VERSION ""

NS_ :

BS_:

BU_: TESTECU BIANSUXIANG SCR EBSECU DisPlay EngineECU

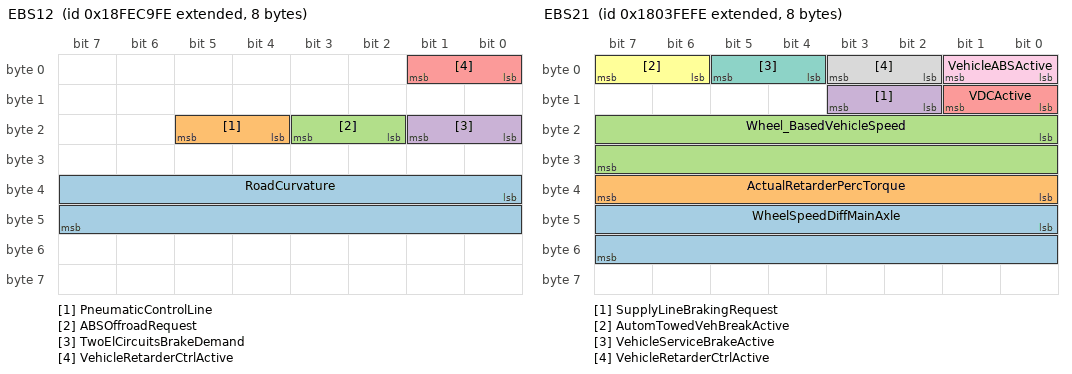
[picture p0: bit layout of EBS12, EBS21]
BO_ 2566834686 EBS12: 8 Vector__XXX
 SG_ RoadCurvature : 32|16@1+ (0.0078125,-250) [-250|251.992] "1/km" Vector__XXX
 SG_ PneumaticControlLine : 20|2@1+ (1,0) [0|1] "" Vector__XXX
 SG_ ABSOffroadRequest : 18|2@1+ (1,0) [0|1] "" Vector__XXX
 SG_ TwoElCircuitsBrakeDemand : 16|2@1+ (1,0) [0|1] "" Vector__XXX
 SG_ VehicleRetarderCtrlActive : 0|2@1+ (1,0) [0|3] "" Vector__XXX

BO_ 2550398718 EBS21: 8 Vector__XXX
 SG_ WheelSpeedDiffMainAxle : 40|16@1+ (0.00390625,-125) [-125|125] "km/hr" Vector__XXX
 SG_ ActualRetarderPercTorque : 32|8@1+ (1,-125) [-125|125] "%" Vector__XXX
 SG_ Wheel_BasedVehicleSpeed : 16|16@1+ (0.00390625,0) [0|251] "km/hr" Vector__XXX
 SG_ SupplyLineBrakingRequest : 10|2@1+ (1,0) [0|1] "" Vector__XXX
 SG_ VDCActive : 8|2@1+ (1,0) [0|1] "" Vector__XXX
 SG_ AutomTowedVehBreakActive : 6|2@1+ (1,0) [0|1] "" Vector__XXX
 SG_ VehicleServiceBrakeActive : 4|2@1+ (1,0) [0|1] "" Vector__XXX
 SG_ VehicleRetarderCtrlActive : 2|2@1+ (1,0) [0|3] "" Vector__XXX
 SG_ VehicleABSActive : 0|2@1+ (1,0) [0|1] "" Vector__XXX

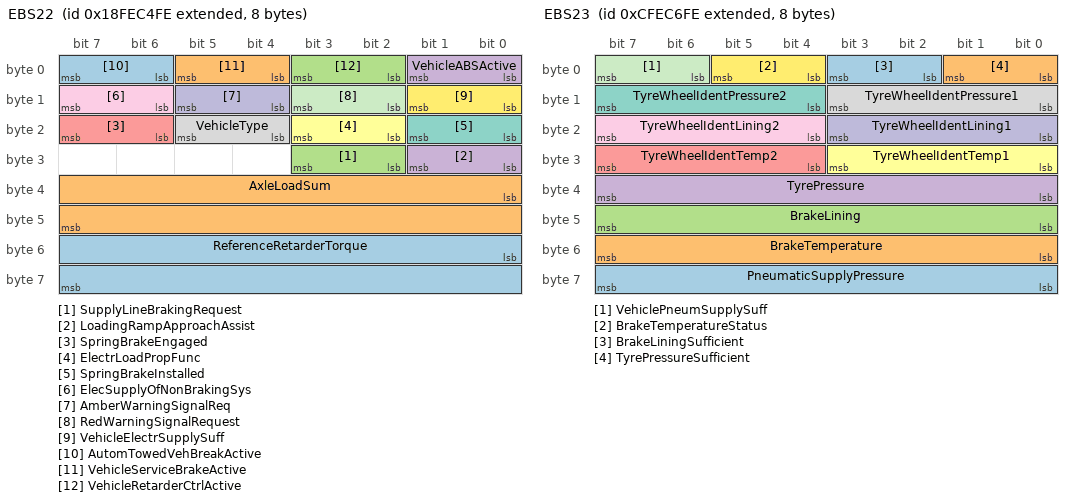
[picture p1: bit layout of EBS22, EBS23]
BO_ 2566833406 EBS22: 8 Vector__XXX
 SG_ ReferenceRetarderTorque : 48|16@1+ (1,0) [0|64255] "Nm" Vector__XXX
 SG_ AxleLoadSum : 32|16@1+ (2,0) [0|128510] "kg" Vector__XXX
 SG_ SupplyLineBrakingRequest : 26|2@1+ (1,0) [0|1] "" Vector__XXX
 SG_ LoadingRampApproachAssist : 24|2@1+ (1,0) [0|1] "" Vector__XXX
 SG_ SpringBrakeEngaged : 22|2@1+ (1,0) [0|1] "" Vector__XXX
 SG_ ElectrLoadPropFunc : 18|2@1+ (1,0) [0|1] "" Vector__XXX
 SG_ SpringBrakeInstalled : 16|2@1+ (1,0) [0|1] "" Vector__XXX
 SG_ VehicleType : 20|2@1+ (1,0) [0|3] "" Vector__XXX
 SG_ ElecSupplyOfNonBrakingSys : 14|2@1+ (1,0) [0|1] "" Vector__XXX
 SG_ AmberWarningSignalReq : 12|2@1+ (1,0) [0|1] "" Vector__XXX
 SG_ RedWarningSignalRequest : 10|2@1+ (1,0) [0|1] "" Vector__XXX
 SG_ VehicleElectrSupplySuff : 8|2@1+ (1,0) [0|1] "" Vector__XXX
 SG_ AutomTowedVehBreakActive : 6|2@1+ (1,0) [0|1] "" Vector__XXX
 SG_ VehicleServiceBrakeActive : 4|2@1+ (1,0) [0|1] "" Vector__XXX
 SG_ VehicleRetarderCtrlActive : 2|2@1+ (1,0) [0|3] "" Vector__XXX
 SG_ VehicleABSActive : 0|2@1+ (1,0) [0|1] "" Vector__XXX

BO_ 2365507326 EBS23: 8 Vector__XXX
 SG_ PneumaticSupplyPressure : 56|8@1+ (5,0) [0|1250] "kPa" Vector__XXX
 SG_ BrakeTemperature : 48|8@1+ (10,0) [0|2500] "°C" Vector__XXX
 SG_ BrakeLining : 40|8@1+ (0.4,0) [0|100] "%" Vector__XXX
 SG_ TyrePressure : 32|8@1+ (10,0) [0|2500] "kPa" Vector__XXX
 SG_ TyreWheelIdentTemp2 : 28|4@1+ (1,0) [0|15] "" Vector__XXX
 SG_ TyreWheelIdentTemp1 : 24|4@1+ (1,0) [0|15] "" Vector__XXX
 SG_ TyreWheelIdentPressure2 : 12|4@1+ (1,0) [0|15] "" Vector__XXX
 SG_ TyreWheelIdentPressure1 : 8|4@1+ (1,0) [0|15] "" Vector__XXX
 SG_ TyreWheelIdentLining2 : 20|4@1+ (1,0) [0|15] "" Vector__XXX
 SG_ TyreWheelIdentLining1 : 16|4@1+ (1,0) [0|15] "" Vector__XXX
 SG_ VehiclePneumSupplySuff : 6|2@1+ (1,0) [0|1] "" Vector__XXX
 SG_ BrakeTemperatureStatus : 4|2@1+ (1,0) [0|1] "" Vector__XXX
 SG_ BrakeLiningSufficient : 2|2@1+ (1,0) [0|1] "" Vector__XXX
 SG_ TyrePressureSufficient : 0|2@1+ (1,0) [0|1] "" Vector__XXX

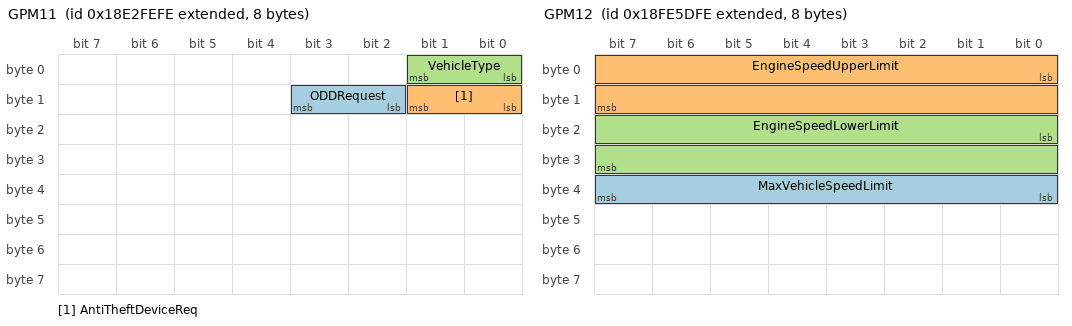
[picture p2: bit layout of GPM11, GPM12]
BO_ 2565013246 GPM11: 8 Vector__XXX
 SG_ ODDRequest : 10|2@1+ (1,0) [0|3] "" Vector__XXX
 SG_ AntiTheftDeviceReq : 8|2@1+ (1,0) [0|3] "" Vector__XXX
 SG_ VehicleType : 0|2@1+ (1,0) [0|3] "" Vector__XXX

BO_ 2566807038 GPM12: 8 Vector__XXX
 SG_ MaxVehicleSpeedLimit : 32|8@1+ (1,0) [0|250] "km/h" Vector__XXX
 SG_ EngineSpeedUpperLimit : 0|16@1+ (0.125,0) [0|8031.875] "rpm" Vector__XXX
 SG_ EngineSpeedLowerLimit : 16|16@1+ (0.125,0) [0|8191.875] "rpm" Vector__XXX

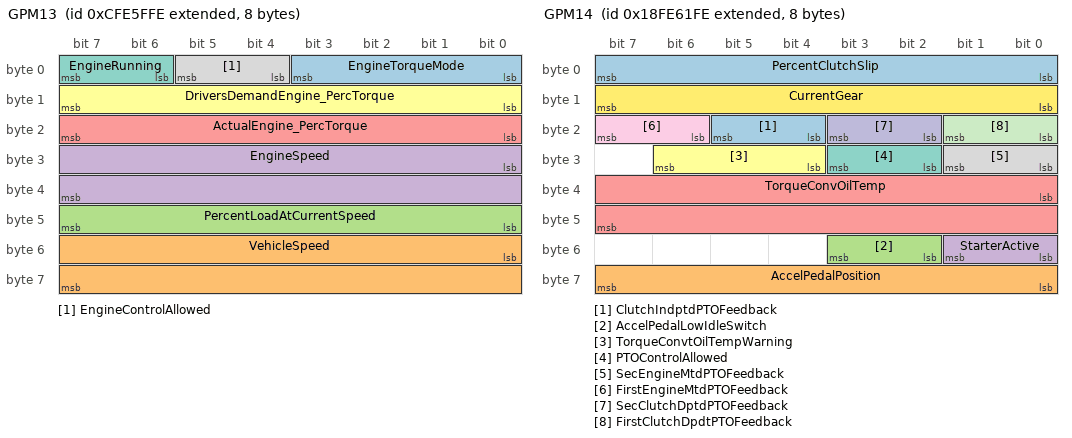
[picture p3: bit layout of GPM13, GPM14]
BO_ 2365480958 GPM13: 8 Vector__XXX
 SG_ EngineTorqueMode : 0|4@1+ (1,0) [0|15] "" Vector__XXX
 SG_ VehicleSpeed : 48|16@1+ (0.00390625,0) [0|250.996] "km/hr" Vector__XXX
 SG_ PercentLoadAtCurrentSpeed : 40|8@1+ (1,0) [0|125] "%" Vector__XXX
 SG_ EngineSpeed : 24|16@1+ (0.125,0) [0|8031.88] "rpm" Vector__XXX
 SG_ ActualEngine_PercTorque : 16|8@1+ (1,-125) [-125|125] "%" Vector__XXX
 SG_ DriversDemandEngine_PercTorque : 8|8@1+ (1,-125) [-125|125] "%" Vector__XXX
 SG_ EngineRunning : 6|2@1+ (1,0) [0|1] "" Vector__XXX
 SG_ EngineControlAllowed : 4|2@1+ (1,0) [0|1] "" Vector__XXX

BO_ 2566808062 GPM14: 8 Vector__XXX
 SG_ ClutchIndptdPTOFeedback : 20|2@1+ (1,0) [0|1] "" Vector__XXX
 SG_ AccelPedalPosition : 56|8@1+ (0.4,0) [0|100] "%" Vector__XXX
 SG_ AccelPedalLowIdleSwitch : 50|2@1+ (1,0) [0|1] "" Vector__XXX
 SG_ StarterActive : 48|2@1+ (1,0) [0|1] "" Vector__XXX
 SG_ TorqueConvOilTemp : 32|16@1+ (0.03125,-273) [-273|1735] "°C" Vector__XXX
 SG_ TorqueConvtOilTempWarning : 28|3@1+ (1,0) [0|2] "" Vector__XXX
 SG_ PTOControlAllowed : 26|2@1+ (1,0) [0|1] "" Vector__XXX
 SG_ SecEngineMtdPTOFeedback : 24|2@1+ (1,0) [0|1] "" Vector__XXX
 SG_ FirstEngineMtdPTOFeedback : 22|2@1+ (1,0) [0|1] "" Vector__XXX
 SG_ SecClutchDptdPTOFeedback : 18|2@1+ (1,0) [0|1] "" Vector__XXX
 SG_ FirstClutchDpdtPTOFeedback : 16|2@1+ (1,0) [0|1] "" Vector__XXX
 SG_ CurrentGear : 8|8@1+ (1,-125) [-125|125] "" Vector__XXX
 SG_ PercentClutchSlip : 0|8@1+ (0.4,0) [0|100] "%" Vector__XXX

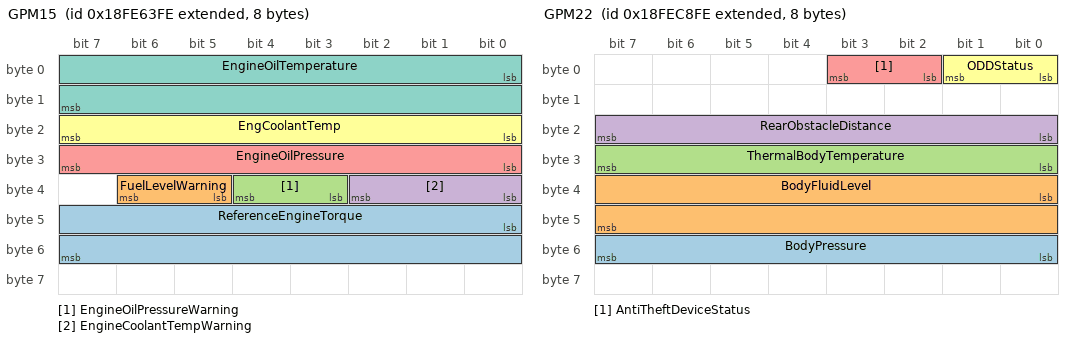
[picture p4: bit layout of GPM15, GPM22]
BO_ 2566808574 GPM15: 8 Vector__XXX
 SG_ ReferenceEngineTorque : 40|16@1+ (1,0) [0|64255] "Nm" Vector__XXX
 SG_ FuelLevelWarning : 37|2@1+ (1,0) [0|1] "" Vector__XXX
 SG_ EngineOilPressureWarning : 35|2@1+ (1,0) [0|1] "" Vector__XXX
 SG_ EngineCoolantTempWarning : 32|3@1+ (1,0) [0|2] "" Vector__XXX
 SG_ EngineOilPressure : 24|8@1+ (4,0) [0|1000] "kPa" Vector__XXX
 SG_ EngCoolantTemp : 16|8@1+ (1,-40) [-40|210] "deg C" Vector__XXX
 SG_ EngineOilTemperature : 0|16@1+ (0.03125,-273) [-273|1735] "°C" Vector__XXX

BO_ 2566809086 GPM16: 8 Vector__XXX
 SG_ AmbientAirTemperature : 0|16@1+ (0.03125,-273) [-273|1735] "°C" Vector__XXX

BO_ 2564947710 GPM21: 8 Vector__XXX
 SG_ VehicleType : 0|2@1+ (1,0) [0|3] "" Vector__XXX

BO_ 2566834430 GPM22: 8 Vector__XXX
 SG_ BodyPressure : 48|8@1+ (0.1,0) [0|25] "bar" Vector__XXX
 SG_ BodyFluidLevel : 32|16@1+ (2,0) [0|128510] "L" Vector__XXX
 SG_ ThermalBodyTemperature : 24|8@1+ (1,-125) [-125|125] "°C" Vector__XXX
 SG_ RearObstacleDistance : 16|8@1+ (2,0) [0|500] "cm" Vector__XXX
 SG_ AntiTheftDeviceStatus : 2|2@1+ (1,0) [0|1] "" Vector__XXX
 SG_ ODDStatus : 0|2@1+ (1,0) [0|1] "" Vector__XXX

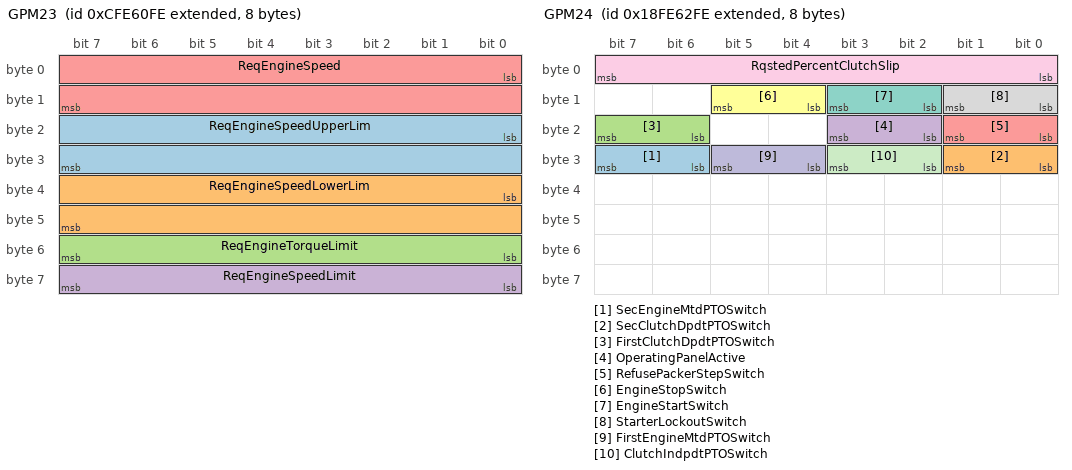
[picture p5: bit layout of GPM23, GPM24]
BO_ 2365481214 GPM23: 8 Vector__XXX
 SG_ ReqEngineSpeedUpperLim : 16|16@1+ (0.125,0) [0|8031.875] "rpm" Vector__XXX
 SG_ ReqEngineSpeedLowerLim : 32|16@1+ (0.125,0) [0|8031.875] "rpm" Vector__XXX
 SG_ ReqEngineTorqueLimit : 48|8@1+ (1,-125) [-125|125] "%" Vector__XXX
 SG_ ReqEngineSpeedLimit : 56|8@1+ (1,0) [0|250] "km/hr" Vector__XXX
 SG_ ReqEngineSpeed : 0|16@1+ (0.125,0) [0|8031.875] "rpm" Vector__XXX

BO_ 2566808318 GPM24: 8 Vector__XXX
 SG_ SecEngineMtdPTOSwitch : 30|2@1+ (1,0) [0|1] "" Vector__XXX
 SG_ SecClutchDpdtPTOSwitch : 24|2@1+ (1,0) [0|1] "" Vector__XXX
 SG_ FirstClutchDpdtPTOSwitch : 22|2@1+ (1,0) [0|1] "" Vector__XXX
 SG_ OperatingPanelActive : 18|2@1+ (1,0) [0|1] "" Vector__XXX
 SG_ RefusePackerStepSwitch : 16|2@1+ (1,0) [0|1] "" Vector__XXX
 SG_ EngineStopSwitch : 12|2@1+ (1,0) [0|1] "" Vector__XXX
 SG_ EngineStartSwitch : 10|2@1+ (1,0) [0|3] "" Vector__XXX
 SG_ StarterLockoutSwitch : 8|2@1+ (1,0) [0|1] "" Vector__XXX
 SG_ RqstedPercentClutchSlip : 0|8@1+ (0.4,0) [0|100] "%" Vector__XXX
 SG_ FirstEngineMtdPTOSwitch : 28|2@1+ (1,0) [0|1] "" Vector__XXX
 SG_ ClutchIndpdtPTOSwitch : 26|2@1+ (1,0) [0|1] "" Vector__XXX

BO_ 2566808830 GPM25: 8 Vector__XXX
 SG_ TrailerLeftSideMarkerLight : 20|2@1+ (1,0) [0|3] "" Vector__XXX
 SG_ TrailerLeftReversingLight : 16|2@1+ (1,0) [0|3] "" Vector__XXX
 SG_ TrailerLeftRearWidIndLight : 24|2@1+ (1,0) [0|3] "" Vector__XXX
 SG_ TrailerLeftRearRegPltLight : 32|2@1+ (1,0) [0|3] "" Vector__XXX
 SG_ TrailerLeftRearLight : 8|2@1+ (1,0) [0|3] "" Vector__XXX
 SG_ TrailerLeftRearFogLight : 12|2@1+ (1,0) [0|3] "" Vector__XXX
 SG_ TrailerLeftDirIndLight : 4|2@1+ (1,0) [0|3] "" Vector__XXX
 SG_ TrailerLeftCrnMarkerLight : 28|2@1+ (1,0) [0|3] "" Vector__XXX
 SG_ TrailerInteriorLight : 40|2@1+ (1,0) [0|3] "" Vector__XXX
 SG_ TrailerWorkLamp : 42|2@1+ (1,0) [0|3] "" Vector__XXX
 SG_ TrailerRotatingIdentLight : 38|2@1+ (1,0) [0|3] "" Vector__XXX
 SG_ TrailerRightStopLight : 2|2@1+ (1,0) [0|3] "" Vector__XXX
 SG_ TrailerRightSideMrkLight : 22|2@1+ (1,0) [0|3] "" Vector__XXX
 SG_ TrailerRightReversingLight : 18|2@1+ (1,0) [0|3] "" Vector__XXX
 SG_ TrailRightRearWidIndLight : 26|2@1+ (1,0) [0|3] "" Vector__XXX
 SG_ TrailerRightRearRegPltLight : 34|2@1+ (1,0) [0|3] "" Vector__XXX
 SG_ TrailerRightRearLight : 10|2@1+ (1,0) [0|3] "" Vector__XXX
 SG_ TrailerRightRearFogLight : 14|2@1+ (1,0) [0|3] "" Vector__XXX
 SG_ TrailerRightDirIndLight : 6|2@1+ (1,0) [0|3] "" Vector__XXX
 SG_ TrailerRightCrnMarkerLight : 30|2@1+ (1,0) [0|3] "" Vector__XXX
 SG_ TrailerRearWarningLight : 36|2@1+ (1,0) [0|3] "" Vector__XXX
 SG_ TrailerLeftStopLight : 0|2@1+ (1,0) [0|3] "" Vector__XXX

BO_ 2564554494 ISO15765_Funct: 8 Vector__XXX
 SG_ SN m2 : 0|4@1+ (1,0) [0|15] "" Vector__XXX
 SG_ SeparationTime m3 : 16|8@1+ (1,0) [0|255] "ms" Vector__XXX
 SG_ BlockSize m3 : 8|8@1+ (1,0) [0|255] "" Vector__XXX
 SG_ FlowStatus m3 : 0|4@1+ (1,0) [0|3] "" Vector__XXX
 SG_ FirstFrameDataLength m1 : 3|12@0+ (1,0) [0|4095] "Byte" Vector__XXX
 SG_ SingleFrameDataLength m0 : 0|4@1+ (1,0) [0|7] "Byte" Vector__XXX
 SG_ ProtocolCtrlInformation M : 4|4@1+ (1,0) [0|3] "" Vector__XXX

BO_ 2564488958 ISO15765_Phys: 8 Vector__XXX
 SG_ SN m2 : 0|4@1+ (1,0) [0|15] "" Vector__XXX
 SG_ SeparationTime m3 : 16|8@1+ (1,0) [0|255] "ms" Vector__XXX
 SG_ BlockSize m3 : 8|8@1+ (1,0) [0|255] "" Vector__XXX
 SG_ FlowStatus m3 : 0|4@1+ (1,0) [0|3] "" Vector__XXX
 SG_ FirstFrameDataLength m1 : 3|12@0+ (1,0) [0|4095] "Byte" Vector__XXX
 SG_ SingleFrameDataLength m0 : 0|4@1+ (1,0) [0|7] "Byte" Vector__XXX
 SG_ ProtocolCtrlInformation M : 4|4@1+ (1,0) [0|3] "" Vector__XXX

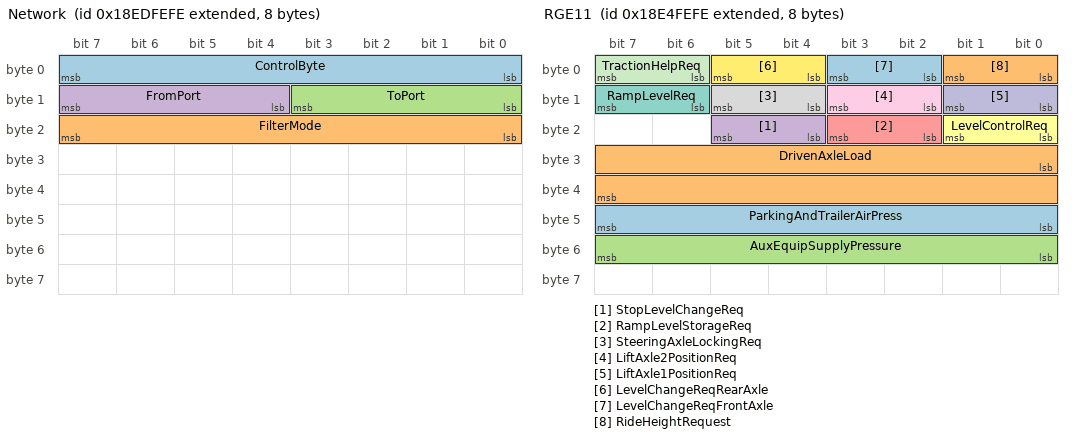
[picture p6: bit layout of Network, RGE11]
BO_ 2565734142 Network: 8 Vector__XXX
 SG_ ControlByte : 0|8@1+ (1,0) [0|255] "" Vector__XXX
 SG_ FilterMode : 16|8@1+ (1,0) [0|255] "" Vector__XXX
 SG_ ToPort : 8|4@1+ (1,0) [0|15] "" Vector__XXX
 SG_ FromPort : 12|4@1+ (1,0) [0|15] "" Vector__XXX

BO_ 2565144318 RGE11: 8 Vector__XXX
 SG_ ParkingAndTrailerAirPress : 40|8@1+ (8,0) [0|2000] "kPa" Vector__XXX
 SG_ DrivenAxleLoad : 24|16@1+ (2,0) [0|128510] "kg" Vector__XXX
 SG_ AuxEquipSupplyPressure : 48|8@1+ (8,0) [0|2000] "kPa" Vector__XXX
 SG_ StopLevelChangeReq : 20|2@1+ (1,0) [0|3] "" Vector__XXX
 SG_ RampLevelStorageReq : 18|2@1+ (1,0) [0|3] "" Vector__XXX
 SG_ LevelControlReq : 16|2@1+ (1,0) [0|3] "" Vector__XXX
 SG_ RampLevelReq : 14|2@1+ (1,0) [0|3] "" Vector__XXX
 SG_ SteeringAxleLockingReq : 12|2@1+ (1,0) [0|3] "" Vector__XXX
 SG_ LiftAxle2PositionReq : 10|2@1+ (1,0) [0|3] "" Vector__XXX
 SG_ LiftAxle1PositionReq : 8|2@1+ (1,0) [0|3] "" Vector__XXX
 SG_ TractionHelpReq : 6|2@1+ (1,0) [0|3] "" Vector__XXX
 SG_ LevelChangeReqRearAxle : 4|2@1+ (1,0) [0|3] "" Vector__XXX
 SG_ LevelChangeReqFrontAxle : 2|2@1+ (1,0) [0|3] "" Vector__XXX
 SG_ RideHeightRequest : 0|2@1+ (1,0) [0|3] "" Vector__XXX

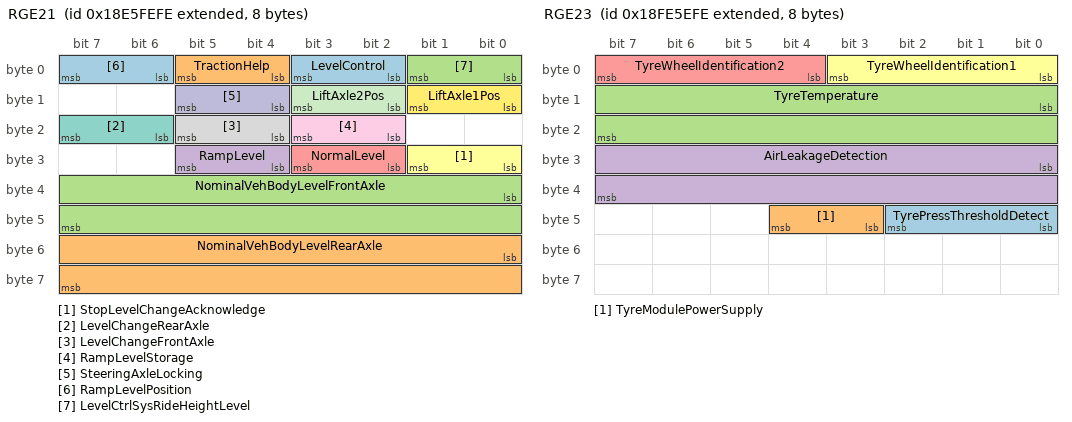
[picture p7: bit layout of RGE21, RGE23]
BO_ 2565209854 RGE21: 8 Vector__XXX
 SG_ LevelControl : 2|2@1+ (1,0) [0|1] "" Vector__XXX
 SG_ NominalVehBodyLevelRearAxle : 48|16@1+ (1,0) [0|64255] "mm" Vector__XXX
 SG_ NominalVehBodyLevelFrontAxle : 32|16@1+ (1,0) [0|64255] "mm" Vector__XXX
 SG_ RampLevel : 28|2@1+ (1,0) [0|1] "" Vector__XXX
 SG_ NormalLevel : 26|2@1+ (1,0) [0|3] "" Vector__XXX
 SG_ StopLevelChangeAcknowledge : 24|2@1+ (1,0) [0|1] "" Vector__XXX
 SG_ LevelChangeRearAxle : 22|2@1+ (1,0) [0|1] "" Vector__XXX
 SG_ LevelChangeFrontAxle : 20|2@1+ (1,0) [0|1] "" Vector__XXX
 SG_ RampLevelStorage : 18|2@1+ (1,0) [0|1] "" Vector__XXX
 SG_ SteeringAxleLocking : 12|2@1+ (1,0) [0|3] "" Vector__XXX
 SG_ LiftAxle2Pos : 10|2@1+ (1,0) [0|3] "" Vector__XXX
 SG_ LiftAxle1Pos : 8|2@1+ (1,0) [0|3] "" Vector__XXX
 SG_ RampLevelPosition : 6|2@1+ (1,0) [0|3] "" Vector__XXX
 SG_ TractionHelp : 4|2@1+ (1,0) [0|1] "" Vector__XXX
 SG_ LevelCtrlSysRideHeightLevel : 0|2@1+ (1,0) [0|1] "" Vector__XXX

BO_ 2566806782 RGE22: 8 Vector__XXX
 SG_ RelVehBodyLevelRearAxle : 16|16@1+ (1,0) [0|64255] "mm" Vector__XXX
 SG_ RelVehBodyLevelFrontAxle : 0|16@1+ (1,-32000) [-32000|32255] "mm" Vector__XXX

BO_ 2566807294 RGE23: 8 Vector__XXX
 SG_ TyrePressThresholdDetect : 40|3@1+ (1,0) [0|7] "" Vector__XXX
 SG_ TyreModulePowerSupply : 43|2@1+ (1,0) [0|1] "" Vector__XXX
 SG_ TyreTemperature : 8|16@1+ (0.03125,-273) [-273|1735] "°C" Vector__XXX
 SG_ AirLeakageDetection : 24|16@1+ (0.1,0) [0|6425.5] "Pa/s" Vector__XXX
 SG_ TyreWheelIdentification2 : 4|4@1+ (1,0) [0|15] "" Vector__XXX
 SG_ TyreWheelIdentification1 : 0|4@1+ (1,0) [0|15] "" Vector__XXX

BO_ 2566764798 DM26: 8 Vector__XXX
 SG_ NMHCConvertingCatalystCompleted : 60|1@1+ (1,0) [0|1] "" Vector__XXX
 SG_ NMHCConvertingCatalystEnabled : 44|1@1+ (1,0) [0|1] "" Vector__XXX
 SG_ NOxConvertingCatalystAdsorberCom : 59|1@1+ (1,0) [0|1] "" Vector__XXX
 SG_ NOxConvertingCatalystAdsorberEna : 43|1@1+ (1,0) [0|1] "" Vector__XXX
 SG_ DieselParticulateFilterCompleted : 58|1@1+ (1,0) [0|1] "" Vector__XXX
 SG_ DieselParticulateFilterEnabled : 42|1@1+ (1,0) [0|1] "" Vector__XXX
 SG_ BoostPressureControlSystemComple : 57|1@1+ (1,0) [0|1] "" Vector__XXX
 SG_ BoostPressureControlSystemEnable : 41|1@1- (1,0) [0|0] "" Vector__XXX
 SG_ MisfireMonitoringComplete : 28|1@1+ (1,0) [0|1] "" Vector__XXX
 SG_ MisfireMonitoringEnabled : 24|1@1+ (1,0) [0|0] "" Vector__XXX
 SG_ FuelSystemMonitoringEnabled : 25|1@1+ (1,0) [0|1] "" Vector__XXX
 SG_ ComprehensiveComptMonComplete : 30|1@1+ (1,0) [0|1] "" Vector__XXX
 SG_ ComprehensiveCompMonEnabled : 26|1@1+ (1,0) [0|1] "" Vector__XXX
 SG_ SecondAirSystemMonComplete : 51|1@1+ (1,0) [0|1] "" Vector__XXX
 SG_ SecondAirSystemMonEnabled : 35|1@1+ (1,0) [0|1] "" Vector__XXX
 SG_ OxygenSensorMonComplete : 53|1@1+ (1,0) [0|1] "" Vector__XXX
 SG_ OxygenSensorMonEnabled : 37|1@1+ (1,0) [0|1] "" Vector__XXX
 SG_ OxygenSensorHeaterMonComplete : 54|1@1+ (1,0) [0|1] "" Vector__XXX
 SG_ OxygenSensorHeaterMonEnabled : 38|1@1+ (1,0) [0|1] "" Vector__XXX
 SG_ HeatedCatalystMonComplete : 49|1@1+ (1,0) [0|1] "" Vector__XXX
 SG_ HeatedCatalystMonEnabled : 33|1@1+ (1,0) [0|1] "" Vector__XXX
 SG_ EvaporativeSystemMonComplete : 50|1@1+ (1,0) [0|1] "" Vector__XXX
 SG_ EvaporativeSystemMonEnabled : 34|1@1+ (1,0) [0|1] "" Vector__XXX
 SG_ EGRSystemMonitoringComplete : 55|1@1+ (1,0) [0|1] "" Vector__XXX
 SG_ EGRSystemMonitoringEnabled : 39|1@1+ (1,0) [0|1] "" Vector__XXX
 SG_ ColdStartAidSystemMonComplete : 56|1@1+ (1,0) [0|1] "" Vector__XXX
 SG_ ColdStartAidSystemMonEnabled : 40|1@1+ (1,0) [0|1] "" Vector__XXX
 SG_ CatalystMonComplete : 48|1@1+ (1,0) [0|1] "" Vector__XXX
 SG_ CatalystMonEnabled : 32|1@1+ (1,0) [0|1] "" Vector__XXX
 SG_ ACSystemRefrigerantMonComplete : 52|1@1+ (1,0) [0|1] "" Vector__XXX
 SG_ ACSystemRefrigerantMonEnabled : 36|1@1+ (1,0) [0|1] "" Vector__XXX
 SG_ FuelSystemMonitoringComplete : 29|1@1+ (1,0) [0|1] "" Vector__XXX
 SG_ NumOfWarmUpsSinceDTCsCleared : 16|8@1+ (1,0) [0|250] "" Vector__XXX
 SG_ TimeSinceEngineStart : 0|16@1+ (1,0) [0|64255] "sec" Vector__XXX

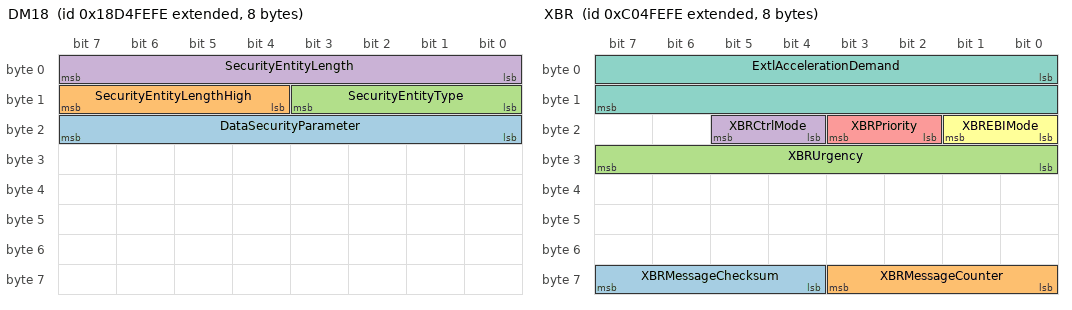
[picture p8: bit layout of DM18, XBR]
BO_ 2564095742 DM18: 8 Vector__XXX
 SG_ DataSecurityParameter : 16|8@1- (1,0) [0|1785] "" Vector__XXX
 SG_ SecurityEntityLengthHigh : 12|4@1+ (1,0) [0|255] "Byte" Vector__XXX
 SG_ SecurityEntityType : 8|4@1+ (1,0) [0|15] "" Vector__XXX
 SG_ SecurityEntityLength : 0|8@1+ (1,0) [0|1785] "Byte" Vector__XXX

BO_ 2349137662 XBR: 8 Vector__XXX
 SG_ XBRMessageChecksum : 60|4@1+ (1,0) [0|15] "" Vector__XXX
 SG_ XBRMessageCounter : 56|4@1+ (1,0) [0|15] "" Vector__XXX
 SG_ XBRUrgency : 24|8@1+ (0.4,0) [0|100] "%" Vector__XXX
 SG_ XBRCtrlMode : 20|2@1+ (1,0) [0|3] "" Vector__XXX
 SG_ XBRPriority : 18|2@1+ (1,0) [0|3] "" Vector__XXX
 SG_ XBREBIMode : 16|2@1+ (1,0) [0|3] "" Vector__XXX
 SG_ ExtlAccelerationDemand : 0|16@1+ (0.00048828125,-15.687) [-15.687|15.687] "m/s²" Vector__XXX

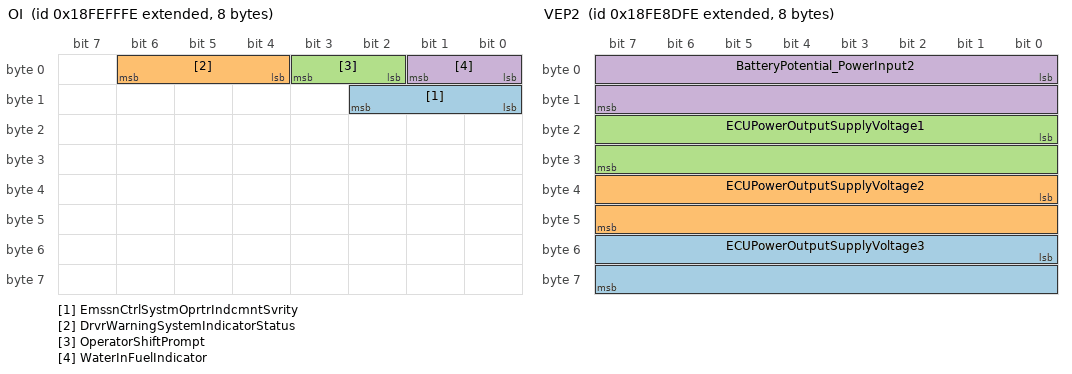
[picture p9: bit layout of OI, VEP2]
BO_ 2566848510 OI: 8 Vector__XXX
 SG_ EmssnCtrlSystmOprtrIndcmntSvrity : 8|3@1+ (1,0) [0|7] "" Vector__XXX
 SG_ DrvrWarningSystemIndicatorStatus : 4|3@1+ (1,0) [0|7] "" Vector__XXX
 SG_ OperatorShiftPrompt : 2|2@1+ (1,0) [0|3] "" Vector__XXX
 SG_ WaterInFuelIndicator : 0|2@1+ (1,0) [0|3] "" Vector__XXX

BO_ 2566843134 VW: 8 Vector__XXX
 SG_ AxleLocation M : 0|8@1+ (1,0) [0|255] "" Vector__XXX
 SG_ CargoWeight_30 m48 : 40|16@1+ (2,0) [0|128510] "kg" Vector__XXX
 SG_ CargoWeight_20 m32 : 40|16@1+ (2,0) [0|128510] "kg" Vector__XXX
 SG_ CargoWeight_10 m16 : 40|16@1+ (2,0) [0|128510] "kg" Vector__XXX
 SG_ CargoWeight_00 m0 : 40|16@1+ (2,0) [0|128510] "kg" Vector__XXX
 SG_ TrailerWeight_30 m48 : 24|16@1+ (2,0) [0|128510] "kg" Vector__XXX
 SG_ TrailerWeight_20 m32 : 24|16@1+ (2,0) [0|128510] "kg" Vector__XXX
 SG_ TrailerWeight_10 m16 : 24|16@1+ (2,0) [0|128510] "kg" Vector__XXX
 SG_ TrailerWeight_00 m0 : 24|16@1+ (2,0) [0|128510] "kg" Vector__XXX
 SG_ AxleWeight_30 m48 : 8|16@1+ (0.5,0) [0|32127.5] "kg" Vector__XXX
 SG_ AxleWeight_20 m32 : 8|16@1+ (0.5,0) [0|32127.5] "kg" Vector__XXX
 SG_ AxleWeight_10 m16 : 8|16@1+ (0.5,0) [0|32127.5] "kg" Vector__XXX
 SG_ AxleWeight_00 m0 : 8|16@1+ (0.5,0) [0|32127.5] "kg" Vector__XXX

BO_ 2566804222 VEP3: 8 Vector__XXX
 SG_ NetBatteryCurrent : 16|16@1+ (0.05,-1600) [-1600|1612.75] "A" Vector__XXX
 SG_ AltCurrent : 0|16@1+ (0.05,-1600) [-1600|1612.75] "A" Vector__XXX

BO_ 2566819326 VEP2: 8 Vector__XXX
 SG_ ECUPowerOutputSupplyVoltage3 : 48|16@1+ (0.05,0) [0|3212.75] "V" Vector__XXX
 SG_ ECUPowerOutputSupplyVoltage2 : 32|16@1+ (0.05,0) [0|3212.75] "V" Vector__XXX
 SG_ ECUPowerOutputSupplyVoltage1 : 16|16@1+ (0.05,0) [0|3212.75] "V" Vector__XXX
 SG_ BatteryPotential_PowerInput2 : 0|16@1+ (0.05,0) [0|3212.75] "V" Vector__XXX

BO_ 2566845438 VP: 8 Vector__XXX
 SG_ Longitude : 32|32@1+ (1E-007,-210) [-210|211.1008122] "deg" Vector__XXX
 SG_ Latitude : 0|32@1+ (1E-007,-210) [-210|211.1008122] "deg" Vector__XXX

BO_ 2566843646 VI: 8 Vector__XXX
 SG_ VehicleIdentificationNumber : 0|8@1+ (1,0) [0|255] "per byte" Vector__XXX

BO_ 2566842366 VH: 8 Vector__XXX
 SG_ TotalPowerTakeoffHours : 32|32@1+ (0.05,0) [0|210554060.75] "hr" Vector__XXX
 SG_ TotalVehicleHours : 0|32@1+ (0.05,0) [0|210554060.75] "hr" Vector__XXX

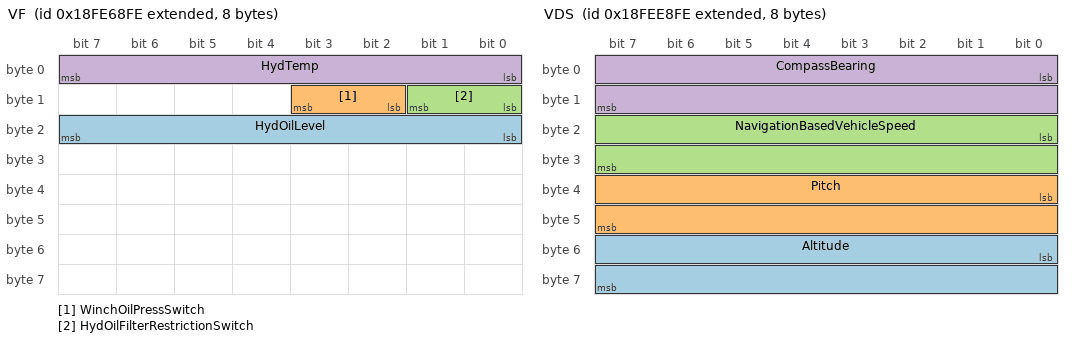
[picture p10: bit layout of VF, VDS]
BO_ 2566809854 VF: 8 Vector__XXX
 SG_ HydOilLevel : 16|8@1+ (0.4,0) [0|100] "%" Vector__XXX
 SG_ WinchOilPressSwitch : 10|2@1+ (1,0) [0|3] "" Vector__XXX
 SG_ HydOilFilterRestrictionSwitch : 8|2@1+ (1,0) [0|3] "" Vector__XXX
 SG_ HydTemp : 0|8@1+ (1,-40) [-40|210] "deg C" Vector__XXX

BO_ 2566842622 VDS: 8 Vector__XXX
 SG_ Altitude : 48|16@1+ (0.125,-2500) [-2500|5531.875] "m" Vector__XXX
 SG_ Pitch : 32|16@1+ (0.0078125,-200) [-200|301.99] "deg" Vector__XXX
 SG_ NavigationBasedVehicleSpeed : 16|16@1+ (0.00390625,0) [0|250.996] "km/h" Vector__XXX
 SG_ CompassBearing : 0|16@1+ (0.0078125,0) [0|501.99] "deg" Vector__XXX

BO_ 2566832638 VDHR: 8 Vector__XXX
 SG_ HighResolutionTripDistance : 32|32@1+ (5,0) [0|21055406] "km" Vector__XXX
 SG_ HghRsolutionTotalVehicleDistance : 0|32@1+ (5,0) [0|21055406] "km" Vector__XXX

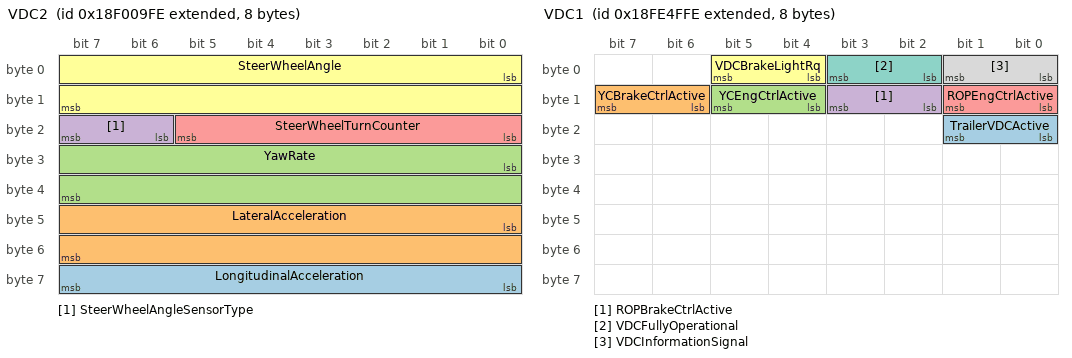
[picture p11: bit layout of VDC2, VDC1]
BO_ 2565868030 VDC2: 8 Vector__XXX
 SG_ LongitudinalAcceleration : 56|8@1+ (0.1,-12.5) [-12.5|12.5] "m/s²" Vector__XXX
 SG_ LateralAcceleration : 40|16@1+ (0.00048828125,-15.687) [-15.687|15.687] "m/s²" Vector__XXX
 SG_ YawRate : 24|16@1+ (0.0001220703125,-3.92) [-3.92|3.92] "rad/s" Vector__XXX
 SG_ SteerWheelAngleSensorType : 22|2@1+ (1,0) [0|3] "" Vector__XXX
 SG_ SteerWheelTurnCounter : 16|6@1+ (1,-32) [-32|29] "turns" Vector__XXX
 SG_ SteerWheelAngle : 0|16@1+ (0.0009765625,-31.374) [-31.374|31.374] "rad" Vector__XXX

BO_ 2566803454 VDC1: 8 Vector__XXX
 SG_ TrailerVDCActive : 16|2@1+ (1,0) [0|3] "" Vector__XXX
 SG_ YCBrakeCtrlActive : 14|2@1+ (1,0) [0|3] "" Vector__XXX
 SG_ YCEngCtrlActive : 12|2@1+ (1,0) [0|3] "" Vector__XXX
 SG_ ROPBrakeCtrlActive : 10|2@1+ (1,0) [0|3] "" Vector__XXX
 SG_ ROPEngCtrlActive : 8|2@1+ (1,0) [0|3] "" Vector__XXX
 SG_ VDCBrakeLightRq : 4|2@1+ (1,0) [0|3] "" Vector__XXX
 SG_ VDCFullyOperational : 2|2@1+ (1,0) [0|3] "" Vector__XXX
 SG_ VDCInformationSignal : 0|2@1+ (1,0) [0|3] "" Vector__XXX

BO_ 2566840574 VD: 8 Vector__XXX
 SG_ TotalVehicleDistance : 32|32@1+ (0.125,0) [0|526385151.9] "km" Vector__XXX
 SG_ TripDistance : 0|32@1+ (0.125,0) [0|526385151.9] "km" Vector__XXX

BO_ 2633938686 TVI: 8 Vector__XXX
 SG_ TripCruiseDistance : 16|32@1+ (0.125,0) [0|526385151.9] "km" Vector__XXX
 SG_ TripMaxVehicleSpeed : 0|16@1+ (0.00390625,0) [0|250.996] "km/h" Vector__XXX

BO_ 2633937150 TTI2: 20 Vector__XXX
 SG_ TripAirCompressorOnTime : 128|32@1+ (0.05,0) [0|210554060.75] "hr" Vector__XXX
 SG_ TripIdleTime : 96|32@1+ (0.05,0) [0|210554060.75] "hr" Vector__XXX
 SG_ TripEngRunningTime : 64|32@1+ (0.05,0) [0|210554060.75] "hr" Vector__XXX
 SG_ TripCruiseTime : 0|32@1+ (0.05,0) [0|210554060.75] "hr" Vector__XXX
 SG_ TripPTOGovernorTime : 32|32@1+ (0.05,0) [0|210554060.75] "hr" Vector__XXX

BO_ 2633938174 TTI1: 16 Vector__XXX
 SG_ TripTimeInDerateByEng : 96|32@1+ (0.05,0) [0|210554060.75] "hr" Vector__XXX
 SG_ TripTimeInGearDown : 64|32@1+ (0.05,0) [0|210554060.75] "hr" Vector__XXX
 SG_ TripTimeInTopGear : 32|32@1+ (0.05,0) [0|210554060.75] "hr" Vector__XXX
 SG_ TripTimeInVSL : 0|32@1+ (0.05,0) [0|210554060.75] "hr" Vector__XXX

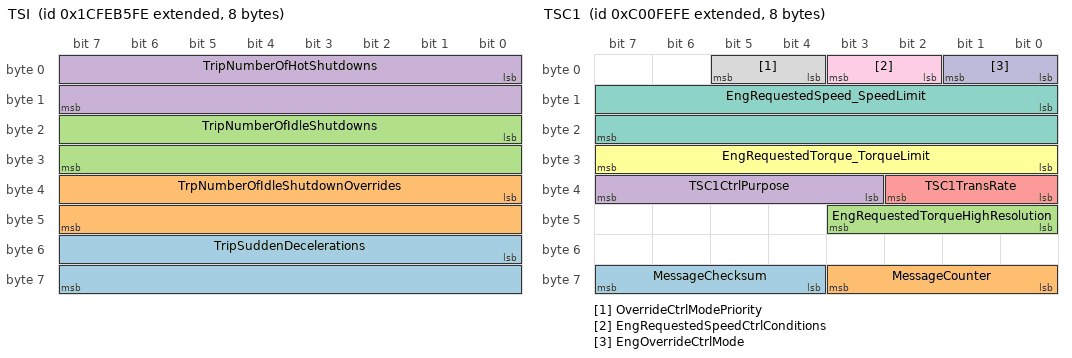
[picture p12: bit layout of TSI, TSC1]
BO_ 2633938430 TSI: 8 Vector__XXX
 SG_ TripSuddenDecelerations : 48|16@1+ (1,0) [0|64255] "" Vector__XXX
 SG_ TrpNumberOfIdleShutdownOverrides : 32|16@1+ (1,0) [0|64255] "" Vector__XXX
 SG_ TripNumberOfIdleShutdowns : 16|16@1+ (1,0) [0|64255] "" Vector__XXX
 SG_ TripNumberOfHotShutdowns : 0|16@1+ (1,0) [0|64255] "" Vector__XXX

BO_ 2348875518 TSC1: 8 Vector__XXX
 SG_ MessageChecksum : 60|4@1+ (1,0) [0|15] "" Vector__XXX
 SG_ MessageCounter : 56|4@1+ (1,0) [0|15] "" Vector__XXX
 SG_ EngRequestedTorqueHighResolution : 40|4@1+ (0.125,0) [0|0.875] "%" Vector__XXX
 SG_ TSC1CtrlPurpose : 35|5@1+ (1,0) [0|31] "" Vector__XXX
 SG_ TSC1TransRate : 32|3@1+ (1,0) [0|7] "" Vector__XXX
 SG_ EngRequestedTorque_TorqueLimit : 24|8@1+ (1,-125) [-125|125] "%" Vector__XXX
 SG_ EngRequestedSpeed_SpeedLimit : 8|16@1+ (0.125,0) [0|8031.875] "rpm" Vector__XXX
 SG_ OverrideCtrlModePriority : 4|2@1+ (1,0) [0|3] "" Vector__XXX
 SG_ EngRequestedSpeedCtrlConditions : 2|2@1+ (1,0) [0|3] "" Vector__XXX
 SG_ EngOverrideCtrlMode : 0|2@1+ (1,0) [0|3] "" Vector__XXX

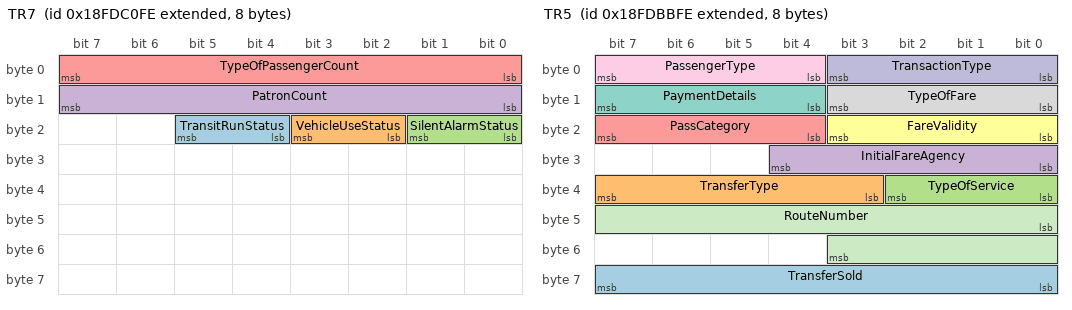
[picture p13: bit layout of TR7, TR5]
BO_ 2566766846 TR7: 8 Vector__XXX
 SG_ TransitRunStatus : 20|2@1+ (1,0) [0|3] "" Vector__XXX
 SG_ VehicleUseStatus : 18|2@1+ (1,0) [0|3] "" Vector__XXX
 SG_ SilentAlarmStatus : 16|2@1+ (1,0) [0|3] "" Vector__XXX
 SG_ PatronCount : 8|8@1+ (1,0) [0|250] "" Vector__XXX
 SG_ TypeOfPassengerCount : 0|8@1+ (1,0) [0|255] "" Vector__XXX

BO_ 2566765310 TR6: 8 Vector__XXX
 SG_ FareboxAlarmIdentifier : 8|7@1+ (1,0) [0|127] "" Vector__XXX
 SG_ FareboxEmergencyStatus : 0|2@1+ (1,0) [0|3] "" Vector__XXX

BO_ 2566765566 TR5: 8 Vector__XXX
 SG_ TransferSold : 56|8@1+ (1,0) [0|255] "" Vector__XXX
 SG_ TransferType : 35|5@1+ (1,0) [0|31] "" Vector__XXX
 SG_ TypeOfService : 32|3@1+ (1,0) [0|7] "" Vector__XXX
 SG_ InitialFareAgency : 24|5@1+ (1,0) [0|31] "" Vector__XXX
 SG_ PassCategory : 20|4@1+ (1,0) [0|15] "" Vector__XXX
 SG_ FareValidity : 16|4@1+ (1,0) [0|15] "" Vector__XXX
 SG_ PaymentDetails : 12|4@1+ (1,0) [0|15] "" Vector__XXX
 SG_ TypeOfFare : 8|4@1+ (1,0) [0|15] "" Vector__XXX
 SG_ PassengerType : 4|4@1+ (1,0) [0|15] "" Vector__XXX
 SG_ TransactionType : 0|4@1+ (1,0) [0|15] "" Vector__XXX
 SG_ RouteNumber : 40|12@1+ (1,0) [0|4095] "" Vector__XXX

BO_ 2566765822 TR4: 15 Vector__XXX
 SG_ DriversFareboxSecurityCode : 104|16@1+ (1,0) [0|65535] "" Vector__XXX
 SG_ AssignedBlock : 88|16@1+ (1,0) [0|65535] "" Vector__XXX
 SG_ AssignedRun : 72|16@1+ (1,0) [0|65535] "" Vector__XXX
 SG_ AssignedRoute : 56|16@1+ (1,0) [0|65535] "" Vector__XXX
 SG_ PatternNumber : 40|16@1+ (1,0) [0|65535] "" Vector__XXX
 SG_ TripNumber : 24|16@1+ (1,0) [0|65535] "" Vector__XXX
 SG_ FarePresets : 16|8@1+ (1,0) [0|255] "" Vector__XXX
 SG_ TripDirection : 8|4@1+ (1,0) [0|15] "" Vector__XXX
 SG_ TripStatus : 2|3@1+ (1,0) [0|7] "" Vector__XXX
 SG_ FareboxServiceStatus : 0|2@1+ (1,0) [0|3] "" Vector__XXX

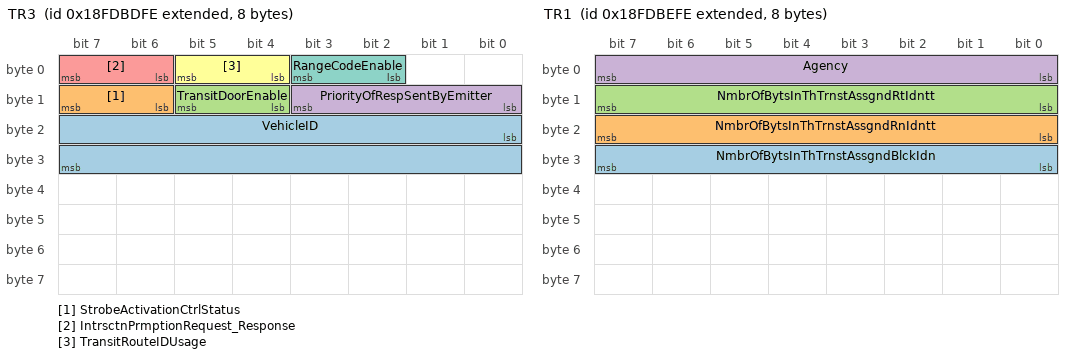
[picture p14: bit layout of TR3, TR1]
BO_ 2566766078 TR3: 8 Vector__XXX
 SG_ VehicleID : 16|16@1+ (1,0) [0|65535] "" Vector__XXX
 SG_ StrobeActivationCtrlStatus : 14|2@1+ (1,0) [0|3] "" Vector__XXX
 SG_ TransitDoorEnable : 12|2@1+ (1,0) [0|3] "" Vector__XXX
 SG_ PriorityOfRespSentByEmitter : 8|4@1+ (1,0) [0|15] "" Vector__XXX
 SG_ IntrsctnPrmptionRequest_Response : 6|2@1+ (1,0) [0|3] "" Vector__XXX
 SG_ TransitRouteIDUsage : 4|2@1+ (1,0) [0|3] "" Vector__XXX
 SG_ RangeCodeEnable : 2|2@1+ (1,0) [0|3] "" Vector__XXX

BO_ 2566766590 TR2: 8 Vector__XXX
 SG_ NmbrOfBytsInThMlpstIdntification : 0|8@1+ (1,0) [0|250] "bytes" Vector__XXX

BO_ 2566766334 TR1: 8 Vector__XXX
 SG_ NmbrOfBytsInThTrnstAssgndBlckIdn : 24|8@1+ (1,0) [0|250] "bytes" Vector__XXX
 SG_ NmbrOfBytsInThTrnstAssgndRnIdntt : 16|8@1+ (1,0) [0|250] "bytes" Vector__XXX
 SG_ NmbrOfBytsInThTrnstAssgndRtIdntt : 8|8@1+ (1,0) [0|250] "bytes" Vector__XXX
 SG_ Agency : 0|8@1+ (1,0) [0|255] "" Vector__XXX

BO_ 2561605374 TPRS: 8 Vector__XXX
 SG_ ReferenceTirePressSetting_33 m51 : 8|8@1+ (8,0) [0|2000] "kPa" Vector__XXX
 SG_ ReferenceTirePressSetting_32 m50 : 8|8@1+ (8,0) [0|2000] "kPa" Vector__XXX
 SG_ ReferenceTirePressSetting_31 m49 : 8|8@1+ (8,0) [0|2000] "kPa" Vector__XXX
 SG_ ReferenceTirePressSetting_30 m48 : 8|8@1+ (8,0) [0|2000] "kPa" Vector__XXX
 SG_ ReferenceTirePressSetting_23 m35 : 8|8@1+ (8,0) [0|2000] "kPa" Vector__XXX
 SG_ ReferenceTirePressSetting_22 m34 : 8|8@1+ (8,0) [0|2000] "kPa" Vector__XXX
 SG_ ReferenceTirePressSetting_21 m33 : 8|8@1+ (8,0) [0|2000] "kPa" Vector__XXX
 SG_ ReferenceTirePressSetting_20 m32 : 8|8@1+ (8,0) [0|2000] "kPa" Vector__XXX
 SG_ ReferenceTirePressSetting_13 m19 : 8|8@1+ (8,0) [0|2000] "kPa" Vector__XXX
 SG_ ReferenceTirePressSetting_12 m18 : 8|8@1+ (8,0) [0|2000] "kPa" Vector__XXX
 SG_ ReferenceTirePressSetting_11 m17 : 8|8@1+ (8,0) [0|2000] "kPa" Vector__XXX
 SG_ ReferenceTirePressSetting_10 m16 : 8|8@1+ (8,0) [0|2000] "kPa" Vector__XXX
 SG_ ReferenceTirePressSetting_01 m1 : 8|8@1+ (8,0) [0|2000] "kPa" Vector__XXX
 SG_ ReferenceTirePressSetting_00 m0 : 8|8@1+ (8,0) [0|2000] "kPa" Vector__XXX
 SG_ TireLocation M : 0|8@1+ (1,0) [0|255] "" Vector__XXX

BO_ 2566765054 TPRI: 8 Vector__XXX
 SG_ ReferenceTirePress_33 m51 : 8|8@1+ (8,0) [0|2000] "kPa" Vector__XXX
 SG_ ReferenceTirePress_32 m50 : 8|8@1+ (8,0) [0|2000] "kPa" Vector__XXX
 SG_ ReferenceTirePress_31 m49 : 8|8@1+ (8,0) [0|2000] "kPa" Vector__XXX
 SG_ ReferenceTirePress_30 m48 : 8|8@1+ (8,0) [0|2000] "kPa" Vector__XXX
 SG_ ReferenceTirePress_23 m35 : 8|8@1+ (8,0) [0|2000] "kPa" Vector__XXX
 SG_ ReferenceTirePress_22 m34 : 8|8@1+ (8,0) [0|2000] "kPa" Vector__XXX
 SG_ ReferenceTirePress_21 m33 : 8|8@1+ (8,0) [0|2000] "kPa" Vector__XXX
 SG_ ReferenceTirePress_20 m32 : 8|8@1+ (8,0) [0|2000] "kPa" Vector__XXX
 SG_ ReferenceTirePress_13 m19 : 8|8@1+ (8,0) [0|2000] "kPa" Vector__XXX
 SG_ ReferenceTirePress_12 m18 : 8|8@1+ (8,0) [0|2000] "kPa" Vector__XXX
 SG_ ReferenceTirePress_11 m17 : 8|8@1+ (8,0) [0|2000] "kPa" Vector__XXX
 SG_ ReferenceTirePress_10 m16 : 8|8@1+ (8,0) [0|2000] "kPa" Vector__XXX
 SG_ ReferenceTirePress_01 m1 : 8|8@1+ (8,0) [0|2000] "kPa" Vector__XXX
 SG_ ReferenceTirePress_00 m0 : 8|8@1+ (8,0) [0|2000] "kPa" Vector__XXX
 SG_ TireLocation M : 0|8@1+ (1,0) [0|255] "" Vector__XXX

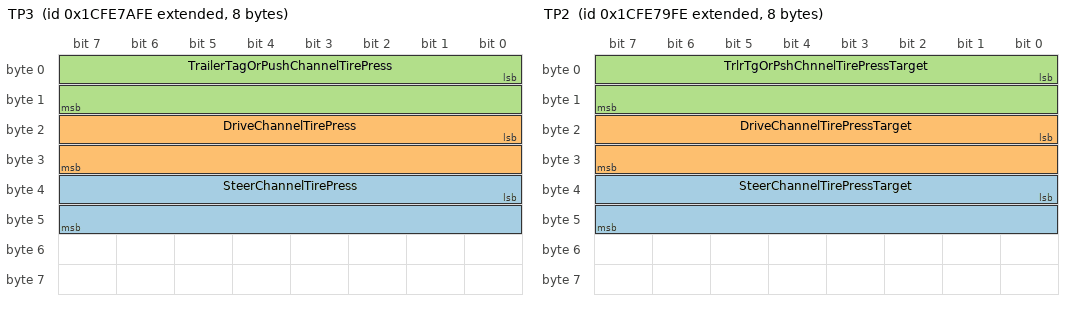
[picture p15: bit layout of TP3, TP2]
BO_ 2633923326 TP3: 8 Vector__XXX
 SG_ SteerChannelTirePress : 32|16@1+ (0.5,0) [0|32127.5] "kPa" Vector__XXX
 SG_ DriveChannelTirePress : 16|16@1+ (0.5,0) [0|32127.5] "kPa" Vector__XXX
 SG_ TrailerTagOrPushChannelTirePress : 0|16@1+ (0.5,0) [0|32127.5] "kPa" Vector__XXX

BO_ 2633923070 TP2: 8 Vector__XXX
 SG_ SteerChannelTirePressTarget : 32|16@1+ (0.5,0) [0|32127.5] "kPa" Vector__XXX
 SG_ DriveChannelTirePressTarget : 16|16@1+ (0.5,0) [0|32127.5] "kPa" Vector__XXX
 SG_ TrlrTgOrPshChnnelTirePressTarget : 0|16@1+ (0.5,0) [0|32127.5] "kPa" Vector__XXX

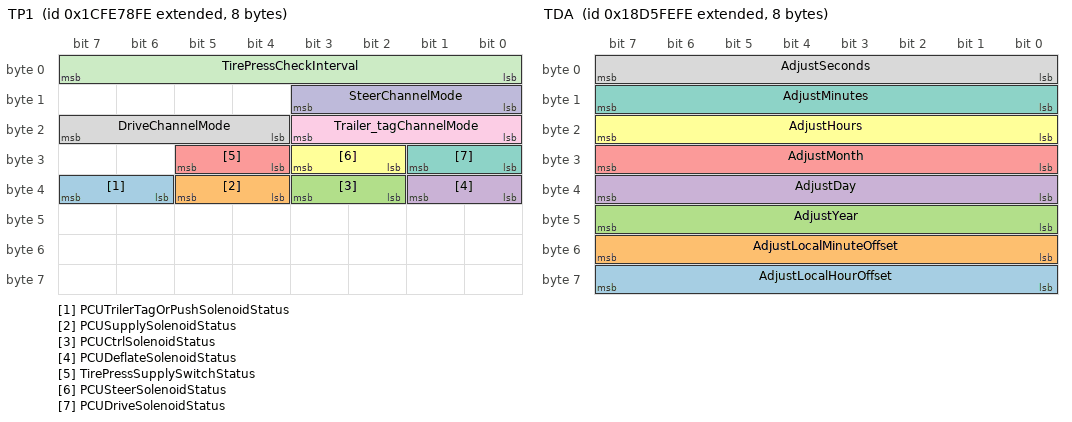
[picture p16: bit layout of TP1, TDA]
BO_ 2633922814 TP1: 8 Vector__XXX
 SG_ PCUTrilerTagOrPushSolenoidStatus : 38|2@1+ (1,0) [0|3] "" Vector__XXX
 SG_ PCUSupplySolenoidStatus : 36|2@1+ (1,0) [0|3] "" Vector__XXX
 SG_ PCUCtrlSolenoidStatus : 34|2@1+ (1,0) [0|3] "" Vector__XXX
 SG_ PCUDeflateSolenoidStatus : 32|2@1+ (1,0) [0|3] "" Vector__XXX
 SG_ TirePressSupplySwitchStatus : 28|2@1+ (1,0) [0|3] "" Vector__XXX
 SG_ PCUSteerSolenoidStatus : 26|2@1+ (1,0) [0|3] "" Vector__XXX
 SG_ PCUDriveSolenoidStatus : 24|2@1+ (1,0) [0|3] "" Vector__XXX
 SG_ DriveChannelMode : 20|4@1+ (1,0) [0|15] "" Vector__XXX
 SG_ Trailer_tagChannelMode : 16|4@1+ (1,0) [0|15] "" Vector__XXX
 SG_ SteerChannelMode : 8|4@1+ (1,0) [0|15] "" Vector__XXX
 SG_ TirePressCheckInterval : 0|8@1+ (1,0) [0|250] "mins" Vector__XXX

BO_ 2566845694 TIRE: 8 Vector__XXX
 SG_ TirePressThresholdDetection_13 m19 : 61|3@1+ (1,0) [0|7] "" Vector__XXX
 SG_ TirePressThresholdDetection_12 m18 : 61|3@1+ (1,0) [0|7] "" Vector__XXX
 SG_ TirePressThresholdDetection_11 m17 : 61|3@1+ (1,0) [0|7] "" Vector__XXX
 SG_ TirePressThresholdDetection_10 m16 : 61|3@1+ (1,0) [0|7] "" Vector__XXX
 SG_ TirePressThresholdDetection_01 m1 : 61|3@1+ (1,0) [0|7] "" Vector__XXX
 SG_ TirePress_33 m51 : 8|8@1+ (4,0) [0|1000] "kPa" Vector__XXX
 SG_ TirePress_32 m50 : 8|8@1+ (4,0) [0|1000] "kPa" Vector__XXX
 SG_ TirePress_31 m49 : 8|8@1+ (4,0) [0|1000] "kPa" Vector__XXX
 SG_ TirePress_30 m48 : 8|8@1+ (4,0) [0|1000] "kPa" Vector__XXX
 SG_ TirePress_23 m35 : 8|8@1+ (4,0) [0|1000] "kPa" Vector__XXX
 SG_ TirePress_22 m34 : 8|8@1+ (4,0) [0|1000] "kPa" Vector__XXX
 SG_ TirePress_21 m33 : 8|8@1+ (4,0) [0|1000] "kPa" Vector__XXX
 SG_ TirePress_20 m32 : 8|8@1+ (4,0) [0|1000] "kPa" Vector__XXX
 SG_ TirePress_13 m19 : 8|8@1+ (4,0) [0|1000] "kPa" Vector__XXX
 SG_ TirePress_12 m18 : 8|8@1+ (4,0) [0|1000] "kPa" Vector__XXX
 SG_ TirePress_11 m17 : 8|8@1+ (4,0) [0|1000] "kPa" Vector__XXX
 SG_ TirePress_10 m16 : 8|8@1+ (4,0) [0|1000] "kPa" Vector__XXX
 SG_ TireAirLeakageRate_33 m51 : 40|16@1+ (0.1,0) [0|6425.5] "Pa/s" Vector__XXX
 SG_ TireAirLeakageRate_32 m50 : 40|16@1+ (0.1,0) [0|6425.5] "Pa/s" Vector__XXX
 SG_ TireAirLeakageRate_31 m49 : 40|16@1+ (0.1,0) [0|6425.5] "Pa/s" Vector__XXX
 SG_ TireAirLeakageRate_30 m48 : 40|16@1+ (0.1,0) [0|6425.5] "Pa/s" Vector__XXX
 SG_ TireAirLeakageRate_23 m35 : 40|16@1+ (0.1,0) [0|6425.5] "Pa/s" Vector__XXX
 SG_ TireAirLeakageRate_22 m34 : 40|16@1+ (0.1,0) [0|6425.5] "Pa/s" Vector__XXX
 SG_ TireAirLeakageRate_21 m33 : 40|16@1+ (0.1,0) [0|6425.5] "Pa/s" Vector__XXX
 SG_ TireAirLeakageRate_20 m32 : 40|16@1+ (0.1,0) [0|6425.5] "Pa/s" Vector__XXX
 SG_ TireAirLeakageRate_13 m19 : 40|16@1+ (0.1,0) [0|6425.5] "Pa/s" Vector__XXX
 SG_ TireAirLeakageRate_12 m18 : 40|16@1+ (0.1,0) [0|6425.5] "Pa/s" Vector__XXX
 SG_ TireAirLeakageRate_11 m17 : 40|16@1+ (0.1,0) [0|6425.5] "Pa/s" Vector__XXX
 SG_ TireAirLeakageRate_10 m16 : 40|16@1+ (0.1,0) [0|6425.5] "Pa/s" Vector__XXX
 SG_ TireAirLeakageRate_01 m1 : 40|16@1+ (0.1,0) [0|6425.5] "Pa/s" Vector__XXX
 SG_ TireAirLeakageRate_00 m0 : 40|16@1+ (0.1,0) [0|6425.5] "Pa/s" Vector__XXX
 SG_ CTIWheelSensorStatus_33 m51 : 32|2@1+ (1,0) [0|3] "" Vector__XXX
 SG_ CTIWheelSensorStatus_32 m50 : 32|2@1+ (1,0) [0|3] "" Vector__XXX
 SG_ CTIWheelSensorStatus_31 m49 : 32|2@1+ (1,0) [0|3] "" Vector__XXX
 SG_ CTIWheelSensorStatus_30 m48 : 32|2@1+ (1,0) [0|3] "" Vector__XXX
 SG_ CTIWheelSensorStatus_23 m35 : 32|2@1+ (1,0) [0|3] "" Vector__XXX
 SG_ CTIWheelSensorStatus_22 m34 : 32|2@1+ (1,0) [0|3] "" Vector__XXX
 SG_ CTIWheelSensorStatus_21 m33 : 32|2@1+ (1,0) [0|3] "" Vector__XXX
 SG_ CTIWheelSensorStatus_20 m32 : 32|2@1+ (1,0) [0|3] "" Vector__XXX
 SG_ CTIWheelSensorStatus_13 m19 : 32|2@1+ (1,0) [0|3] "" Vector__XXX
 SG_ CTIWheelSensorStatus_12 m18 : 32|2@1+ (1,0) [0|3] "" Vector__XXX
 SG_ CTIWheelSensorStatus_11 m17 : 32|2@1+ (1,0) [0|3] "" Vector__XXX
 SG_ CTIWheelSensorStatus_10 m16 : 32|2@1+ (1,0) [0|3] "" Vector__XXX
 SG_ CTIWheelSensorStatus_01 m1 : 32|2@1+ (1,0) [0|3] "" Vector__XXX
 SG_ CTIWheelEndElectricalFault_33 m51 : 36|2@1+ (1,0) [0|3] "" Vector__XXX
 SG_ CTIWheelEndElectricalFault_32 m50 : 36|2@1+ (1,0) [0|3] "" Vector__XXX
 SG_ CTIWheelEndElectricalFault_31 m49 : 36|2@1+ (1,0) [0|3] "" Vector__XXX
 SG_ CTIWheelEndElectricalFault_30 m48 : 36|2@1+ (1,0) [0|3] "" Vector__XXX
 SG_ CTIWheelEndElectricalFault_23 m35 : 36|2@1+ (1,0) [0|3] "" Vector__XXX
 SG_ CTIWheelEndElectricalFault_22 m34 : 36|2@1+ (1,0) [0|3] "" Vector__XXX
 SG_ CTIWheelEndElectricalFault_21 m33 : 36|2@1+ (1,0) [0|3] "" Vector__XXX
 SG_ CTIWheelEndElectricalFault_20 m32 : 36|2@1+ (1,0) [0|3] "" Vector__XXX
 SG_ CTIWheelEndElectricalFault_13 m19 : 36|2@1+ (1,0) [0|3] "" Vector__XXX
 SG_ CTIWheelEndElectricalFault_12 m18 : 36|2@1+ (1,0) [0|3] "" Vector__XXX
 SG_ CTIWheelEndElectricalFault_11 m17 : 36|2@1+ (1,0) [0|3] "" Vector__XXX
 SG_ CTIWheelEndElectricalFault_10 m16 : 36|2@1+ (1,0) [0|3] "" Vector__XXX
 SG_ CTIWheelEndElectricalFault_01 m1 : 36|2@1+ (1,0) [0|3] "" Vector__XXX
 SG_ CTITireStatus_33 m51 : 34|2@1+ (1,0) [0|3] "" Vector__XXX
 SG_ CTITireStatus_32 m50 : 34|2@1+ (1,0) [0|3] "" Vector__XXX
 SG_ CTITireStatus_31 m49 : 34|2@1+ (1,0) [0|3] "" Vector__XXX
 SG_ CTITireStatus_30 m48 : 34|2@1+ (1,0) [0|3] "" Vector__XXX
 SG_ CTITireStatus_23 m35 : 34|2@1+ (1,0) [0|3] "" Vector__XXX
 SG_ CTITireStatus_22 m34 : 34|2@1+ (1,0) [0|3] "" Vector__XXX
 SG_ CTITireStatus_21 m33 : 34|2@1+ (1,0) [0|3] "" Vector__XXX
 SG_ CTITireStatus_20 m32 : 34|2@1+ (1,0) [0|3] "" Vector__XXX
 SG_ CTITireStatus_13 m19 : 34|2@1+ (1,0) [0|3] "" Vector__XXX
 SG_ CTITireStatus_12 m18 : 34|2@1+ (1,0) [0|3] "" Vector__XXX
 SG_ CTITireStatus_11 m17 : 34|2@1+ (1,0) [0|3] "" Vector__XXX
 SG_ CTITireStatus_10 m16 : 34|2@1+ (1,0) [0|3] "" Vector__XXX
 SG_ CTITireStatus_01 m1 : 34|2@1+ (1,0) [0|3] "" Vector__XXX
 SG_ TireTemp_11 m17 : 16|16@1+ (0.03125,-273) [-273|1735] "°C" Vector__XXX
 SG_ TireTemp_33 m51 : 16|16@1+ (0.03125,-273) [-273|1735] "°C" Vector__XXX
 SG_ TireTemp_32 m50 : 16|16@1+ (0.03125,-273) [-273|1735] "°C" Vector__XXX
 SG_ TireTemp_31 m49 : 16|16@1+ (0.03125,-273) [-273|1735] "°C" Vector__XXX
 SG_ TireTemp_30 m48 : 16|16@1+ (0.03125,-273) [-273|1735] "°C" Vector__XXX
 SG_ TireTemp_23 m35 : 16|16@1+ (0.03125,-273) [-273|1735] "°C" Vector__XXX
 SG_ TireTemp_22 m34 : 16|16@1+ (0.03125,-273) [-273|1735] "°C" Vector__XXX
 SG_ TireTemp_21 m33 : 16|16@1+ (0.03125,-273) [-273|1735] "°C" Vector__XXX
 SG_ TireTemp_20 m32 : 16|16@1+ (0.03125,-273) [-273|1735] "°C" Vector__XXX
 SG_ TireTemp_13 m19 : 16|16@1+ (0.03125,-273) [-273|1735] "°C" Vector__XXX
 SG_ TireTemp_12 m18 : 16|16@1+ (0.03125,-273) [-273|1735] "°C" Vector__XXX
 SG_ TireTemp_10 m16 : 16|16@1+ (0.03125,-273) [-273|1735] "°C" Vector__XXX
 SG_ TireTemp_01 m1 : 16|16@1+ (0.03125,-273) [-273|1735] "°C" Vector__XXX
 SG_ TireTemp_00 m0 : 16|16@1+ (0.03125,-273) [-273|1735] "°C" Vector__XXX
 SG_ TirePressThresholdDetection_33 m51 : 61|3@1+ (1,0) [0|7] "" Vector__XXX
 SG_ TirePressThresholdDetection_32 m50 : 61|3@1+ (1,0) [0|7] "" Vector__XXX
 SG_ TirePressThresholdDetection_31 m49 : 61|3@1+ (1,0) [0|7] "" Vector__XXX
 SG_ TirePressThresholdDetection_30 m48 : 61|3@1+ (1,0) [0|7] "" Vector__XXX
 SG_ TirePressThresholdDetection_23 m35 : 61|3@1+ (1,0) [0|7] "" Vector__XXX
 SG_ TirePressThresholdDetection_22 m34 : 61|3@1+ (1,0) [0|7] "" Vector__XXX
 SG_ TirePressThresholdDetection_21 m33 : 61|3@1+ (1,0) [0|7] "" Vector__XXX
 SG_ TirePressThresholdDetection_20 m32 : 61|3@1+ (1,0) [0|7] "" Vector__XXX
 SG_ TirePressThresholdDetection_00 m0 : 61|3@1+ (1,0) [0|7] "" Vector__XXX
 SG_ TirePress_01 m1 : 8|8@1+ (4,0) [0|1000] "kPa" Vector__XXX
 SG_ TirePress_00 m0 : 8|8@1+ (4,0) [0|1000] "kPa" Vector__XXX
 SG_ CTIWheelSensorStatus_00 m0 : 32|2@1+ (1,0) [0|3] "" Vector__XXX
 SG_ CTIWheelEndElectricalFault_00 m0 : 36|2@1+ (1,0) [0|3] "" Vector__XXX
 SG_ CTITireStatus_00 m0 : 34|2@1+ (1,0) [0|3] "" Vector__XXX
 SG_ TireLocation M : 0|8@1+ (1,0) [0|255] "" Vector__XXX

BO_ 2633939966 TFI: 16 Vector__XXX
 SG_ TripFanOnTimeDueToTheA_CSystem : 96|32@1+ (0.05,0) [0|210554060.75] "hr" Vector__XXX
 SG_ TripFanOnTimeDueToAManualSwitch : 64|32@1+ (0.05,0) [0|210554060.75] "hr" Vector__XXX
 SG_ TripFanOnTimeDueToTheEngSystem : 32|32@1+ (0.05,0) [0|210554060.75] "hr" Vector__XXX
 SG_ TripFanOnTime : 0|32@1+ (0.05,0) [0|210554060.75] "hr" Vector__XXX

BO_ 2633939710 TDI: 12 Vector__XXX
 SG_ TripDistanceInTopGear : 64|32@1+ (0.125,0) [0|526385151.9] "km" Vector__XXX
 SG_ TripGearDownDistance : 32|32@1+ (0.125,0) [0|526385151.9] "km" Vector__XXX
 SG_ TripDistanceOnVSL : 0|32@1+ (0.125,0) [0|526385151.9] "km" Vector__XXX

BO_ 2564161278 TDA: 8 Vector__XXX
 SG_ AdjustLocalHourOffset : 56|8@1+ (1,-125) [-125|125] "hr" Vector__XXX
 SG_ AdjustLocalMinuteOffset : 48|8@1+ (1,-125) [-125|125] "mins" Vector__XXX
 SG_ AdjustYear : 40|8@1+ (1,1985) [1985|2235] "years" Vector__XXX
 SG_ AdjustDay : 32|8@1+ (0.25,0) [0|62.5] "days" Vector__XXX
 SG_ AdjustMonth : 24|8@1+ (1,0) [0|250] "months" Vector__XXX
 SG_ AdjustHours : 16|8@1+ (1,0) [0|250] "hr" Vector__XXX
 SG_ AdjustMinutes : 8|8@1+ (1,0) [0|250] "mins" Vector__XXX
 SG_ AdjustSeconds : 0|8@1+ (0.25,0) [0|62.5] "s" Vector__XXX

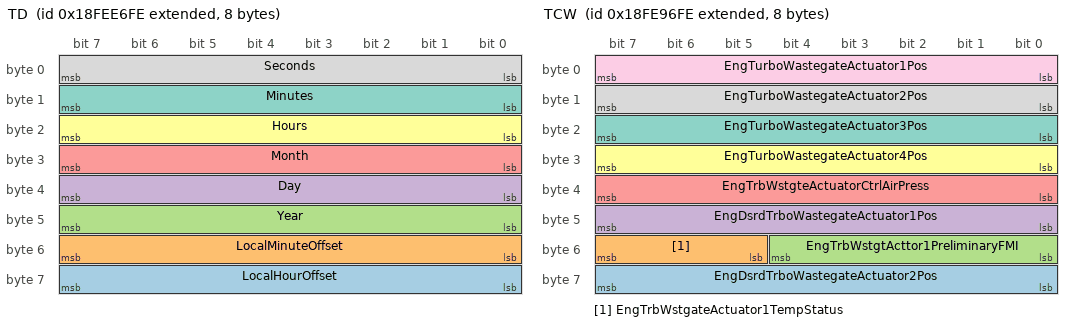
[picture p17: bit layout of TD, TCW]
BO_ 2566842110 TD: 8 Vector__XXX
 SG_ LocalHourOffset : 56|8@1+ (1,-125) [-125|125] "hr" Vector__XXX
 SG_ LocalMinuteOffset : 48|8@1+ (1,-125) [-125|125] "mins" Vector__XXX
 SG_ Year : 40|8@1+ (1,1985) [1985|2235] "years" Vector__XXX
 SG_ Day : 32|8@1+ (0.25,0) [0|62.5] "days" Vector__XXX
 SG_ Month : 24|8@1+ (1,0) [0|250] "months" Vector__XXX
 SG_ Hours : 16|8@1+ (1,0) [0|250] "hr" Vector__XXX
 SG_ Minutes : 8|8@1+ (1,0) [0|250] "mins" Vector__XXX
 SG_ Seconds : 0|8@1+ (0.25,0) [0|62.5] "s" Vector__XXX

BO_ 2566821630 TCW: 8 Vector__XXX
 SG_ EngDsrdTrboWastegateActuator2Pos : 56|8@1+ (0.4,0) [0|100] "%" Vector__XXX
 SG_ EngTrbWstgateActuator1TempStatus : 53|3@1+ (1,0) [0|7] "" Vector__XXX
 SG_ EngTrbWstgtActtor1PreliminaryFMI : 48|5@1+ (1,0) [0|31] "" Vector__XXX
 SG_ EngDsrdTrboWastegateActuator1Pos : 40|8@1+ (0.4,0) [0|100] "%" Vector__XXX
 SG_ EngTrbWstgteActuatorCtrlAirPress : 32|8@1+ (4,0) [0|1000] "kPa" Vector__XXX
 SG_ EngTurboWastegateActuator4Pos : 24|8@1+ (0.4,0) [0|100] "%" Vector__XXX
 SG_ EngTurboWastegateActuator3Pos : 16|8@1+ (0.4,0) [0|100] "%" Vector__XXX
 SG_ EngTurboWastegateActuator2Pos : 8|8@1+ (0.4,0) [0|100] "%" Vector__XXX
 SG_ EngTurboWastegateActuator1Pos : 0|8@1+ (0.4,0) [0|100] "%" Vector__XXX

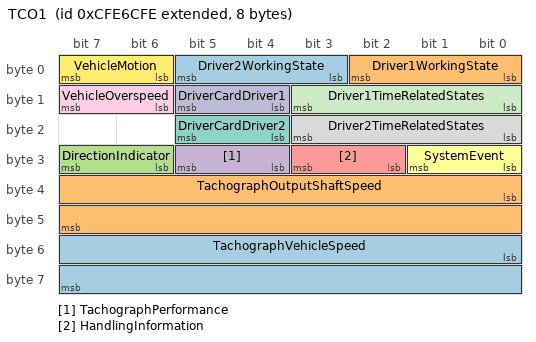
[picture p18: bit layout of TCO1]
BO_ 2365484286 TCO1: 8 Vector__XXX
 SG_ TachographVehicleSpeed : 48|16@1+ (0.00390625,0) [0|250.996] "km/h" Vector__XXX
 SG_ TachographOutputShaftSpeed : 32|16@1+ (0.125,0) [0|8031.875] "rpm" Vector__XXX
 SG_ DirectionIndicator : 30|2@1+ (1,0) [0|3] "" Vector__XXX
 SG_ TachographPerformance : 28|2@1+ (1,0) [0|3] "" Vector__XXX
 SG_ HandlingInformation : 26|2@1+ (1,0) [0|3] "" Vector__XXX
 SG_ SystemEvent : 24|2@1+ (1,0) [0|3] "" Vector__XXX
 SG_ DriverCardDriver2 : 20|2@1+ (1,0) [0|3] "" Vector__XXX
 SG_ Driver2TimeRelatedStates : 16|4@1+ (1,0) [0|15] "" Vector__XXX
 SG_ VehicleOverspeed : 14|2@1+ (1,0) [0|3] "" Vector__XXX
 SG_ DriverCardDriver1 : 12|2@1+ (1,0) [0|3] "" Vector__XXX
 SG_ Driver1TimeRelatedStates : 8|4@1+ (1,0) [0|15] "" Vector__XXX
 SG_ VehicleMotion : 6|2@1+ (1,0) [0|3] "" Vector__XXX
 SG_ Driver2WorkingState : 3|3@1+ (1,0) [0|7] "" Vector__XXX
 SG_ Driver1WorkingState : 0|3@1+ (1,0) [0|7] "" Vector__XXX

CM_ BO_ 2566834686 "ISO 11992: Towing vehicle message, electronic brake system #1/2";
CM_ SG_ 2566834686 RoadCurvature "Estimated value of the current road curvature for use by the adaptive cruise control system.  Positive values are used for ...";
CM_ SG_ 2566834686 PneumaticControlLine "Signal which indicates that the towing vehicle has a pneumatic control line for the towed vehicle service braking system";
CM_ SG_ 2566834686 ABSOffroadRequest "Request to activate the ABS off-road function. The switch signal is independent of an actual ABS control situation.";
CM_ SG_ 2566834686 TwoElCircuitsBrakeDemand "Signal which indicates that the service brake demand value sent by the towing vehicle can be generated by one or two independent electrical braking circuit(s).";
CM_ SG_ 2566834686 VehicleRetarderCtrlActive "This signal indicates the active/passive state in all cases when the installed retarder is applied by the driver’s demand or by other systems (brakes).";
CM_ BO_ 2550398718 "ISO 11992: Towed vehicle message, electronic brake system #2/1";
CM_ SG_ 2550398718 WheelSpeedDiffMainAxle "Difference between the wheel speed at the right side and and the left side of the main axle.";
CM_ SG_ 2550398718 ActualRetarderPercTorque "Actual torque of the retarder as negative percentage of maximum.";
CM_ SG_ 2550398718 Wheel_BasedVehicleSpeed "Actual speed of the vehicle (positive value for forward and backward speed) calculated as the average of the wheel speeds of one axle influenced by slip and filtered by a frequency range of 5 Hz to 20 Hz.";
CM_ SG_ 2550398718 SupplyLineBrakingRequest "Signal indicating the trailer is requesting to be braked by the commercial vehicle by means of bleeding the pneumatic supply line.";
CM_ SG_ 2550398718 VDCActive "Signal which indicates that Vehicle Dynamic Control (VDC) is active/passive.";
CM_ SG_ 2550398718 AutomTowedVehBreakActive "Signal indicating the automatic towed vehicle braking is active/passive.";
CM_ SG_ 2550398718 VehicleServiceBrakeActive "Signal indicating the service brake of the towed vehicle is active/passive, by observing the brake pressure.";
CM_ SG_ 2550398718 VehicleRetarderCtrlActive "This signal indicates the active/passive state in all cases when the installed retarder is applied by the driver’s demand or by other systems (brakes).";
CM_ SG_ 2550398718 VehicleABSActive "Signal indicating the ABS is active/passive.";
CM_ BO_ 2566833406 "ISO 11992: Towed vehicle message, electronic brake system #2/2";
CM_ SG_ 2566833406 ReferenceRetarderTorque "This parameter is the 100% reference value for all defined indicated retarder torque parameters.  It is only defined once ...";
CM_ SG_ 2566833406 AxleLoadSum "Sum of the static vertical loads of the vehicle axles.";
CM_ SG_ 2566833406 SupplyLineBrakingRequest "Signal indicating the trailer is requesting to be braked by the commercial vehicle by means of bleeding the pneumatic supply line.";
CM_ SG_ 2566833406 LoadingRampApproachAssist "The parameter indicates whether the loading ramp approach assistance is activated.";
CM_ SG_ 2566833406 SpringBrakeEngaged "Signal indicating the vehicle spring brake is engaged.";
CM_ SG_ 2566833406 ElectrLoadPropFunc "Signal indicating the vehicle is equipped with an electrical load proportional function.";
CM_ SG_ 2566833406 SpringBrakeInstalled "Signal indicating the vehicle has one or more axle(s) fitted with spring brakes.";
CM_ SG_ 2566833406 VehicleType "Information to identify a dolly axle within the road train.";
CM_ SG_ 2566833406 ElecSupplyOfNonBrakingSys "Signal which indicates the status of the supply of non-braking systems.";
CM_ SG_ 2566833406 AmberWarningSignalReq "Request from the towed vehicle to the commercial vehicle to activate the amber warning signal on the commercial vehicle.";
CM_ SG_ 2566833406 RedWarningSignalRequest "Request from the towed vehicle to the commercial vehicle to activate the red warning signal on the commercial vehicle, which indicates certain specified failures within the braking equipment of the towed vehicles.";
CM_ SG_ 2566833406 VehicleElectrSupplySuff "Signal indicating the actual supply voltage is sufficient/insufficient for proper brake function (including over voltage).";
CM_ SG_ 2566833406 AutomTowedVehBreakActive "Signal indicating the automatic towed vehicle braking is active/passive.";
CM_ SG_ 2566833406 VehicleServiceBrakeActive "Signal indicating the service brake of the towed vehicle is active/passive, by observing the brake pressure.";
CM_ SG_ 2566833406 VehicleRetarderCtrlActive "This signal indicates the active/passive state in all cases when the installed retarder is applied by the driver’s demand or by other systems (brakes).";
CM_ SG_ 2566833406 VehicleABSActive "Signal indicating the ABS is active/passive.";
CM_ BO_ 2365507326 "ISO 11992: Towed vehicle message, electronic brake system #2/3";
CM_ SG_ 2365507326 PneumaticSupplyPressure "Actual supply pressure of the reservoir of the braking system.";
CM_ SG_ 2365507326 BrakeTemperature "Actual brake temperature.";
CM_ SG_ 2365507326 BrakeLining "Actual relative value of brake lining of a specific brake.";
CM_ SG_ 2365507326 TyrePressure "Actual tyre pressure without corrections.";
CM_ SG_ 2365507326 TyreWheelIdentTemp2 "Second part of identification number of the tyre or wheel (the number of axles).";
CM_ SG_ 2365507326 TyreWheelIdentTemp1 "First part of identification number of the tyre or wheel (position on each axle).";
CM_ SG_ 2365507326 TyreWheelIdentPressure2 "Second part of identification number of the tyre or wheel (the number of axles).";
CM_ SG_ 2365507326 TyreWheelIdentPressure1 "First part of identification number of the tyre or wheel (position on each axle).";
CM_ SG_ 2365507326 TyreWheelIdentLining2 "Second part of identification number of the tyre or wheel (the number of axles).";
CM_ SG_ 2365507326 TyreWheelIdentLining1 "First part of identification number of the tyre or wheel (position on each axle).";
CM_ SG_ 2365507326 VehiclePneumSupplySuff "Signal indicating the actual supply pressure of the reservoir of the braking system is insufficient or sufficient.";
CM_ SG_ 2365507326 BrakeTemperatureStatus "Signal which indicates that the brake temperature is higher than a specific level.";
CM_ SG_ 2365507326 BrakeLiningSufficient "Signal which indicates that the brake lining is sufficient/insufficient.";
CM_ SG_ 2365507326 TyrePressureSufficient "Signal which indicates that the tyre pressure is insufficient";
CM_ BO_ 2565013246 "ISO 11992: Towing vehicle message, general purpose message #1/1

GPM 11 replaces GFM 11 in ISO 11992:1998 part 3";
CM_ SG_ 2565013246 ODDRequest "Command signal to switch on or off the obstacle detection device (ODD).";
CM_ SG_ 2565013246 AntiTheftDeviceReq "Command signal to activate the anti-theft device.";
CM_ SG_ 2565013246 VehicleType "Information to identify a dolly axle within the road train.";
CM_ BO_ 2566807038 "ISO 11992: Towing vehicle message, general purpose message #1/2";
CM_ SG_ 2566807038 MaxVehicleSpeedLimit "Maximum vehicle velocity allowed.";
CM_ SG_ 2566807038 EngineSpeedUpperLimit "The engine speed which cannot be exceeded.";
CM_ SG_ 2566807038 EngineSpeedLowerLimit "The minimum engine speed which the engine is allowed to reach.";
CM_ BO_ 2365480958 "ISO 11992: Towing vehicle message, general purpose message #1/3";
CM_ SG_ 2365480958 EngineTorqueMode "State signal which indicates which engine torque mode is currently generating, limiting, or controlling the torque";
CM_ SG_ 2365480958 PercentLoadAtCurrentSpeed "The ratio of actual engine percent torque to maximum indicated torque available at the current engine speed, clipped to zero torque during engine braking.";
CM_ SG_ 2365480958 EngineSpeed "Actual engine speed which is calculated over a minimum crankshaft angle of 720 degrees divided by
the number of cylinders.";
CM_ SG_ 2365480958 ActualEngine_PercTorque "The calculated output torque of the engine.";
CM_ SG_ 2365480958 DriversDemandEngine_PercTorque "The torque output of the engine requested by the driver.";
CM_ SG_ 2365480958 EngineRunning "Signal which indicates whether the engine is running.";
CM_ SG_ 2365480958 EngineControlAllowed "Switch signal which indicates that engine control is allowed.";
CM_ BO_ 2566808062 "ISO 11992: Towing vehicle message, general purpose message #1/4";
CM_ SG_ 2566808062 ClutchIndptdPTOFeedback "Signal which indicates the current state of the clutch independent power take off.";
CM_ SG_ 2566808062 AccelPedalPosition "The ratio of actual accelerator pedal position to maximum pedal position.";
CM_ SG_ 2566808062 AccelPedalLowIdleSwitch "Switch signal which indicates whether the accelerator pedal low idle switch is opened or closed.";
CM_ SG_ 2566808062 StarterActive "Signal which indicates whether the starter is in use.";
CM_ SG_ 2566808062 TorqueConvOilTemp "Temperature of the torque converter lubricant.";
CM_ SG_ 2566808062 TorqueConvtOilTempWarning "Signal which indicates that the torque converter oil temperature has reached its warning level.";
CM_ SG_ 2566808062 PTOControlAllowed "Switch signal which indicates that PTO control is allowed.";
CM_ SG_ 2566808062 SecEngineMtdPTOFeedback "Signal which indicates the current state of the second engine mounted power take off.";
CM_ SG_ 2566808062 FirstEngineMtdPTOFeedback "Signal which indicates the current state of the first engine mounted power take off.";
CM_ SG_ 2566808062 SecClutchDptdPTOFeedback "Signal which indicates the current state of the second clutch dependent power take off.";
CM_ SG_ 2566808062 FirstClutchDpdtPTOFeedback "Signal which indicates the current state of the first clutch dependent power take off.";
CM_ SG_ 2566808062 CurrentGear "The gear currently engaged in the transmission or the last gear engaged while the transmission is in process of shifting to the new or selected gear.";
CM_ SG_ 2566808062 PercentClutchSlip "Parameter which represents the ratio of input shaft speed to current engine speed (in percent).";
CM_ BO_ 2566808574 "ISO 11992: Towing vehicle message, general purpose message #1/5";
CM_ SG_ 2566808574 ReferenceEngineTorque "The 100 % reference value for all defined indicated engine torque parameters.";
CM_ SG_ 2566808574 FuelLevelWarning "This signal indicates the decrease of the fuel level to a certain minimum.";
CM_ SG_ 2566808574 EngineOilPressureWarning "Signal which indicates that the engine oil pressure has reached its warning level.";
CM_ SG_ 2566808574 EngineCoolantTempWarning "Signal which indicates that the engine coolant temperature has reached its warning level.";
CM_ SG_ 2566808574 EngineOilPressure "Gauge pressure of the oil in the engine lubrication system as provided by the oil pump.";
CM_ SG_ 2566808574 EngCoolantTemp "Temperature of liquid found in engine cooling system.";
CM_ SG_ 2566808574 EngineOilTemperature "Temperature of the engine lubricant.";
CM_ BO_ 2566809086 "ISO 11992: Towing vehicle message, general purpose message #1/6";
CM_ SG_ 2566809086 AmbientAirTemperature "Temperature of air surrounding vehicle.";
CM_ BO_ 2564947710 "ISO 11992: Towed vehicle message, general purpose message #2/1

GPM 21 replaces GFM 21 in ISO 11992:1998 part 3";
CM_ SG_ 2564947710 VehicleType "Information to identify a dolly axle within the road train.";
CM_ BO_ 2566834430 "ISO 11992: Towed vehicle message, general purpose message #2/2

GPM22 replaces GFM 24 in ISO 11992:1998 part 3";
CM_ SG_ 2566834430 BodyPressure "The actual pressure in a body on the towed vehicle.";
CM_ SG_ 2566834430 BodyFluidLevel "The actual fluid level in a body on the towed vehicle.";
CM_ SG_ 2566834430 ThermalBodyTemperature "The actual temperature in a thermal body on the towed vehicle.";
CM_ SG_ 2566834430 RearObstacleDistance "The actual distance between the back of the towed vehicle and any obstacle.";
CM_ SG_ 2566834430 AntiTheftDeviceStatus "Signal which indicates that the anti-theft device is switched on or off.";
CM_ SG_ 2566834430 ODDStatus "Signal which indicates that an obstacle detection device (ODD) is active/inactive.";
CM_ BO_ 2365481214 "ISO 11992: Towed vehicle message, general purpose message #2/3";
CM_ SG_ 2365481214 ReqEngineSpeedUpperLim "The requested engine speed which is not to be exceeded.";
CM_ SG_ 2365481214 ReqEngineSpeedLowerLim "The requested minimum engine speed which the engine is to allow.";
CM_ SG_ 2365481214 ReqEngineTorqueLimit "The requested engine torque that the engine is not allowed to exceed, indicated as a ratio of the reference engine torque.";
CM_ SG_ 2365481214 ReqEngineSpeedLimit "The requested vehicle speed which the vehicle is not allowed to exceed.";
CM_ SG_ 2365481214 ReqEngineSpeed "This is the engine speed which the engine is expected to operate at.";
CM_ BO_ 2566808318 "ISO 11992: Towed vehicle message, general purpose message #2/4";
CM_ SG_ 2566808318 SecEngineMtdPTOSwitch "Signal which indicates the state of the second engine mounted power take off switch.";
CM_ SG_ 2566808318 SecClutchDpdtPTOSwitch "Signal which indicates the state of the second clutch dependent power take off switch.";
CM_ SG_ 2566808318 FirstClutchDpdtPTOSwitch "Signal which indicates the state of the first clutch dependent power take off switch.";
CM_ SG_ 2566808318 OperatingPanelActive "Signal which indicates that the operating panel is active.";
CM_ SG_ 2566808318 RefusePackerStepSwitch "Signal which indicates the state of the refuse packer step switch.";
CM_ SG_ 2566808318 EngineStopSwitch "Signal which indicates the state of the engine stop switch.";
CM_ SG_ 2566808318 EngineStartSwitch "Signal which indicates the state of the engine start switch.";
CM_ SG_ 2566808318 StarterLockoutSwitch "Signal which indicates the state of the starter lockout switch.";
CM_ SG_ 2566808318 RqstedPercentClutchSlip "Command signal to influence the clutch.";
CM_ SG_ 2566808318 FirstEngineMtdPTOSwitch "Signal which indicates the state of the first engine mounted power take off switch.";
CM_ SG_ 2566808318 ClutchIndpdtPTOSwitch "Signal which indicates the state of the clutch independent power take off switch.";
CM_ BO_ 2566808830 "ISO 11992: Towed vehicle message, general purpose message #2/5";
CM_ SG_ 2566808830 TrailerLeftSideMarkerLight "This signal indicates the state of the trailer left-hand side marker light(s).";
CM_ SG_ 2566808830 TrailerLeftReversingLight "This signal indicates the state of the trailer left-hand reversing light(s).";
CM_ SG_ 2566808830 TrailerLeftRearWidIndLight "This signal indicates the state of the trailer left-hand rear width indicator light(s).";
CM_ SG_ 2566808830 TrailerLeftRearRegPltLight "This signal indicates the state of the trailer left-hand rear registration-plate light(s).";
CM_ SG_ 2566808830 TrailerLeftRearLight "This signal indicates the state of the trailer left-hand rear light(s).";
CM_ SG_ 2566808830 TrailerLeftRearFogLight "This signal indicates the state of the trailer left-hand rear fog light(s).";
CM_ SG_ 2566808830 TrailerLeftDirIndLight "This signal indicates the state of the trailer left-hand direction indicator light(s).";
CM_ SG_ 2566808830 TrailerLeftCrnMarkerLight "This signal indicates the state of the trailer left-hand corner marker light(s).";
CM_ SG_ 2566808830 TrailerInteriorLight "This signal indicates the state of the trailer interior light(s).";
CM_ SG_ 2566808830 TrailerWorkLamp "This signal indicates the state of the trailer work lamp(s).";
CM_ SG_ 2566808830 TrailerRotatingIdentLight "This signal indicates the state of the trailer rotating identification light(s).";
CM_ SG_ 2566808830 TrailerRightStopLight "This signal indicates the state of the trailer right-hand stop light(s).";
CM_ SG_ 2566808830 TrailerRightSideMrkLight "This signal indicates the state of the trailer right-hand side marker light(s).";
CM_ SG_ 2566808830 TrailerRightReversingLight "This signal indicates the state of the trailer right-hand reversing light(s).";
CM_ SG_ 2566808830 TrailRightRearWidIndLight "This signal indicates the state of the trailer right-hand rear width indicator light(s).";
CM_ SG_ 2566808830 TrailerRightRearRegPltLight "This signal indicates the state of the trailer right-hand rear registration-plate light(s).";
CM_ SG_ 2566808830 TrailerRightRearLight "This signal indicates the state of the trailer right-hand rear light(s).";
CM_ SG_ 2566808830 TrailerRightRearFogLight "This signal indicates the state of the trailer right-hand rear fog light(s).";
CM_ SG_ 2566808830 TrailerRightDirIndLight "This signal indicates the state of the trailer right-hand direction indicator light(s).";
CM_ SG_ 2566808830 TrailerRightCrnMarkerLight "This signal indicates the state of the trailer right-hand corner marker light(s).";
CM_ SG_ 2566808830 TrailerRearWarningLight "This signal indicates the state of the trailer rear warning light(s).";
CM_ SG_ 2566808830 TrailerLeftStopLight "This signal indicates the state of the trailer left-hand stop light(s).";
CM_ BO_ 2564554494 "Reserved for ISO 15765";
CM_ SG_ 2564554494 ProtocolCtrlInformation "Part of Network Protocol Control Information (N_PCI) of a ISO 15765 message.";
CM_ BO_ 2564488958 "Reserved for ISO 15765";
CM_ SG_ 2564488958 ProtocolCtrlInformation "Part of Network Protocol Control Information (N_PCI) of a ISO 15765 message.";
CM_ BO_ 2565734142 "Used to access network interconnection ECU parametrics and database";
CM_ SG_ 2565734142 FilterMode "Filter mode for Network PG";
CM_ SG_ 2565734142 ToPort "Destination port for network PG";
CM_ SG_ 2565734142 FromPort "Source port for Network PG";
CM_ BO_ 2565144318 "ISO 11992: Towing vehicle message, running gear equipment #1/1

RGE11 replaces GFM 12 in ISO 11992:1998 part 3";
CM_ SG_ 2565144318 ParkingAndTrailerAirPress "The pneumatic pressure in the circuit or reservoir for the parking brake and the trailer supply.";
CM_ SG_ 2565144318 DrivenAxleLoad "Actual static vertical load on driven axle of the commercial vehicle. In case of more than one driven axle the value of the axle with the highest vertical load is transmitted.";
CM_ SG_ 2565144318 AuxEquipSupplyPressure "The pneumatic pressure in the auxiliary circuit.";
CM_ SG_ 2565144318 StopLevelChangeReq "Command signal to stop immediately any change of the actual body height level.";
CM_ SG_ 2565144318 RampLevelStorageReq "Command signal to store the actual body height level as new programmed and memorised ramp levels 1 or 2 in the ECU";
CM_ SG_ 2565144318 LevelControlReq "Command signal to enable or disable the automatic level control.";
CM_ SG_ 2565144318 RampLevelReq "Command signal to control the body height to a level programmed and memorised in the ECU.";
CM_ SG_ 2565144318 SteeringAxleLockingReq "Command signal to lock the steering axle.";
CM_ SG_ 2565144318 LiftAxle2PositionReq "Command signal to control the lift axle position / tag axle load condition.";
CM_ SG_ 2565144318 LiftAxle1PositionReq "Command signal to control the lift axle position / tag axle load condition.";
CM_ SG_ 2565144318 TractionHelpReq "Command signal to control the lift axle position / tag axle load condition to transfer more load on the driven axle of the commercial vehicle.";
CM_ SG_ 2565144318 LevelChangeReqRearAxle "Command signal to control the body height [up (lifting)/down (lowering)] for the rear axle.";
CM_ SG_ 2565144318 LevelChangeReqFrontAxle "Command signal to control the body height [up (lifting)/down (lowering)] for the front axle.";
CM_ SG_ 2565144318 RideHeightRequest "Command signal to activate a normal ride body height. The normal levels 1 and 2 are trailer specific body heights.";
CM_ BO_ 2565209854 "ISO 11992: Towed vehicle message, running gear equipment #2/1

RGE21 replaces GFM 22 in ISO 11992:1998 part 3";
CM_ SG_ 2565209854 LevelControl "Signal which indicates that the automatic level control is enabled or disabled.";
CM_ SG_ 2565209854 NominalVehBodyLevelRearAxle "Actual nominal vehicle body height.";
CM_ SG_ 2565209854 NominalVehBodyLevelFrontAxle "Actual nominal vehicle body height.";
CM_ SG_ 2565209854 RampLevel "Signal which indicates the level of the body height as an anser to 'ramp level request'.";
CM_ SG_ 2565209854 NormalLevel "Signal which indicates the normal levels of the vehicle independently of a specific request.";
CM_ SG_ 2565209854 StopLevelChangeAcknowledge "Signal which indicates the stop of any level change due to a 'stop request'.";
CM_ SG_ 2565209854 LevelChangeRearAxle "Signal which indicates the level change of the body height at the rear axle due to any external requests.";
CM_ SG_ 2565209854 LevelChangeFrontAxle "Signal which indicates the level change of the body height at the front axle due to any external requests.";
CM_ SG_ 2565209854 RampLevelStorage "Signal which indicates the storage of a new ramp level in the ECU.";
CM_ SG_ 2565209854 SteeringAxleLocking "Signal which indicates the actual steering axle locking status.";
CM_ SG_ 2565209854 LiftAxle2Pos "Signal which indicates the position / load condition of lift axle / tag axle #2.   Numbering of lift/tag axles starts at front axle.";
CM_ SG_ 2565209854 LiftAxle1Pos "Signal which indicates the position / load condition of lift axle / tag axle #1.   Numbering of lift/tag axles starts at front axle.";
CM_ SG_ 2565209854 RampLevelPosition "Signal which indicates the ramp level positions of the vehicle independently of a specific request.";
CM_ SG_ 2565209854 TractionHelp "Signal which indicates that a load transfer is active.";
CM_ SG_ 2565209854 LevelCtrlSysRideHeightLevel "Signal which indicates the body height position of the vehicle as an answer to 'ride height request'.";
CM_ BO_ 2566806782 "ISO 11992: Towed vehicle message, running gear equipment #2/2";
CM_ SG_ 2566806782 RelVehBodyLevelRearAxle "Actual relative vehicle body height.";
CM_ SG_ 2566806782 RelVehBodyLevelFrontAxle "Actual relative vehicle body height.";
CM_ BO_ 2566807294 "ISO 11992: Towed vehicle message, running gear equipment #2/3";
CM_ SG_ 2566807294 TyrePressThresholdDetect "Signal indicating the pressure level of the tyre.";
CM_ SG_ 2566807294 TyreModulePowerSupply "Signal indicating the power supply of the tyre module is sufficient to achieve the specified performance of the module.";
CM_ SG_ 2566807294 TyreTemperature "The temperature measured by the tyre module.";
CM_ SG_ 2566807294 AirLeakageDetection "The pressure loss of a tyre.";
CM_ SG_ 2566807294 TyreWheelIdentification2 "First part of the identification number of the tyre or whee (number of axles).";
CM_ SG_ 2566807294 TyreWheelIdentification1 "First part of the identification number of the tyre or whee (position on each axle).";
CM_ BO_ 2566764798 "Diagnostic readiness 3";
CM_ BO_ 2564095742 "Data security";
CM_ BO_ 2349137662 "Used for brake control by an external device. The receiver is the brake system controlling the axle and/or wheel brakes.";
CM_ SG_ 2349137662 XBRMessageChecksum "The XBR message checksum is used to verify the signal path from the demanding device to the brake controller on ...";
CM_ SG_ 2349137662 XBRMessageCounter "The XBR message counter is to verify the signal path from the demanding device to the brake controller on electronic ...";
CM_ SG_ 2349137662 XBRUrgency "The idea of the urgency value is to adjust the endurance brake integration behavior in the EBS system according to the ...";
CM_ SG_ 2349137662 XBRCtrlMode "The XBR Control Mode is used as an input to the brake system and defines how the external acceleration demand has to ...";
CM_ SG_ 2349137662 XBRPriority "The XBR Priority is used as an input to the brake system to manage the priority of overlapping external and internal ...";
CM_ SG_ 2349137662 XBREBIMode "The XBR EBI (Endurance Brake Integration) Mode is used as an input for the brake system to prescribe the use of ...";
CM_ SG_ 2349137662 ExtlAccelerationDemand "Parameter provided to the brake system from external sources. This is the acceleration which the brake system is ...";
CM_ BO_ 2566848510 "Water in Fuel Indicator";
CM_ SG_ 2566848510 EmssnCtrlSystmOprtrIndcmntSvrity "Severity status of the operator inducement system for anomalies with the emission control system, such as tampering, ...";
CM_ SG_ 2566848510 DrvrWarningSystemIndicatorStatus "The desired illumination of the Euro VI defined driver warning system indicator for relevant malfunctions and diesel ...";
CM_ SG_ 2566848510 OperatorShiftPrompt "Command to activate an indicator that advises the operator to shift to a different gear.  Typically this would be used as ...";
CM_ SG_ 2566848510 WaterInFuelIndicator "Signal which indicates the presence of water in the fuel.";
CM_ BO_ 2566843134 "Vehicle Weight";
CM_ SG_ 2566843134 AxleLocation "To identify to which of several similar devices (such as tires or fuel tanks) the information applies.";
CM_ SG_ 2566843134 CargoWeight_30 "The mass of freight carried.";
CM_ SG_ 2566843134 CargoWeight_20 "The mass of freight carried.";
CM_ SG_ 2566843134 CargoWeight_10 "The mass of freight carried.";
CM_ SG_ 2566843134 CargoWeight_00 "The mass of freight carried.";
CM_ SG_ 2566843134 TrailerWeight_30 "Total mass of freight-carrying vehicle designed to be pulled by truck, including the weight of the contents.";
CM_ SG_ 2566843134 TrailerWeight_20 "Total mass of freight-carrying vehicle designed to be pulled by truck, including the weight of the contents.";
CM_ SG_ 2566843134 TrailerWeight_10 "Total mass of freight-carrying vehicle designed to be pulled by truck, including the weight of the contents.";
CM_ SG_ 2566843134 TrailerWeight_00 "Total mass of freight-carrying vehicle designed to be pulled by truck, including the weight of the contents.";
CM_ SG_ 2566843134 AxleWeight_30 "Total mass imposed by the tires on the road surface at the specified axle.";
CM_ SG_ 2566843134 AxleWeight_20 "Total mass imposed by the tires on the road surface at the specified axle.";
CM_ SG_ 2566843134 AxleWeight_10 "Total mass imposed by the tires on the road surface at the specified axle.";
CM_ SG_ 2566843134 AxleWeight_00 "Total mass imposed by the tires on the road surface at the specified axle.";
CM_ BO_ 2566804222 "This contains high resolution/range parameters reported from the alternator or power generation components.";
CM_ SG_ 2566804222 NetBatteryCurrent "Net flow of electrical current into/out-of the battery or batteries.  This parameter is the high range and resolution of SPN ...";
CM_ SG_ 2566804222 AltCurrent "This parameter indicates the amount of electrical current output from the alternator of the main vehicle.  Alternator Current ...";
CM_ BO_ 2566819326 "Voltage data for the main vehicle Power Distribution system.";
CM_ SG_ 2566819326 ECUPowerOutputSupplyVoltage3 "The third power output from an ECM.";
CM_ SG_ 2566819326 ECUPowerOutputSupplyVoltage2 "The second power output from an ECM.";
CM_ SG_ 2566819326 ECUPowerOutputSupplyVoltage1 "The first power output from an ECM ...";
CM_ SG_ 2566819326 BatteryPotential_PowerInput2 "This parameter measures the second source of battery potential as measured at the input of the ECM/actuator etc.";
CM_ SG_ 2566845438 Longitude "Longitude position of the vehicle.";
CM_ SG_ 2566845438 Latitude "Latitude position of the vehicle.";
CM_ BO_ 2566843646 "Byte: 1-n Vehicle Identification Number 
Delimiter (ASCII “*”)";
CM_ SG_ 2566843646 VehicleIdentificationNumber "Vehicle Identification Number (VIN) as assigned by the vehicle manufacturer.";
CM_ SG_ 2566842366 TotalPowerTakeoffHours "Accumulated time of operation of power takeoff device.";
CM_ SG_ 2566842366 TotalVehicleHours "Accumulated time of operation of vehicle.";
CM_ SG_ 2566809854 HydOilLevel "This parameter indicates the level of the hydraulic fluid in tank as a ratio of current volume to total tank volume.  This ...";
CM_ SG_ 2566809854 WinchOilPressSwitch "State of switch used to determine if Winch Oil Pressure is above desired minimum ...";
CM_ SG_ 2566809854 HydOilFilterRestrictionSwitch "This switch indicates whether hydraulic oil filter is clogged. This is not the transmission oil filter restriction switch, which is ...";
CM_ SG_ 2566809854 HydTemp "Temperature of hydraulic fluid.";
CM_ SG_ 2566842622 Altitude "Altitude of the vehicle referenced to sea level at standard atmospheric pressure and temperature.";
CM_ SG_ 2566842622 Pitch "Pitch (rotation about the y-axis) of the vehicle as calculated by the navigation device(s).  The pitch angle for an angle of ...";
CM_ SG_ 2566842622 NavigationBasedVehicleSpeed "Speed of the vehicle as calculated from a device such as a Global Positioning System (GPS).";
CM_ SG_ 2566842622 CompassBearing "Present compass bearing of vehicle.";
CM_ SG_ 2566832638 HighResolutionTripDistance "Distance traveled during all or part of a journey.";
CM_ SG_ 2566832638 HghRsolutionTotalVehicleDistance "Accumulated distance traveled by the vehicle during its operation.";
CM_ BO_ 2565868030 "Contains information which relates to the vehicle's movement.";
CM_ SG_ 2565868030 LongitudinalAcceleration "Indicates the longitudinal acceleration of the vehicle. A positive longitudinal acceleration signal results when the vehicle ...";
CM_ SG_ 2565868030 LateralAcceleration "Indicates a lateral acceleration of the vehicle (the component of vehicle acceleration vector along the Y-axis). A positive ...";
CM_ SG_ 2565868030 YawRate "Indicates the rate of rotation about the vertical axis (i.e. the z-axis).  A positive yaw rate signal results when the vehicle ...";
CM_ SG_ 2565868030 SteerWheelAngleSensorType "Indicates whether the steering wheel angle sensor is capable of absolute measuring of the number of steering wheel ...";
CM_ SG_ 2565868030 SteerWheelTurnCounter "Indicates number of steering wheel turns, absolute position or relative position at ignition on. Positive values indicate left ...";
CM_ SG_ 2565868030 SteerWheelAngle "The main operator`s steering wheel angle (on the steering column, not the actual wheel angle).  The vehicle being ...";
CM_ BO_ 2566803454 "Contains information which relates to the VDC system status.";
CM_ SG_ 2566803454 TrailerVDCActive "The trailer-VDC (Vehicle Dynamic Control) is an electronic vehicle stability function within the (semi) trailer braking ...";
CM_ SG_ 2566803454 YCBrakeCtrlActive "State signal which indicates that Yaw Control (YC) has activated brake control. Active means that YC actually controls ...";
CM_ SG_ 2566803454 YCEngCtrlActive "State Signal which indicates that the Yaw Control (YC) has commanded engine control to be active. Within the physical ...";
CM_ SG_ 2566803454 ROPBrakeCtrlActive "State signal which indicates that Roll over Prevention (ROP) has activated brake control. Active means that ROP actually ...";
CM_ SG_ 2566803454 ROPEngCtrlActive "State Signal which indicates that the Roll Over Prevention (ROP) has commanded engine control to be active. Within the ...";
CM_ SG_ 2566803454 VDCBrakeLightRq "Indicates whether VDC requests to turn the vehicle brake lights on ...";
CM_ SG_ 2566803454 VDCFullyOperational "Signal that indicates whether VDC is fully operational or whether its functionality is reduced by a permanent or temporary ...";
CM_ SG_ 2566803454 VDCInformationSignal "This parameter commands the VDC information signal, for example a dash lamp.";
CM_ SG_ 2566840574 TotalVehicleDistance "Accumulated distance traveled by vehicle during its operation.";
CM_ SG_ 2566840574 TripDistance "Distance traveled during all or part of a journey.";
CM_ SG_ 2633938686 TripCruiseDistance "Total distance that the engine has operated in the cruise hold state, excluding time in accelerator override, since the last ...";
CM_ SG_ 2633938686 TripMaxVehicleSpeed "Maximum vehicle speed achieved while the engine speed is greater than zero and the accelerator pedal position (APS) is ...";
CM_ SG_ 2633937150 TripAirCompressorOnTime "Total time that the air compressor is on and compressing air since the last trip reset.";
CM_ SG_ 2633937150 TripIdleTime "Total time accumulated while the engine speed is greater than zero, both the PTO and remote PTO governors are ...";
CM_ SG_ 2633937150 TripEngRunningTime "Total time accumulated while the engine speed is greater than zero since the last trip reset.  Note that time with the ...";
CM_ SG_ 2633937150 TripCruiseTime "Total time accumulated while the engine is in the cruise hold state, excluding time in accelerator override, since the last ...";
CM_ SG_ 2633937150 TripPTOGovernorTime "Total time accumulated while the engine is in the PTO or remote PTO governor hold state since the last trip reset.";
CM_ SG_ 2633938174 TripTimeInDerateByEng "Total time accumulated when the engine final fueling has been derated due to an engine protection algorithm, since the ...";
CM_ SG_ 2633938174 TripTimeInGearDown "Total time accumulated when the vehicle has operated in one gear down from the top gear for a calibrated minimum time, ...";
CM_ SG_ 2633938174 TripTimeInTopGear "Total time accumulated when the vehicle has operated in top gear for a calibrated minimum time, since the last trip reset.";
CM_ SG_ 2633938174 TripTimeInVSL "Total time accumulated when the engine has operated on the vehicle speed limiter (VSL) while not in the cruise hold ...";
CM_ SG_ 2633938430 TripSuddenDecelerations "Total number of decelerations whenever the vehicle deceleration is more than XYZ km/h/sec (where XYZ is a calibratible ...";
CM_ SG_ 2633938430 TrpNumberOfIdleShutdownOverrides "Total number of times an operator disables idle shutdown to prevent an engine shutdown, since the last trip reset.";
CM_ SG_ 2633938430 TripNumberOfIdleShutdowns "Total number of times the engine has been shutdown due to idling too long (at normal idle or fast idle) since the last trip ...";
CM_ SG_ 2633938430 TripNumberOfHotShutdowns "Total number of hot shutdowns since the last trip reset.  A hot shutdown is based on operation at high load or high engine ...";
CM_ BO_ 2348875518 "NOTE - Retarder may be disabled by commanding a torque limit of 0%.  Use of the limit mode allows the use of the ...";
CM_ SG_ 2348875518 MessageChecksum "The message checksum is used to verify the signal path from the transmitting device to the receiving device.";
CM_ SG_ 2348875518 MessageCounter "The message counter is used to detect situations where the transmitting ECU malfunction repeats the same frame all the ...";
CM_ SG_ 2348875518 EngRequestedTorqueHighResolution "This parameter displays an additional torque in percent of the reference engine torque.";
CM_ SG_ 2348875518 TSC1CtrlPurpose "State signal which indicates which control mode the sending device is using to generate the TSC1 command.  Note that ...";
CM_ SG_ 2348875518 TSC1TransRate "This parameter indicates the transmission rate at which the sending device will transmit the TSC1 message.  The engine ...";
CM_ SG_ 2348875518 EngRequestedTorque_TorqueLimit "Parameter provided to the engine or retarder in the torque/speed control message for controlling or limiting the output ...";
CM_ SG_ 2348875518 EngRequestedSpeed_SpeedLimit "Parameter provided to the engine from external sources in the torque/speed control message.  This is the engine speed ...";
CM_ SG_ 2348875518 OverrideCtrlModePriority "This field is used as an input to the engine or retarder to determine the priority of the Override Control Mode received in ...";
CM_ SG_ 2348875518 EngRequestedSpeedCtrlConditions "This mode tells the engine control system the governor characteristics that are desired during speed control.  The four ...";
CM_ SG_ 2348875518 EngOverrideCtrlMode "The override control mode defines which sort of command is used: 00 Override disabled - Disable any existing control commanded by the source of this command.";
CM_ BO_ 2566766846 "Used to notify the transit link devices of real-time boarding and exiting passengers or to indicate the total number of ...";
CM_ SG_ 2566766846 TransitRunStatus "Status of the run switch for the vehicle.";
CM_ SG_ 2566766846 VehicleUseStatus "Used to indicate the proper or unauthorized use of the vehicle. The administrative control device or any device issuing the ...";
CM_ SG_ 2566766846 SilentAlarmStatus "Used to report silent alarm push button status.";
CM_ SG_ 2566766846 PatronCount "Count of the number of passengers on a transit vehicle.  If the type of passenger count (SPN 3043) is 0, the patron count ...";
CM_ SG_ 2566766846 TypeOfPassengerCount "Used to notify transit link devices of the type of passenger counting system used in the vehicle.  Some passenger ...";
CM_ BO_ 2566765310 "Used to report alarms of the fare collection unit.";
CM_ SG_ 2566765310 FareboxAlarmIdentifier "Indicates the nature of the farebox alarm condition.";
CM_ SG_ 2566765310 FareboxEmergencyStatus "Indicates if a farebox emergency condition exists.";
CM_ BO_ 2566765566 "Used to report stop level point of sale detail.";
CM_ SG_ 2566765566 TransferSold "Indicates that a transfer was sold or issued on this transaction including its type and/or restrictions. The final definitions of ...";
CM_ SG_ 2566765566 TransferType "The kind of transfer used ...";
CM_ SG_ 2566765566 TypeOfService "The type of service provided ...";
CM_ SG_ 2566765566 InitialFareAgency "Identifies where the initial fare is paid ...";
CM_ SG_ 2566765566 PassCategory "Agency defined value indicating the category of the passenger associated with this fare ...";
CM_ SG_ 2566765566 FareValidity "Agency defined value indicating validity of this fare ...";
CM_ SG_ 2566765566 PaymentDetails "Payment details.";
CM_ SG_ 2566765566 TypeOfFare "Type of Fare ...";
CM_ SG_ 2566765566 PassengerType "Enumerated value representing the type/class of passenger, as defined by the agency.";
CM_ SG_ 2566765566 TransactionType "Enumerated value representing the type of transaction completed ...";
CM_ SG_ 2566765566 RouteNumber "The route number issuing the transfer.";
CM_ BO_ 2566765822 "Used to identify service, assignments, and fare preset detail of the fare collection unit.";
CM_ SG_ 2566765822 DriversFareboxSecurityCode "Security code for the farebox, numerical only.";
CM_ SG_ 2566765822 AssignedBlock "The agency defined block number for this trip ...";
CM_ SG_ 2566765822 AssignedRun "The agency defined run number for this trip ...";
CM_ SG_ 2566765822 AssignedRoute "The identity number assigned to this route.";
CM_ SG_ 2566765822 PatternNumber "The agency defined pattern number for this trip ...";
CM_ SG_ 2566765822 TripNumber "The identity number assigned to this trip.";
CM_ SG_ 2566765822 FarePresets "Fare Presets ...";
CM_ SG_ 2566765822 TripDirection "The general direction of travel for this trip.";
CM_ SG_ 2566765822 TripStatus "Trip Status ...";
CM_ SG_ 2566765822 FareboxServiceStatus "Indicates if the farebox is in or out of service.";
CM_ BO_ 2566766078 "Status and configuration of the device used for intersection preemption.";
CM_ SG_ 2566766078 VehicleID "Numerical designation of the vehicle.   65535 is used to represent the vehicle ID is not available.";
CM_ SG_ 2566766078 StrobeActivationCtrlStatus "Strobe activation control status ...";
CM_ SG_ 2566766078 TransitDoorEnable "Transit door enable ...";
CM_ SG_ 2566766078 PriorityOfRespSentByEmitter "Priority of response sent by emitter ...";
CM_ SG_ 2566766078 IntrsctnPrmptionRequest_Response "Status of the intersection signal preemption ...";
CM_ SG_ 2566766078 TransitRouteIDUsage "Transit route ID usage ...";
CM_ SG_ 2566766078 RangeCodeEnable "Range code enable ...";
CM_ BO_ 2566766590 "Identification of a transit route milepost ...";
CM_ SG_ 2566766590 NmbrOfBytsInThMlpstIdntification "Number of bytes in the Milepost Identification.  This parameter identifies the length, in bytes, of the data in SPN 590 ...";
CM_ BO_ 2566766334 "The current route assigned to this transit vehicle. The transit route information may be entered into different devices by ...";
CM_ SG_ 2566766334 NmbrOfBytsInThTrnstAssgndBlckIdn "Number of bytes in the Transit Assigned Block Identity.  This parameter identifies the length, in bytes, of the data in SPN ...";
CM_ SG_ 2566766334 NmbrOfBytsInThTrnstAssgndRnIdntt "Number of bytes in the Transit Assigned Run Identity.  This parameter identifies the length, in bytes, of the data in SPN ...";
CM_ SG_ 2566766334 NmbrOfBytsInThTrnstAssgndRtIdntt "Number of bytes in the Transit Assigned Route Identity.  This parameter identifies the length, in bytes, of the data in SPN ...";
CM_ SG_ 2566766334 Agency "The identity of the agency involved in this transaction ...";
CM_ BO_ 2561605374 "Tire Pressure Reference Setting";
CM_ SG_ 2561605374 TireLocation "Identifies which tire is associated with the parametric data in this PGN.";
CM_ BO_ 2566765054 "Tire Pressure Reference Information";
CM_ SG_ 2566765054 TireLocation "Identifies which tire is associated with the parametric data in this PGN.";
CM_ SG_ 2633923326 SteerChannelTirePress "The latest gage pressure reading of the steer group of tires, as opposed to the pressure in each tire.";
CM_ SG_ 2633923326 DriveChannelTirePress "The latest gage pressure reading of the drive group of tires, as opposed to the pressure in each tire.";
CM_ SG_ 2633923326 TrailerTagOrPushChannelTirePress "The latest gage pressure reading of the trailer, tag, or push group of tires, as opposed to the pressure in each tire.";
CM_ SG_ 2633923070 SteerChannelTirePressTarget "The tire pressure control system’s target gage pressure for the steer group of tires.";
CM_ SG_ 2633923070 DriveChannelTirePressTarget "The tire pressure control system’s target gage pressure for the drive group of tires.";
CM_ SG_ 2633923070 TrlrTgOrPshChnnelTirePressTarget "The tire pressure control system’s target gage pressure for the trailer, tag, or push group of tires.";
CM_ SG_ 2633922814 PCUTrilerTagOrPushSolenoidStatus "Current state of the trailer, tag, or push solenoid used to implement a tire pressure control system in its pneumatic control ...";
CM_ SG_ 2633922814 PCUSupplySolenoidStatus "Current state of the supply solenoid used to implement a tire pressure control system in its pneumatic control unit (PCU).";
CM_ SG_ 2633922814 PCUCtrlSolenoidStatus "Current state of the control solenoid used to implement a tire pressure control system in its pneumatic control unit (PCU).";
CM_ SG_ 2633922814 PCUDeflateSolenoidStatus "Current state of the deflate solenoid used to implement a tire pressure control system in its pneumatic control unit (PCU).";
CM_ SG_ 2633922814 TirePressSupplySwitchStatus "Current state of an open/closed type switch used to determine if adequate pressure exists for system implementation.";
CM_ SG_ 2633922814 PCUSteerSolenoidStatus "Current state of the steer solenoid used to implement a tire pressure control system in its pneumatic control unit (PCU).";
CM_ SG_ 2633922814 PCUDriveSolenoidStatus "Current state of the drive solenoid used to implement a tire pressure control system in its pneumatic control unit (PCU).";
CM_ SG_ 2633922814 DriveChannelMode "Indicates the functional mode of trailer/tag channel of the tire pressure control system.";
CM_ SG_ 2633922814 Trailer_tagChannelMode "Indicates the functional mode of trailer/tag channel of the tire pressure control system.";
CM_ SG_ 2633922814 SteerChannelMode "Indicates the functional mode of steer channel of the tire pressure control system.";
CM_ SG_ 2633922814 TirePressCheckInterval "The interval at which the system will check the tire pressures (e.g., 5, 10, 15 min.).";
CM_ BO_ 2566845694 "Tire Condition";
CM_ SG_ 2566845694 TirePressThresholdDetection_13 "Signal indicating the pressure level of the tire.";
CM_ SG_ 2566845694 TirePressThresholdDetection_12 "Signal indicating the pressure level of the tire.";
CM_ SG_ 2566845694 TirePressThresholdDetection_11 "Signal indicating the pressure level of the tire.";
CM_ SG_ 2566845694 TirePressThresholdDetection_10 "Signal indicating the pressure level of the tire.";
CM_ SG_ 2566845694 TirePressThresholdDetection_01 "Signal indicating the pressure level of the tire.";
CM_ SG_ 2566845694 TirePress_33 "Pressure at which air is contained in cavity formed by tire and rim.";
CM_ SG_ 2566845694 TirePress_32 "Pressure at which air is contained in cavity formed by tire and rim.";
CM_ SG_ 2566845694 TirePress_31 "Pressure at which air is contained in cavity formed by tire and rim.";
CM_ SG_ 2566845694 TirePress_30 "Pressure at which air is contained in cavity formed by tire and rim.";
CM_ SG_ 2566845694 TirePress_23 "Pressure at which air is contained in cavity formed by tire and rim.";
CM_ SG_ 2566845694 TirePress_22 "Pressure at which air is contained in cavity formed by tire and rim.";
CM_ SG_ 2566845694 TirePress_21 "Pressure at which air is contained in cavity formed by tire and rim.";
CM_ SG_ 2566845694 TirePress_20 "Pressure at which air is contained in cavity formed by tire and rim.";
CM_ SG_ 2566845694 TirePress_13 "Pressure at which air is contained in cavity formed by tire and rim.";
CM_ SG_ 2566845694 TirePress_12 "Pressure at which air is contained in cavity formed by tire and rim.";
CM_ SG_ 2566845694 TirePress_11 "Pressure at which air is contained in cavity formed by tire and rim.";
CM_ SG_ 2566845694 TirePress_10 "Pressure at which air is contained in cavity formed by tire and rim.";
CM_ SG_ 2566845694 TireAirLeakageRate_33 "The pressure loss rate of a tire.";
CM_ SG_ 2566845694 TireAirLeakageRate_32 "The pressure loss rate of a tire.";
CM_ SG_ 2566845694 TireAirLeakageRate_31 "The pressure loss rate of a tire.";
CM_ SG_ 2566845694 TireAirLeakageRate_30 "The pressure loss rate of a tire.";
CM_ SG_ 2566845694 TireAirLeakageRate_23 "The pressure loss rate of a tire.";
CM_ SG_ 2566845694 TireAirLeakageRate_22 "The pressure loss rate of a tire.";
CM_ SG_ 2566845694 TireAirLeakageRate_21 "The pressure loss rate of a tire.";
CM_ SG_ 2566845694 TireAirLeakageRate_20 "The pressure loss rate of a tire.";
CM_ SG_ 2566845694 TireAirLeakageRate_13 "The pressure loss rate of a tire.";
CM_ SG_ 2566845694 TireAirLeakageRate_12 "The pressure loss rate of a tire.";
CM_ SG_ 2566845694 TireAirLeakageRate_11 "The pressure loss rate of a tire.";
CM_ SG_ 2566845694 TireAirLeakageRate_10 "The pressure loss rate of a tire.";
CM_ SG_ 2566845694 TireAirLeakageRate_01 "The pressure loss rate of a tire.";
CM_ SG_ 2566845694 TireAirLeakageRate_00 "The pressure loss rate of a tire.";
CM_ SG_ 2566845694 CTIWheelSensorStatus_33 "Indicates whether the wheel is being monitored by the CTI controller.";
CM_ SG_ 2566845694 CTIWheelSensorStatus_32 "Indicates whether the wheel is being monitored by the CTI controller.";
CM_ SG_ 2566845694 CTIWheelSensorStatus_31 "Indicates whether the wheel is being monitored by the CTI controller.";
CM_ SG_ 2566845694 CTIWheelSensorStatus_30 "Indicates whether the wheel is being monitored by the CTI controller.";
CM_ SG_ 2566845694 CTIWheelSensorStatus_23 "Indicates whether the wheel is being monitored by the CTI controller.";
CM_ SG_ 2566845694 CTIWheelSensorStatus_22 "Indicates whether the wheel is being monitored by the CTI controller.";
CM_ SG_ 2566845694 CTIWheelSensorStatus_21 "Indicates whether the wheel is being monitored by the CTI controller.";
CM_ SG_ 2566845694 CTIWheelSensorStatus_20 "Indicates whether the wheel is being monitored by the CTI controller.";
CM_ SG_ 2566845694 CTIWheelSensorStatus_13 "Indicates whether the wheel is being monitored by the CTI controller.";
CM_ SG_ 2566845694 CTIWheelSensorStatus_12 "Indicates whether the wheel is being monitored by the CTI controller.";
CM_ SG_ 2566845694 CTIWheelSensorStatus_11 "Indicates whether the wheel is being monitored by the CTI controller.";
CM_ SG_ 2566845694 CTIWheelSensorStatus_10 "Indicates whether the wheel is being monitored by the CTI controller.";
CM_ SG_ 2566845694 CTIWheelSensorStatus_01 "Indicates whether the wheel is being monitored by the CTI controller.";
CM_ SG_ 2566845694 CTIWheelEndElectricalFault_33 "Indicates the status of electrical fault on CTI wheel interface.";
CM_ SG_ 2566845694 CTIWheelEndElectricalFault_32 "Indicates the status of electrical fault on CTI wheel interface.";
CM_ SG_ 2566845694 CTIWheelEndElectricalFault_31 "Indicates the status of electrical fault on CTI wheel interface.";
CM_ SG_ 2566845694 CTIWheelEndElectricalFault_30 "Indicates the status of electrical fault on CTI wheel interface.";
CM_ SG_ 2566845694 CTIWheelEndElectricalFault_23 "Indicates the status of electrical fault on CTI wheel interface.";
CM_ SG_ 2566845694 CTIWheelEndElectricalFault_22 "Indicates the status of electrical fault on CTI wheel interface.";
CM_ SG_ 2566845694 CTIWheelEndElectricalFault_21 "Indicates the status of electrical fault on CTI wheel interface.";
CM_ SG_ 2566845694 CTIWheelEndElectricalFault_20 "Indicates the status of electrical fault on CTI wheel interface.";
CM_ SG_ 2566845694 CTIWheelEndElectricalFault_13 "Indicates the status of electrical fault on CTI wheel interface.";
CM_ SG_ 2566845694 CTIWheelEndElectricalFault_12 "Indicates the status of electrical fault on CTI wheel interface.";
CM_ SG_ 2566845694 CTIWheelEndElectricalFault_11 "Indicates the status of electrical fault on CTI wheel interface.";
CM_ SG_ 2566845694 CTIWheelEndElectricalFault_10 "Indicates the status of electrical fault on CTI wheel interface.";
CM_ SG_ 2566845694 CTIWheelEndElectricalFault_01 "Indicates the status of electrical fault on CTI wheel interface.";
CM_ SG_ 2566845694 CTITireStatus_33 "Indicates the status of the tire.";
CM_ SG_ 2566845694 CTITireStatus_32 "Indicates the status of the tire.";
CM_ SG_ 2566845694 CTITireStatus_31 "Indicates the status of the tire.";
CM_ SG_ 2566845694 CTITireStatus_30 "Indicates the status of the tire.";
CM_ SG_ 2566845694 CTITireStatus_23 "Indicates the status of the tire.";
CM_ SG_ 2566845694 CTITireStatus_22 "Indicates the status of the tire.";
CM_ SG_ 2566845694 CTITireStatus_21 "Indicates the status of the tire.";
CM_ SG_ 2566845694 CTITireStatus_20 "Indicates the status of the tire.";
CM_ SG_ 2566845694 CTITireStatus_13 "Indicates the status of the tire.";
CM_ SG_ 2566845694 CTITireStatus_12 "Indicates the status of the tire.";
CM_ SG_ 2566845694 CTITireStatus_11 "Indicates the status of the tire.";
CM_ SG_ 2566845694 CTITireStatus_10 "Indicates the status of the tire.";
CM_ SG_ 2566845694 CTITireStatus_01 "Indicates the status of the tire.";
CM_ SG_ 2566845694 TireTemp_11 "Temperature at the surface of the tire sidewall.";
CM_ SG_ 2566845694 TireTemp_33 "Temperature at the surface of the tire sidewall.";
CM_ SG_ 2566845694 TireTemp_32 "Temperature at the surface of the tire sidewall.";
CM_ SG_ 2566845694 TireTemp_31 "Temperature at the surface of the tire sidewall.";
CM_ SG_ 2566845694 TireTemp_30 "Temperature at the surface of the tire sidewall.";
CM_ SG_ 2566845694 TireTemp_23 "Temperature at the surface of the tire sidewall.";
CM_ SG_ 2566845694 TireTemp_22 "Temperature at the surface of the tire sidewall.";
CM_ SG_ 2566845694 TireTemp_21 "Temperature at the surface of the tire sidewall.";
CM_ SG_ 2566845694 TireTemp_20 "Temperature at the surface of the tire sidewall.";
CM_ SG_ 2566845694 TireTemp_13 "Temperature at the surface of the tire sidewall.";
CM_ SG_ 2566845694 TireTemp_12 "Temperature at the surface of the tire sidewall.";
CM_ SG_ 2566845694 TireTemp_10 "Temperature at the surface of the tire sidewall.";
CM_ SG_ 2566845694 TireTemp_01 "Temperature at the surface of the tire sidewall.";
CM_ SG_ 2566845694 TireTemp_00 "Temperature at the surface of the tire sidewall.";
CM_ SG_ 2566845694 TirePressThresholdDetection_33 "Signal indicating the pressure level of the tire.";
CM_ SG_ 2566845694 TirePressThresholdDetection_32 "Signal indicating the pressure level of the tire.";
CM_ SG_ 2566845694 TirePressThresholdDetection_31 "Signal indicating the pressure level of the tire.";
CM_ SG_ 2566845694 TirePressThresholdDetection_30 "Signal indicating the pressure level of the tire.";
CM_ SG_ 2566845694 TirePressThresholdDetection_23 "Signal indicating the pressure level of the tire.";
CM_ SG_ 2566845694 TirePressThresholdDetection_22 "Signal indicating the pressure level of the tire.";
CM_ SG_ 2566845694 TirePressThresholdDetection_21 "Signal indicating the pressure level of the tire.";
CM_ SG_ 2566845694 TirePressThresholdDetection_20 "Signal indicating the pressure level of the tire.";
CM_ SG_ 2566845694 TirePressThresholdDetection_00 "Signal indicating the pressure level of the tire.";
CM_ SG_ 2566845694 TirePress_01 "Pressure at which air is contained in cavity formed by tire and rim.";
CM_ SG_ 2566845694 TirePress_00 "Pressure at which air is contained in cavity formed by tire and rim.";
CM_ SG_ 2566845694 CTIWheelSensorStatus_00 "Indicates whether the wheel is being monitored by the CTI controller.";
CM_ SG_ 2566845694 CTIWheelEndElectricalFault_00 "Indicates the status of electrical fault on CTI wheel interface.";
CM_ SG_ 2566845694 CTITireStatus_00 "Indicates the status of the tire.";
CM_ SG_ 2566845694 TireLocation "Identifies which tire is associated with the parametric data in this PGN.";
CM_ SG_ 2633939966 TripFanOnTimeDueToTheA_CSystem "Total time the fan has been on due to the A/C system since the last trip reset.  For the time to be accumulated against the ...";
CM_ SG_ 2633939966 TripFanOnTimeDueToAManualSwitch "Total time the fan has been on due to manual activation by the operator (i.e., excluding time on due to automatic triggers) ...";
CM_ SG_ 2633939966 TripFanOnTimeDueToTheEngSystem "Total time the fan has been on due to engine triggers (i.e., excluding time on due to an operator manual switch or A/C ...";
CM_ SG_ 2633939966 TripFanOnTime "Total time the fan has been on (due to an automatic trigger or manual trigger) since the last trip reset.  The fan could be ...";
CM_ SG_ 2633939710 TripDistanceInTopGear "Total distance accumulated while the vehicle has operated in top gear for a calibrated minimum time since the last trip ...";
CM_ SG_ 2633939710 TripGearDownDistance "Total distance accumulated while the vehicle has operated in the gear which is one gear down from top gear and exceeds ...";
CM_ SG_ 2633939710 TripDistanceOnVSL "Total distance accumulated while the engine torque mode is road speed governing since the last trip reset.";
CM_ SG_ 2564161278 AdjustLocalHourOffset "The hour component for setting the offset between the UTC (Universal Time Coordinate) time and date and a the local ...";
CM_ SG_ 2564161278 AdjustLocalMinuteOffset "The minute component for setting the offset between the UTC (Universal Time Coordinate) time and date and a the local ...";
CM_ SG_ 2564161278 AdjustYear "The year component for setting the current calendar date.  This should be reported as the year component of the current ...";
CM_ SG_ 2564161278 AdjustDay "The day component for setting the current calendar date.  This should be reported as the day component of the current ...";
CM_ SG_ 2564161278 AdjustMonth "The month component for setting the current calendar date.  This should be reported as the month component of the ...";
CM_ SG_ 2564161278 AdjustHours "The hours component for setting the current time of day.  This should be reported as the hours component of the current ...";
CM_ SG_ 2564161278 AdjustMinutes "The minutes component for setting the current time of day.  This should be reported as the minutes component of the ...";
CM_ SG_ 2564161278 AdjustSeconds "The seconds component for setting the current time of day.  This should be reported as the seconds component of the ...";
CM_ SG_ 2566842110 LocalHourOffset "The hour component of the offset between the UTC (Universal Time Coordinate) time and date and a local time zone time ...";
CM_ SG_ 2566842110 LocalMinuteOffset "The minute component of the offset between the UTC time and date and a local time zone time and date.  This is the ...";
CM_ SG_ 2566842110 Year "The year component of the current calendar date.  This should be reported as the year component of the current date at ...";
CM_ SG_ 2566842110 Day "The day component of the current calendar date.  This should be reported as the day component of the current date at ...";
CM_ SG_ 2566842110 Month "The month component of the current calendar date.  This should be reported as the month component of the current date ...";
CM_ SG_ 2566842110 Hours "The hour component of the current time of day.  This should be reported as the hour component of the current time at ...";
CM_ SG_ 2566842110 Minutes "The minutes component of the current time of day.  This should be reported as the minutes component of the current time ...";
CM_ SG_ 2566842110 Seconds "The seconds component of the current time of day.  This should be reported as the seconds component of the current ...";
CM_ SG_ 2566821630 EngDsrdTrboWastegateActuator2Pos "The Requested Valve position of the Turbocharger Wastegate Valve 2, commanded by the engine ECM. A value of 0% ...";
CM_ SG_ 2566821630 EngTrbWstgateActuator1TempStatus "Used to identify the status of the Engine Turbocharger Wastegate Actuator 1 drive circuitry temperature.  Temperature ...";
CM_ SG_ 2566821630 EngTrbWstgtActtor1PreliminaryFMI "Used to identify the applicable J1939-73 FMI detected in the Engine Turbocharger Wastegate Actuator 1 by the ...";
CM_ SG_ 2566821630 EngDsrdTrboWastegateActuator1Pos "The Requested Valve position of the Turbocharger Wastegate Valve 1, commanded by the engine ECM. A value of 0% ...";
CM_ SG_ 2566821630 EngTrbWstgteActuatorCtrlAirPress "Gage pressure of the air used to control the actuator which opens and closes the wastegate valve.";
CM_ SG_ 2566821630 EngTurboWastegateActuator4Pos "Position of the wastegate drive.  A value of 0% represents fully closed and a value of 100% represents fully open.";
CM_ SG_ 2566821630 EngTurboWastegateActuator3Pos "Position of the wastegate drive.  A value of 0% represents fully closed and a value of 100% represents fully open.";
CM_ SG_ 2566821630 EngTurboWastegateActuator2Pos "Position of the wastegate drive.  A value of 0% represents fully closed and a value of 100% represents fully open.";
CM_ SG_ 2566821630 EngTurboWastegateActuator1Pos "Position of the wastegate drive.  A value of 0% represents fully closed and a value of 100% represents fully open.";
CM_ SG_ 2365484286 TachographVehicleSpeed "Speed of the vehicle registered by the tachograph.";
CM_ SG_ 2365484286 TachographOutputShaftSpeed "Calculated speed of the transmission output shaft.";
CM_ SG_ 2365484286 DirectionIndicator "Indicates the direction of the vehicle.";
CM_ SG_ 2365484286 TachographPerformance "Indicates the tachograph performance; including electronic or mechanical analysis, instrument analysis, speed sensor ...";
CM_ SG_ 2365484286 HandlingInformation "Indicates that handling information is present.  Information could include “no printer paper”, “no driver card”, etc.";
CM_ SG_ 2365484286 SystemEvent "Indicates that a tachograph event has occurred.  This may include power supply interruption, interruption of the speed ...";
CM_ SG_ 2365484286 DriverCardDriver2 "Indicates the presence of a driver card ...";
CM_ SG_ 2365484286 Driver2TimeRelatedStates "Indicates if the driver approaches or exceeds working time limits (or other limits).";
CM_ SG_ 2365484286 VehicleOverspeed "Indicates whether the vehicle is exceeding the legal speed limit set in the tachograph.";
CM_ SG_ 2365484286 DriverCardDriver1 "Indicates the presence of a driver card ...";
CM_ SG_ 2365484286 Driver1TimeRelatedStates "Indicates if the driver approaches or exceeds working time limits (or other limits).";
CM_ SG_ 2365484286 VehicleMotion "Indicates whether motion of the vehicle is detected or not.";
CM_ SG_ 2365484286 Driver2WorkingState "State of work of the driver.";
CM_ SG_ 2365484286 Driver1WorkingState "State of work of the driver.";
BA_DEF_ SG_  "SigType" ENUM  "Default","Range","RangeSigned","ASCII","Discrete","Control","ReferencePGN","DTC","StringDelimiter","StringLength","StringLengthControl";
BA_DEF_ SG_  "GenSigStartValue" INT 0 10000;
BA_DEF_ SG_  "GenSigSendType" ENUM  "Cyclic","OnWrite","OnWriteWithRepetition","OnChange","OnChangeWithRepetition","IfActive","IfActiveWithRepetition","NoSigSendType";
BA_DEF_ SG_  "GenSigILSupport" ENUM  "No","Yes";
BA_DEF_ SG_  "GenSigEVName" STRING ;
BA_DEF_ SG_  "SPN" INT 0 524287;
BA_DEF_ BO_  "GenMsgStartDelayTime" INT 0 100000;
BA_DEF_ BO_  "GenMsgILSupport" ENUM  "No","Yes";
BA_DEF_ BO_  "GenMsgRequestable" INT 0 1;
BA_DEF_ BO_  "GenMsgSendType" ENUM  "cyclic","NotUsed","NotUsed","NotUsed","NotUsed","NotUsed","NotUsed","IfActive","noMsgSendType";
BA_DEF_ BO_  "VFrameFormat" ENUM  "StandardCAN","ExtendedCAN","reserved","J1939PG";
BA_DEF_ BO_  "GenMsgCycleTime" INT 0 3600000;
BA_DEF_ SG_  "SystemSignalLongSymbol" STRING ;
BA_DEF_DEF_  "SigType" "Default";
BA_DEF_DEF_  "GenSigStartValue" 0;
BA_DEF_DEF_  "GenSigSendType" "NoSigSendType";
BA_DEF_DEF_  "GenSigILSupport" "Yes";
BA_DEF_DEF_  "GenSigEVName" "Env@Nodename_@Signame";
BA_DEF_DEF_  "SPN" 0;
BA_DEF_DEF_  "GenMsgStartDelayTime" 0;
BA_DEF_DEF_  "GenMsgILSupport" "Yes";
BA_DEF_DEF_  "GenMsgRequestable" 1;
BA_DEF_DEF_  "GenMsgSendType" "noMsgSendType";
BA_DEF_DEF_  "VFrameFormat" "J1939PG";
BA_DEF_DEF_  "GenMsgCycleTime" 0;
BA_DEF_DEF_  "SystemSignalLongSymbol" "";
BA_ "GenMsgSendType" BO_ 2566834686 0;
BA_ "GenMsgCycleTime" BO_ 2566834686 100;
BA_ "GenMsgSendType" BO_ 2550398718 0;
BA_ "GenMsgCycleTime" BO_ 2550398718 10;
BA_ "GenMsgSendType" BO_ 2566833406 0;
BA_ "GenMsgCycleTime" BO_ 2566833406 100;
BA_ "GenMsgSendType" BO_ 2365507326 0;
BA_ "GenMsgCycleTime" BO_ 2365507326 100;
BA_ "GenMsgSendType" BO_ 2565013246 0;
BA_ "GenMsgCycleTime" BO_ 2565013246 100;
BA_ "GenMsgSendType" BO_ 2566807038 0;
BA_ "GenMsgCycleTime" BO_ 2566807038 500;
BA_ "GenMsgSendType" BO_ 2365480958 0;
BA_ "GenMsgCycleTime" BO_ 2365480958 50;
BA_ "GenMsgSendType" BO_ 2566808062 0;
BA_ "GenMsgCycleTime" BO_ 2566808062 100;
BA_ "GenMsgSendType" BO_ 2566808574 0;
BA_ "GenMsgCycleTime" BO_ 2566808574 1000;
BA_ "GenMsgSendType" BO_ 2566809086 0;
BA_ "GenMsgCycleTime" BO_ 2566809086 100;
BA_ "GenMsgSendType" BO_ 2564947710 0;
BA_ "GenMsgCycleTime" BO_ 2564947710 100;
BA_ "GenMsgSendType" BO_ 2566834430 0;
BA_ "GenMsgCycleTime" BO_ 2566834430 100;
BA_ "GenMsgSendType" BO_ 2365481214 0;
BA_ "GenMsgCycleTime" BO_ 2365481214 100;
BA_ "GenMsgSendType" BO_ 2566808318 0;
BA_ "GenMsgCycleTime" BO_ 2566808318 100;
BA_ "GenMsgSendType" BO_ 2566808830 0;
BA_ "GenMsgCycleTime" BO_ 2566808830 100;
BA_ "GenMsgSendType" BO_ 2565144318 0;
BA_ "GenMsgCycleTime" BO_ 2565144318 100;
BA_ "GenMsgSendType" BO_ 2565209854 0;
BA_ "GenMsgCycleTime" BO_ 2565209854 100;
BA_ "GenMsgSendType" BO_ 2566806782 0;
BA_ "GenMsgCycleTime" BO_ 2566806782 100;
BA_ "GenMsgSendType" BO_ 2566807294 0;
BA_ "GenMsgCycleTime" BO_ 2566807294 1000;
BA_ "GenMsgSendType" BO_ 2349137662 2;
BA_ "GenMsgCycleTime" BO_ 2349137662 20;
BA_ "GenMsgSendType" BO_ 2566848510 0;
BA_ "GenMsgCycleTime" BO_ 2566848510 10000;
BA_ "GenMsgSendType" BO_ 2566804222 0;
BA_ "GenMsgCycleTime" BO_ 2566804222 1000;
BA_ "GenMsgSendType" BO_ 2566845438 0;
BA_ "GenMsgCycleTime" BO_ 2566845438 5000;
BA_ "GenMsgSendType" BO_ 2566809854 0;
BA_ "GenMsgCycleTime" BO_ 2566809854 1000;
BA_ "GenMsgSendType" BO_ 2566832638 0;
BA_ "GenMsgCycleTime" BO_ 2566832638 1000;
BA_ "GenMsgSendType" BO_ 2565868030 0;
BA_ "GenMsgCycleTime" BO_ 2565868030 10;
BA_ "GenMsgSendType" BO_ 2566840574 0;
BA_ "GenMsgCycleTime" BO_ 2566840574 100;
BA_ "GenMsgSendType" BO_ 2348875518 0;
BA_ "GenMsgCycleTime" BO_ 2348875518 10;
BA_ "GenMsgSendType" BO_ 2566845694 0;
BA_ "GenMsgCycleTime" BO_ 2566845694 10000;
BA_ "GenMsgSendType" BO_ 2566821630 0;
BA_ "GenMsgCycleTime" BO_ 2566821630 100;
BA_ "GenMsgSendType" BO_ 2365484286 0;
BA_ "GenMsgCycleTime" BO_ 2365484286 50;
BA_ "SPN" SG_ 2566834686 RoadCurvature 1591;
BA_ "SigType" SG_ 2566834686 PneumaticControlLine 4;
BA_ "SigType" SG_ 2566834686 ABSOffroadRequest 4;
BA_ "SigType" SG_ 2566834686 TwoElCircuitsBrakeDemand 4;
BA_ "SigType" SG_ 2566834686 VehicleRetarderCtrlActive 4;
BA_ "SigType" SG_ 2550398718 ActualRetarderPercTorque 1;
BA_ "SigType" SG_ 2550398718 Wheel_BasedVehicleSpeed 1;
BA_ "SigType" SG_ 2550398718 SupplyLineBrakingRequest 4;
BA_ "SigType" SG_ 2550398718 VDCActive 4;
BA_ "SigType" SG_ 2550398718 AutomTowedVehBreakActive 4;
BA_ "SigType" SG_ 2550398718 VehicleServiceBrakeActive 4;
BA_ "SigType" SG_ 2550398718 VehicleRetarderCtrlActive 4;
BA_ "SigType" SG_ 2550398718 VehicleABSActive 4;
BA_ "SigType" SG_ 2566833406 ReferenceRetarderTorque 1;
BA_ "SPN" SG_ 2566833406 ReferenceRetarderTorque 556;
BA_ "SigType" SG_ 2566833406 SupplyLineBrakingRequest 4;
BA_ "SigType" SG_ 2566833406 LoadingRampApproachAssist 4;
BA_ "SigType" SG_ 2566833406 SpringBrakeEngaged 4;
BA_ "SigType" SG_ 2566833406 ElectrLoadPropFunc 4;
BA_ "SigType" SG_ 2566833406 SpringBrakeInstalled 4;
BA_ "SigType" SG_ 2566833406 ElecSupplyOfNonBrakingSys 4;
BA_ "SigType" SG_ 2566833406 AmberWarningSignalReq 4;
BA_ "SigType" SG_ 2566833406 RedWarningSignalRequest 4;
BA_ "SigType" SG_ 2566833406 VehicleElectrSupplySuff 4;
BA_ "SigType" SG_ 2566833406 AutomTowedVehBreakActive 4;
BA_ "SigType" SG_ 2566833406 VehicleServiceBrakeActive 4;
BA_ "SigType" SG_ 2566833406 VehicleRetarderCtrlActive 4;
BA_ "SigType" SG_ 2566833406 VehicleABSActive 4;
BA_ "SigType" SG_ 2365507326 VehiclePneumSupplySuff 4;
BA_ "SigType" SG_ 2365507326 BrakeTemperatureStatus 4;
BA_ "SigType" SG_ 2365507326 BrakeLiningSufficient 4;
BA_ "SigType" SG_ 2365507326 TyrePressureSufficient 4;
BA_ "SigType" SG_ 2565013246 ODDRequest 4;
BA_ "SigType" SG_ 2565013246 AntiTheftDeviceReq 4;
BA_ "SigType" SG_ 2566807038 MaxVehicleSpeedLimit 1;
BA_ "SPN" SG_ 2566807038 MaxVehicleSpeedLimit 74;
BA_ "SigType" SG_ 2365480958 VehicleSpeed 1;
BA_ "SigType" SG_ 2365480958 PercentLoadAtCurrentSpeed 1;
BA_ "SigType" SG_ 2365480958 EngineSpeed 1;
BA_ "SigType" SG_ 2365480958 ActualEngine_PercTorque 1;
BA_ "SigType" SG_ 2365480958 DriversDemandEngine_PercTorque 1;
BA_ "SigType" SG_ 2365480958 EngineRunning 4;
BA_ "SigType" SG_ 2365480958 EngineControlAllowed 4;
BA_ "SigType" SG_ 2566808062 ClutchIndptdPTOFeedback 4;
BA_ "SigType" SG_ 2566808062 AccelPedalPosition 1;
BA_ "SigType" SG_ 2566808062 AccelPedalLowIdleSwitch 4;
BA_ "SigType" SG_ 2566808062 StarterActive 4;
BA_ "SigType" SG_ 2566808062 PTOControlAllowed 4;
BA_ "SigType" SG_ 2566808062 SecEngineMtdPTOFeedback 4;
BA_ "SigType" SG_ 2566808062 FirstEngineMtdPTOFeedback 4;
BA_ "SigType" SG_ 2566808062 SecClutchDptdPTOFeedback 4;
BA_ "SigType" SG_ 2566808062 FirstClutchDpdtPTOFeedback 4;
BA_ "SigType" SG_ 2566808062 CurrentGear 1;
BA_ "SigType" SG_ 2566808062 PercentClutchSlip 1;
BA_ "SPN" SG_ 2566808062 PercentClutchSlip 522;
BA_ "SigType" SG_ 2566808574 ReferenceEngineTorque 1;
BA_ "SigType" SG_ 2566808574 FuelLevelWarning 4;
BA_ "SigType" SG_ 2566808574 EngineOilPressureWarning 4;
BA_ "SigType" SG_ 2566808574 EngineOilPressure 1;
BA_ "SigType" SG_ 2566808574 EngCoolantTemp 1;
BA_ "SPN" SG_ 2566808574 EngCoolantTemp 110;
BA_ "SigType" SG_ 2566808574 EngineOilTemperature 1;
BA_ "SigType" SG_ 2566809086 AmbientAirTemperature 1;
BA_ "SigType" SG_ 2566834430 AntiTheftDeviceStatus 4;
BA_ "SigType" SG_ 2566834430 ODDStatus 4;
BA_ "SigType" SG_ 2566808318 SecEngineMtdPTOSwitch 4;
BA_ "SigType" SG_ 2566808318 SecClutchDpdtPTOSwitch 4;
BA_ "SigType" SG_ 2566808318 FirstClutchDpdtPTOSwitch 4;
BA_ "SigType" SG_ 2566808318 OperatingPanelActive 4;
BA_ "SigType" SG_ 2566808318 RefusePackerStepSwitch 4;
BA_ "SigType" SG_ 2566808318 EngineStopSwitch 4;
BA_ "SigType" SG_ 2566808318 EngineStartSwitch 4;
BA_ "SigType" SG_ 2566808318 StarterLockoutSwitch 4;
BA_ "SigType" SG_ 2566808318 RqstedPercentClutchSlip 1;
BA_ "SigType" SG_ 2566808318 FirstEngineMtdPTOSwitch 4;
BA_ "SigType" SG_ 2566808318 ClutchIndpdtPTOSwitch 4;
BA_ "SigType" SG_ 2566808830 TrailerLeftSideMarkerLight 4;
BA_ "SigType" SG_ 2566808830 TrailerLeftReversingLight 4;
BA_ "SigType" SG_ 2566808830 TrailerLeftRearWidIndLight 4;
BA_ "SigType" SG_ 2566808830 TrailerLeftRearRegPltLight 4;
BA_ "SigType" SG_ 2566808830 TrailerLeftRearLight 4;
BA_ "SigType" SG_ 2566808830 TrailerLeftRearFogLight 4;
BA_ "SigType" SG_ 2566808830 TrailerLeftDirIndLight 4;
BA_ "SigType" SG_ 2566808830 TrailerLeftCrnMarkerLight 4;
BA_ "SigType" SG_ 2566808830 TrailerInteriorLight 4;
BA_ "SigType" SG_ 2566808830 TrailerWorkLamp 4;
BA_ "SigType" SG_ 2566808830 TrailerRotatingIdentLight 4;
BA_ "SigType" SG_ 2566808830 TrailerRightStopLight 4;
BA_ "SigType" SG_ 2566808830 TrailerRightSideMrkLight 4;
BA_ "SigType" SG_ 2566808830 TrailerRightReversingLight 4;
BA_ "SigType" SG_ 2566808830 TrailRightRearWidIndLight 4;
BA_ "SigType" SG_ 2566808830 TrailerRightRearRegPltLight 4;
BA_ "SigType" SG_ 2566808830 TrailerRightRearLight 4;
BA_ "SigType" SG_ 2566808830 TrailerRightRearFogLight 4;
BA_ "SigType" SG_ 2566808830 TrailerRightDirIndLight 4;
BA_ "SigType" SG_ 2566808830 TrailerRightCrnMarkerLight 4;
BA_ "SigType" SG_ 2566808830 TrailerRearWarningLight 4;
BA_ "SigType" SG_ 2566808830 TrailerLeftStopLight 4;
BA_ "SigType" SG_ 2565734142 ControlByte 1;
BA_ "SigType" SG_ 2565734142 FilterMode 1;
BA_ "SigType" SG_ 2565144318 ParkingAndTrailerAirPress 1;
BA_ "SigType" SG_ 2565144318 AuxEquipSupplyPressure 1;
BA_ "SigType" SG_ 2565144318 StopLevelChangeReq 4;
BA_ "SigType" SG_ 2565144318 RampLevelStorageReq 4;
BA_ "SigType" SG_ 2565144318 LevelControlReq 4;
BA_ "SigType" SG_ 2565144318 RampLevelReq 4;
BA_ "SigType" SG_ 2565144318 SteeringAxleLockingReq 4;
BA_ "SigType" SG_ 2565144318 LiftAxle2PositionReq 4;
BA_ "SigType" SG_ 2565144318 LiftAxle1PositionReq 4;
BA_ "SigType" SG_ 2565144318 TractionHelpReq 4;
BA_ "SigType" SG_ 2565144318 LevelChangeReqRearAxle 4;
BA_ "SigType" SG_ 2565144318 LevelChangeReqFrontAxle 4;
BA_ "SigType" SG_ 2565144318 RideHeightRequest 4;
BA_ "SigType" SG_ 2565209854 LevelControl 4;
BA_ "SigType" SG_ 2565209854 RampLevel 4;
BA_ "SigType" SG_ 2565209854 NormalLevel 4;
BA_ "SigType" SG_ 2565209854 StopLevelChangeAcknowledge 4;
BA_ "SigType" SG_ 2565209854 LevelChangeRearAxle 4;
BA_ "SigType" SG_ 2565209854 LevelChangeFrontAxle 4;
BA_ "SigType" SG_ 2565209854 RampLevelStorage 4;
BA_ "SigType" SG_ 2565209854 SteeringAxleLocking 4;
BA_ "SigType" SG_ 2565209854 LiftAxle2Pos 4;
BA_ "SPN" SG_ 2565209854 LiftAxle2Pos 1822;
BA_ "SigType" SG_ 2565209854 LiftAxle1Pos 4;
BA_ "SPN" SG_ 2565209854 LiftAxle1Pos 1743;
BA_ "SigType" SG_ 2565209854 RampLevelPosition 4;
BA_ "SigType" SG_ 2565209854 TractionHelp 4;
BA_ "SigType" SG_ 2565209854 LevelCtrlSysRideHeightLevel 4;
BA_ "SigType" SG_ 2566807294 TyreModulePowerSupply 4;
BA_ "SystemSignalLongSymbol" SG_ 2566764798 NOxConvertingCatalystAdsorberCom "NOxConvertingCatalystAdsorberCompleted";
BA_ "SystemSignalLongSymbol" SG_ 2566764798 NOxConvertingCatalystAdsorberEna "NOxConvertingCatalystAdsorberEnabled";
BA_ "SystemSignalLongSymbol" SG_ 2566764798 BoostPressureControlSystemComple "BoostPressureControlSystemCompleted";
BA_ "SystemSignalLongSymbol" SG_ 2566764798 BoostPressureControlSystemEnable "BoostPressureControlSystemEnabled";
BA_ "SPN" SG_ 2566764798 NumOfWarmUpsSinceDTCsCleared 3302;
BA_ "SPN" SG_ 2566764798 TimeSinceEngineStart 3301;
BA_ "SPN" SG_ 2564095742 DataSecurityParameter 1597;
BA_ "SPN" SG_ 2564095742 SecurityEntityType 1479;
BA_ "SPN" SG_ 2564095742 SecurityEntityLength 1596;
BA_ "SPN" SG_ 2349137662 XBRMessageChecksum 3188;
BA_ "SPN" SG_ 2349137662 XBRMessageCounter 3189;
BA_ "SPN" SG_ 2349137662 XBRUrgency 4099;
BA_ "SigType" SG_ 2349137662 XBRCtrlMode 5;
BA_ "SPN" SG_ 2349137662 XBRCtrlMode 2916;
BA_ "SPN" SG_ 2349137662 XBRPriority 2915;
BA_ "SigType" SG_ 2349137662 XBREBIMode 5;
BA_ "SPN" SG_ 2349137662 XBREBIMode 2914;
BA_ "SPN" SG_ 2349137662 ExtlAccelerationDemand 2920;
BA_ "SPN" SG_ 2566848510 EmssnCtrlSystmOprtrIndcmntSvrity 5826;
BA_ "SPN" SG_ 2566848510 DrvrWarningSystemIndicatorStatus 5825;
BA_ "SigType" SG_ 2566848510 OperatorShiftPrompt 5;
BA_ "SPN" SG_ 2566848510 OperatorShiftPrompt 5675;
BA_ "SigType" SG_ 2566848510 WaterInFuelIndicator 4;
BA_ "SPN" SG_ 2566848510 WaterInFuelIndicator 97;
BA_ "SigType" SG_ 2566843134 AxleLocation 1;
BA_ "SPN" SG_ 2566843134 AxleLocation 928;
BA_ "SigType" SG_ 2566843134 CargoWeight_30 1;
BA_ "SPN" SG_ 2566843134 CargoWeight_30 522230;
BA_ "SigType" SG_ 2566843134 CargoWeight_20 1;
BA_ "SPN" SG_ 2566843134 CargoWeight_20 522220;
BA_ "SigType" SG_ 2566843134 CargoWeight_10 1;
BA_ "SPN" SG_ 2566843134 CargoWeight_10 522210;
BA_ "SigType" SG_ 2566843134 CargoWeight_00 1;
BA_ "SPN" SG_ 2566843134 CargoWeight_00 522200;
BA_ "SigType" SG_ 2566843134 TrailerWeight_30 1;
BA_ "SPN" SG_ 2566843134 TrailerWeight_30 522130;
BA_ "SigType" SG_ 2566843134 TrailerWeight_20 1;
BA_ "SPN" SG_ 2566843134 TrailerWeight_20 522120;
BA_ "SigType" SG_ 2566843134 TrailerWeight_10 1;
BA_ "SPN" SG_ 2566843134 TrailerWeight_10 522110;
BA_ "SigType" SG_ 2566843134 TrailerWeight_00 1;
BA_ "SPN" SG_ 2566843134 TrailerWeight_00 522100;
BA_ "SigType" SG_ 2566843134 AxleWeight_30 1;
BA_ "SPN" SG_ 2566843134 AxleWeight_30 522030;
BA_ "SigType" SG_ 2566843134 AxleWeight_20 1;
BA_ "SPN" SG_ 2566843134 AxleWeight_20 522020;
BA_ "SigType" SG_ 2566843134 AxleWeight_10 1;
BA_ "SPN" SG_ 2566843134 AxleWeight_10 522010;
BA_ "SigType" SG_ 2566843134 AxleWeight_00 1;
BA_ "SPN" SG_ 2566843134 AxleWeight_00 522000;
BA_ "SigType" SG_ 2566804222 NetBatteryCurrent 1;
BA_ "SPN" SG_ 2566804222 NetBatteryCurrent 2579;
BA_ "SigType" SG_ 2566804222 AltCurrent 1;
BA_ "SPN" SG_ 2566804222 AltCurrent 1795;
BA_ "SigType" SG_ 2566819326 ECUPowerOutputSupplyVoltage3 1;
BA_ "SPN" SG_ 2566819326 ECUPowerOutputSupplyVoltage3 3599;
BA_ "SigType" SG_ 2566819326 ECUPowerOutputSupplyVoltage2 1;
BA_ "SPN" SG_ 2566819326 ECUPowerOutputSupplyVoltage2 3598;
BA_ "SigType" SG_ 2566819326 ECUPowerOutputSupplyVoltage1 1;
BA_ "SPN" SG_ 2566819326 ECUPowerOutputSupplyVoltage1 3597;
BA_ "SigType" SG_ 2566819326 BatteryPotential_PowerInput2 1;
BA_ "SPN" SG_ 2566819326 BatteryPotential_PowerInput2 444;
BA_ "SigType" SG_ 2566845438 Longitude 1;
BA_ "SPN" SG_ 2566845438 Longitude 585;
BA_ "SigType" SG_ 2566845438 Latitude 1;
BA_ "SPN" SG_ 2566845438 Latitude 584;
BA_ "SigType" SG_ 2566843646 VehicleIdentificationNumber 8;
BA_ "SPN" SG_ 2566843646 VehicleIdentificationNumber 237;
BA_ "SigType" SG_ 2566842366 TotalPowerTakeoffHours 1;
BA_ "SPN" SG_ 2566842366 TotalPowerTakeoffHours 248;
BA_ "SigType" SG_ 2566842366 TotalVehicleHours 1;
BA_ "SPN" SG_ 2566842366 TotalVehicleHours 246;
BA_ "SigType" SG_ 2566809854 HydOilLevel 1;
BA_ "SPN" SG_ 2566809854 HydOilLevel 2602;
BA_ "SigType" SG_ 2566809854 WinchOilPressSwitch 4;
BA_ "SPN" SG_ 2566809854 WinchOilPressSwitch 1857;
BA_ "SigType" SG_ 2566809854 HydOilFilterRestrictionSwitch 4;
BA_ "SPN" SG_ 2566809854 HydOilFilterRestrictionSwitch 1713;
BA_ "SigType" SG_ 2566809854 HydTemp 1;
BA_ "SPN" SG_ 2566809854 HydTemp 1638;
BA_ "SigType" SG_ 2566842622 Altitude 1;
BA_ "SPN" SG_ 2566842622 Altitude 580;
BA_ "SigType" SG_ 2566842622 Pitch 1;
BA_ "SPN" SG_ 2566842622 Pitch 583;
BA_ "SigType" SG_ 2566842622 NavigationBasedVehicleSpeed 1;
BA_ "SPN" SG_ 2566842622 NavigationBasedVehicleSpeed 517;
BA_ "SigType" SG_ 2566842622 CompassBearing 1;
BA_ "SPN" SG_ 2566842622 CompassBearing 165;
BA_ "SigType" SG_ 2566832638 HighResolutionTripDistance 1;
BA_ "SPN" SG_ 2566832638 HighResolutionTripDistance 918;
BA_ "SigType" SG_ 2566832638 HghRsolutionTotalVehicleDistance 1;
BA_ "SPN" SG_ 2566832638 HghRsolutionTotalVehicleDistance 917;
BA_ "SigType" SG_ 2565868030 LongitudinalAcceleration 1;
BA_ "SPN" SG_ 2565868030 LongitudinalAcceleration 1810;
BA_ "SigType" SG_ 2565868030 LateralAcceleration 1;
BA_ "SPN" SG_ 2565868030 LateralAcceleration 1809;
BA_ "SigType" SG_ 2565868030 YawRate 1;
BA_ "SPN" SG_ 2565868030 YawRate 1808;
BA_ "SigType" SG_ 2565868030 SteerWheelAngleSensorType 5;
BA_ "SPN" SG_ 2565868030 SteerWheelAngleSensorType 1812;
BA_ "SPN" SG_ 2565868030 SteerWheelTurnCounter 1811;
BA_ "SigType" SG_ 2565868030 SteerWheelAngle 1;
BA_ "SPN" SG_ 2565868030 SteerWheelAngle 1807;
BA_ "SigType" SG_ 2566803454 TrailerVDCActive 5;
BA_ "SPN" SG_ 2566803454 TrailerVDCActive 5624;
BA_ "SigType" SG_ 2566803454 YCBrakeCtrlActive 5;
BA_ "SPN" SG_ 2566803454 YCBrakeCtrlActive 1819;
BA_ "SigType" SG_ 2566803454 YCEngCtrlActive 5;
BA_ "SPN" SG_ 2566803454 YCEngCtrlActive 1817;
BA_ "SigType" SG_ 2566803454 ROPBrakeCtrlActive 5;
BA_ "SPN" SG_ 2566803454 ROPBrakeCtrlActive 1818;
BA_ "SigType" SG_ 2566803454 ROPEngCtrlActive 5;
BA_ "SPN" SG_ 2566803454 ROPEngCtrlActive 1816;
BA_ "SigType" SG_ 2566803454 VDCBrakeLightRq 5;
BA_ "SPN" SG_ 2566803454 VDCBrakeLightRq 1815;
BA_ "SigType" SG_ 2566803454 VDCFullyOperational 5;
BA_ "SPN" SG_ 2566803454 VDCFullyOperational 1814;
BA_ "SigType" SG_ 2566803454 VDCInformationSignal 5;
BA_ "SPN" SG_ 2566803454 VDCInformationSignal 1813;
BA_ "SigType" SG_ 2566840574 TotalVehicleDistance 1;
BA_ "SPN" SG_ 2566840574 TotalVehicleDistance 245;
BA_ "SigType" SG_ 2566840574 TripDistance 1;
BA_ "SPN" SG_ 2566840574 TripDistance 244;
BA_ "SigType" SG_ 2633938686 TripCruiseDistance 1;
BA_ "SPN" SG_ 2633938686 TripCruiseDistance 1019;
BA_ "SigType" SG_ 2633938686 TripMaxVehicleSpeed 1;
BA_ "SPN" SG_ 2633938686 TripMaxVehicleSpeed 1018;
BA_ "SigType" SG_ 2633937150 TripAirCompressorOnTime 1;
BA_ "SPN" SG_ 2633937150 TripAirCompressorOnTime 1038;
BA_ "SigType" SG_ 2633937150 TripIdleTime 1;
BA_ "SPN" SG_ 2633937150 TripIdleTime 1037;
BA_ "SigType" SG_ 2633937150 TripEngRunningTime 1;
BA_ "SPN" SG_ 2633937150 TripEngRunningTime 1036;
BA_ "SigType" SG_ 2633937150 TripCruiseTime 1;
BA_ "SPN" SG_ 2633937150 TripCruiseTime 1034;
BA_ "SigType" SG_ 2633937150 TripPTOGovernorTime 1;
BA_ "SPN" SG_ 2633937150 TripPTOGovernorTime 1035;
BA_ "SigType" SG_ 2633938174 TripTimeInDerateByEng 1;
BA_ "SPN" SG_ 2633938174 TripTimeInDerateByEng 1027;
BA_ "SigType" SG_ 2633938174 TripTimeInGearDown 1;
BA_ "SPN" SG_ 2633938174 TripTimeInGearDown 1026;
BA_ "SigType" SG_ 2633938174 TripTimeInTopGear 1;
BA_ "SPN" SG_ 2633938174 TripTimeInTopGear 1025;
BA_ "SigType" SG_ 2633938174 TripTimeInVSL 1;
BA_ "SPN" SG_ 2633938174 TripTimeInVSL 1024;
BA_ "SigType" SG_ 2633938430 TripSuddenDecelerations 1;
BA_ "SPN" SG_ 2633938430 TripSuddenDecelerations 1023;
BA_ "SigType" SG_ 2633938430 TrpNumberOfIdleShutdownOverrides 1;
BA_ "SPN" SG_ 2633938430 TrpNumberOfIdleShutdownOverrides 1022;
BA_ "SigType" SG_ 2633938430 TripNumberOfIdleShutdowns 1;
BA_ "SPN" SG_ 2633938430 TripNumberOfIdleShutdowns 1021;
BA_ "SigType" SG_ 2633938430 TripNumberOfHotShutdowns 1;
BA_ "SPN" SG_ 2633938430 TripNumberOfHotShutdowns 1020;
BA_ "SPN" SG_ 2348875518 MessageChecksum 4207;
BA_ "SPN" SG_ 2348875518 MessageCounter 4206;
BA_ "SPN" SG_ 2348875518 EngRequestedTorqueHighResolution 4191;
BA_ "SPN" SG_ 2348875518 TSC1CtrlPurpose 3350;
BA_ "SPN" SG_ 2348875518 TSC1TransRate 3349;
BA_ "SPN" SG_ 2348875518 EngRequestedTorque_TorqueLimit 518;
BA_ "SPN" SG_ 2348875518 EngRequestedSpeed_SpeedLimit 898;
BA_ "SPN" SG_ 2348875518 OverrideCtrlModePriority 897;
BA_ "SPN" SG_ 2348875518 EngRequestedSpeedCtrlConditions 696;
BA_ "SPN" SG_ 2348875518 EngOverrideCtrlMode 695;
BA_ "SigType" SG_ 2566766846 TransitRunStatus 5;
BA_ "SPN" SG_ 2566766846 TransitRunStatus 3046;
BA_ "SigType" SG_ 2566766846 VehicleUseStatus 5;
BA_ "SPN" SG_ 2566766846 VehicleUseStatus 3045;
BA_ "SigType" SG_ 2566766846 SilentAlarmStatus 5;
BA_ "SPN" SG_ 2566766846 SilentAlarmStatus 3044;
BA_ "SigType" SG_ 2566766846 PatronCount 1;
BA_ "SPN" SG_ 2566766846 PatronCount 3047;
BA_ "SPN" SG_ 2566766846 TypeOfPassengerCount 3043;
BA_ "SPN" SG_ 2566765310 FareboxAlarmIdentifier 3181;
BA_ "SigType" SG_ 2566765310 FareboxEmergencyStatus 4;
BA_ "SPN" SG_ 2566765310 FareboxEmergencyStatus 3179;
BA_ "SigType" SG_ 2566765566 TransferSold 1;
BA_ "SPN" SG_ 2566765566 TransferSold 3168;
BA_ "SPN" SG_ 2566765566 TransferType 3173;
BA_ "SPN" SG_ 2566765566 TypeOfService 3172;
BA_ "SPN" SG_ 2566765566 InitialFareAgency 3167;
BA_ "SPN" SG_ 2566765566 PassCategory 3166;
BA_ "SPN" SG_ 2566765566 FareValidity 3165;
BA_ "SPN" SG_ 2566765566 PaymentDetails 3177;
BA_ "SPN" SG_ 2566765566 TypeOfFare 3176;
BA_ "SPN" SG_ 2566765566 PassengerType 3171;
BA_ "SPN" SG_ 2566765566 TransactionType 3170;
BA_ "SPN" SG_ 2566765566 RouteNumber 3169;
BA_ "SigType" SG_ 2566765822 DriversFareboxSecurityCode 1;
BA_ "SPN" SG_ 2566765822 DriversFareboxSecurityCode 3164;
BA_ "SigType" SG_ 2566765822 AssignedBlock 1;
BA_ "SPN" SG_ 2566765822 AssignedBlock 3163;
BA_ "SigType" SG_ 2566765822 AssignedRun 1;
BA_ "SPN" SG_ 2566765822 AssignedRun 3162;
BA_ "SigType" SG_ 2566765822 AssignedRoute 1;
BA_ "SPN" SG_ 2566765822 AssignedRoute 3160;
BA_ "SigType" SG_ 2566765822 PatternNumber 1;
BA_ "SPN" SG_ 2566765822 PatternNumber 3161;
BA_ "SigType" SG_ 2566765822 TripNumber 1;
BA_ "SPN" SG_ 2566765822 TripNumber 3159;
BA_ "SPN" SG_ 2566765822 FarePresets 3175;
BA_ "SPN" SG_ 2566765822 TripDirection 3174;
BA_ "SPN" SG_ 2566765822 TripStatus 3180;
BA_ "SigType" SG_ 2566765822 FareboxServiceStatus 4;
BA_ "SPN" SG_ 2566765822 FareboxServiceStatus 3178;
BA_ "SigType" SG_ 2566766078 VehicleID 1;
BA_ "SPN" SG_ 2566766078 VehicleID 3085;
BA_ "SigType" SG_ 2566766078 StrobeActivationCtrlStatus 4;
BA_ "SPN" SG_ 2566766078 StrobeActivationCtrlStatus 3082;
BA_ "SigType" SG_ 2566766078 TransitDoorEnable 4;
BA_ "SPN" SG_ 2566766078 TransitDoorEnable 3083;
BA_ "SPN" SG_ 2566766078 PriorityOfRespSentByEmitter 3084;
BA_ "SigType" SG_ 2566766078 IntrsctnPrmptionRequest_Response 4;
BA_ "SPN" SG_ 2566766078 IntrsctnPrmptionRequest_Response 3079;
BA_ "SigType" SG_ 2566766078 TransitRouteIDUsage 4;
BA_ "SPN" SG_ 2566766078 TransitRouteIDUsage 3080;
BA_ "SigType" SG_ 2566766078 RangeCodeEnable 4;
BA_ "SPN" SG_ 2566766078 RangeCodeEnable 3081;
BA_ "SigType" SG_ 2566766590 NmbrOfBytsInThMlpstIdntification 1;
BA_ "SPN" SG_ 2566766590 NmbrOfBytsInThMlpstIdntification 3070;
BA_ "SigType" SG_ 2566766334 NmbrOfBytsInThTrnstAssgndBlckIdn 1;
BA_ "SPN" SG_ 2566766334 NmbrOfBytsInThTrnstAssgndBlckIdn 3073;
BA_ "SigType" SG_ 2566766334 NmbrOfBytsInThTrnstAssgndRnIdntt 1;
BA_ "SPN" SG_ 2566766334 NmbrOfBytsInThTrnstAssgndRnIdntt 3072;
BA_ "SigType" SG_ 2566766334 NmbrOfBytsInThTrnstAssgndRtIdntt 1;
BA_ "SPN" SG_ 2566766334 NmbrOfBytsInThTrnstAssgndRtIdntt 3071;
BA_ "SigType" SG_ 2566766334 Agency 1;
BA_ "SPN" SG_ 2566766334 Agency 3078;
BA_ "SigType" SG_ 2561605374 ReferenceTirePressSetting_33 1;
BA_ "SPN" SG_ 2561605374 ReferenceTirePressSetting_33 521833;
BA_ "SigType" SG_ 2561605374 ReferenceTirePressSetting_32 1;
BA_ "SPN" SG_ 2561605374 ReferenceTirePressSetting_32 521832;
BA_ "SigType" SG_ 2561605374 ReferenceTirePressSetting_31 1;
BA_ "SPN" SG_ 2561605374 ReferenceTirePressSetting_31 521831;
BA_ "SigType" SG_ 2561605374 ReferenceTirePressSetting_30 1;
BA_ "SPN" SG_ 2561605374 ReferenceTirePressSetting_30 521830;
BA_ "SigType" SG_ 2561605374 ReferenceTirePressSetting_23 1;
BA_ "SPN" SG_ 2561605374 ReferenceTirePressSetting_23 521823;
BA_ "SigType" SG_ 2561605374 ReferenceTirePressSetting_22 1;
BA_ "SPN" SG_ 2561605374 ReferenceTirePressSetting_22 521822;
BA_ "SigType" SG_ 2561605374 ReferenceTirePressSetting_21 1;
BA_ "SPN" SG_ 2561605374 ReferenceTirePressSetting_21 521821;
BA_ "SigType" SG_ 2561605374 ReferenceTirePressSetting_20 1;
BA_ "SPN" SG_ 2561605374 ReferenceTirePressSetting_20 521820;
BA_ "SigType" SG_ 2561605374 ReferenceTirePressSetting_13 1;
BA_ "SPN" SG_ 2561605374 ReferenceTirePressSetting_13 521813;
BA_ "SigType" SG_ 2561605374 ReferenceTirePressSetting_12 1;
BA_ "SPN" SG_ 2561605374 ReferenceTirePressSetting_12 521812;
BA_ "SigType" SG_ 2561605374 ReferenceTirePressSetting_11 1;
BA_ "SPN" SG_ 2561605374 ReferenceTirePressSetting_11 521811;
BA_ "SigType" SG_ 2561605374 ReferenceTirePressSetting_10 1;
BA_ "SPN" SG_ 2561605374 ReferenceTirePressSetting_10 521810;
BA_ "SigType" SG_ 2561605374 ReferenceTirePressSetting_01 1;
BA_ "SPN" SG_ 2561605374 ReferenceTirePressSetting_01 521801;
BA_ "SigType" SG_ 2561605374 ReferenceTirePressSetting_00 1;
BA_ "SPN" SG_ 2561605374 ReferenceTirePressSetting_00 521800;
BA_ "SigType" SG_ 2561605374 TireLocation 1;
BA_ "SPN" SG_ 2561605374 TireLocation 3190;
BA_ "SigType" SG_ 2566765054 ReferenceTirePress_33 1;
BA_ "SPN" SG_ 2566765054 ReferenceTirePress_33 521933;
BA_ "SigType" SG_ 2566765054 ReferenceTirePress_32 1;
BA_ "SPN" SG_ 2566765054 ReferenceTirePress_32 521932;
BA_ "SigType" SG_ 2566765054 ReferenceTirePress_31 1;
BA_ "SPN" SG_ 2566765054 ReferenceTirePress_31 521931;
BA_ "SigType" SG_ 2566765054 ReferenceTirePress_30 1;
BA_ "SPN" SG_ 2566765054 ReferenceTirePress_30 521930;
BA_ "SigType" SG_ 2566765054 ReferenceTirePress_23 1;
BA_ "SPN" SG_ 2566765054 ReferenceTirePress_23 521923;
BA_ "SigType" SG_ 2566765054 ReferenceTirePress_22 1;
BA_ "SPN" SG_ 2566765054 ReferenceTirePress_22 521922;
BA_ "SigType" SG_ 2566765054 ReferenceTirePress_21 1;
BA_ "SPN" SG_ 2566765054 ReferenceTirePress_21 521921;
BA_ "SigType" SG_ 2566765054 ReferenceTirePress_20 1;
BA_ "SPN" SG_ 2566765054 ReferenceTirePress_20 521920;
BA_ "SigType" SG_ 2566765054 ReferenceTirePress_13 1;
BA_ "SPN" SG_ 2566765054 ReferenceTirePress_13 521913;
BA_ "SigType" SG_ 2566765054 ReferenceTirePress_12 1;
BA_ "SPN" SG_ 2566765054 ReferenceTirePress_12 521912;
BA_ "SigType" SG_ 2566765054 ReferenceTirePress_11 1;
BA_ "SPN" SG_ 2566765054 ReferenceTirePress_11 521911;
BA_ "SigType" SG_ 2566765054 ReferenceTirePress_10 1;
BA_ "SPN" SG_ 2566765054 ReferenceTirePress_10 521910;
BA_ "SigType" SG_ 2566765054 ReferenceTirePress_01 1;
BA_ "SPN" SG_ 2566765054 ReferenceTirePress_01 521901;
BA_ "SigType" SG_ 2566765054 ReferenceTirePress_00 1;
BA_ "SPN" SG_ 2566765054 ReferenceTirePress_00 521900;
BA_ "SigType" SG_ 2566765054 TireLocation 1;
BA_ "SPN" SG_ 2566765054 TireLocation 3190;
BA_ "SigType" SG_ 2633923326 SteerChannelTirePress 1;
BA_ "SPN" SG_ 2633923326 SteerChannelTirePress 146;
BA_ "SigType" SG_ 2633923326 DriveChannelTirePress 1;
BA_ "SPN" SG_ 2633923326 DriveChannelTirePress 145;
BA_ "SigType" SG_ 2633923326 TrailerTagOrPushChannelTirePress 1;
BA_ "SPN" SG_ 2633923326 TrailerTagOrPushChannelTirePress 144;
BA_ "SigType" SG_ 2633923070 SteerChannelTirePressTarget 1;
BA_ "SPN" SG_ 2633923070 SteerChannelTirePressTarget 143;
BA_ "SigType" SG_ 2633923070 DriveChannelTirePressTarget 1;
BA_ "SPN" SG_ 2633923070 DriveChannelTirePressTarget 142;
BA_ "SigType" SG_ 2633923070 TrlrTgOrPshChnnelTirePressTarget 1;
BA_ "SPN" SG_ 2633923070 TrlrTgOrPshChnnelTirePressTarget 141;
BA_ "SigType" SG_ 2633922814 PCUTrilerTagOrPushSolenoidStatus 5;
BA_ "SPN" SG_ 2633922814 PCUTrilerTagOrPushSolenoidStatus 1475;
BA_ "SigType" SG_ 2633922814 PCUSupplySolenoidStatus 5;
BA_ "SPN" SG_ 2633922814 PCUSupplySolenoidStatus 1474;
BA_ "SigType" SG_ 2633922814 PCUCtrlSolenoidStatus 5;
BA_ "SPN" SG_ 2633922814 PCUCtrlSolenoidStatus 1473;
BA_ "SigType" SG_ 2633922814 PCUDeflateSolenoidStatus 5;
BA_ "SPN" SG_ 2633922814 PCUDeflateSolenoidStatus 1472;
BA_ "SigType" SG_ 2633922814 TirePressSupplySwitchStatus 5;
BA_ "SPN" SG_ 2633922814 TirePressSupplySwitchStatus 1471;
BA_ "SigType" SG_ 2633922814 PCUSteerSolenoidStatus 5;
BA_ "SPN" SG_ 2633922814 PCUSteerSolenoidStatus 1470;
BA_ "SigType" SG_ 2633922814 PCUDriveSolenoidStatus 5;
BA_ "SPN" SG_ 2633922814 PCUDriveSolenoidStatus 1469;
BA_ "SPN" SG_ 2633922814 DriveChannelMode 1468;
BA_ "SPN" SG_ 2633922814 Trailer_tagChannelMode 1467;
BA_ "SPN" SG_ 2633922814 SteerChannelMode 1466;
BA_ "SPN" SG_ 2633922814 TirePressCheckInterval 39;
BA_ "SPN" SG_ 2566845694 TirePressThresholdDetection_13 521613;
BA_ "SPN" SG_ 2566845694 TirePressThresholdDetection_12 521612;
BA_ "SPN" SG_ 2566845694 TirePressThresholdDetection_11 521611;
BA_ "SPN" SG_ 2566845694 TirePressThresholdDetection_10 521610;
BA_ "SPN" SG_ 2566845694 TirePressThresholdDetection_01 521601;
BA_ "SigType" SG_ 2566845694 TirePress_33 1;
BA_ "SPN" SG_ 2566845694 TirePress_33 521033;
BA_ "SigType" SG_ 2566845694 TirePress_32 1;
BA_ "SPN" SG_ 2566845694 TirePress_32 521032;
BA_ "SigType" SG_ 2566845694 TirePress_31 1;
BA_ "SPN" SG_ 2566845694 TirePress_31 521031;
BA_ "SigType" SG_ 2566845694 TirePress_30 1;
BA_ "SPN" SG_ 2566845694 TirePress_30 521030;
BA_ "SigType" SG_ 2566845694 TirePress_23 1;
BA_ "SPN" SG_ 2566845694 TirePress_23 521023;
BA_ "SigType" SG_ 2566845694 TirePress_22 1;
BA_ "SPN" SG_ 2566845694 TirePress_22 521022;
BA_ "SigType" SG_ 2566845694 TirePress_21 1;
BA_ "SPN" SG_ 2566845694 TirePress_21 521021;
BA_ "SigType" SG_ 2566845694 TirePress_20 1;
BA_ "SPN" SG_ 2566845694 TirePress_20 521020;
BA_ "SigType" SG_ 2566845694 TirePress_13 1;
BA_ "SPN" SG_ 2566845694 TirePress_13 521013;
BA_ "SigType" SG_ 2566845694 TirePress_12 1;
BA_ "SPN" SG_ 2566845694 TirePress_12 521012;
BA_ "SigType" SG_ 2566845694 TirePress_11 1;
BA_ "SPN" SG_ 2566845694 TirePress_11 521011;
BA_ "SigType" SG_ 2566845694 TirePress_10 1;
BA_ "SPN" SG_ 2566845694 TirePress_10 521010;
BA_ "SigType" SG_ 2566845694 TireAirLeakageRate_33 1;
BA_ "SPN" SG_ 2566845694 TireAirLeakageRate_33 521533;
BA_ "SigType" SG_ 2566845694 TireAirLeakageRate_32 1;
BA_ "SPN" SG_ 2566845694 TireAirLeakageRate_32 521532;
BA_ "SigType" SG_ 2566845694 TireAirLeakageRate_31 1;
BA_ "SPN" SG_ 2566845694 TireAirLeakageRate_31 521531;
BA_ "SigType" SG_ 2566845694 TireAirLeakageRate_30 1;
BA_ "SPN" SG_ 2566845694 TireAirLeakageRate_30 521530;
BA_ "SigType" SG_ 2566845694 TireAirLeakageRate_23 1;
BA_ "SPN" SG_ 2566845694 TireAirLeakageRate_23 521523;
BA_ "SigType" SG_ 2566845694 TireAirLeakageRate_22 1;
BA_ "SPN" SG_ 2566845694 TireAirLeakageRate_22 521522;
BA_ "SigType" SG_ 2566845694 TireAirLeakageRate_21 1;
BA_ "SPN" SG_ 2566845694 TireAirLeakageRate_21 521521;
BA_ "SigType" SG_ 2566845694 TireAirLeakageRate_20 1;
BA_ "SPN" SG_ 2566845694 TireAirLeakageRate_20 521520;
BA_ "SigType" SG_ 2566845694 TireAirLeakageRate_13 1;
BA_ "SPN" SG_ 2566845694 TireAirLeakageRate_13 521513;
BA_ "SigType" SG_ 2566845694 TireAirLeakageRate_12 1;
BA_ "SPN" SG_ 2566845694 TireAirLeakageRate_12 521512;
BA_ "SigType" SG_ 2566845694 TireAirLeakageRate_11 1;
BA_ "SPN" SG_ 2566845694 TireAirLeakageRate_11 521511;
BA_ "SigType" SG_ 2566845694 TireAirLeakageRate_10 1;
BA_ "SPN" SG_ 2566845694 TireAirLeakageRate_10 521510;
BA_ "SigType" SG_ 2566845694 TireAirLeakageRate_01 1;
BA_ "SPN" SG_ 2566845694 TireAirLeakageRate_01 521501;
BA_ "SigType" SG_ 2566845694 TireAirLeakageRate_00 1;
BA_ "SPN" SG_ 2566845694 TireAirLeakageRate_00 521500;
BA_ "SigType" SG_ 2566845694 CTIWheelSensorStatus_33 4;
BA_ "SPN" SG_ 2566845694 CTIWheelSensorStatus_33 521433;
BA_ "SigType" SG_ 2566845694 CTIWheelSensorStatus_32 4;
BA_ "SPN" SG_ 2566845694 CTIWheelSensorStatus_32 521432;
BA_ "SigType" SG_ 2566845694 CTIWheelSensorStatus_31 4;
BA_ "SPN" SG_ 2566845694 CTIWheelSensorStatus_31 521431;
BA_ "SigType" SG_ 2566845694 CTIWheelSensorStatus_30 4;
BA_ "SPN" SG_ 2566845694 CTIWheelSensorStatus_30 521430;
BA_ "SigType" SG_ 2566845694 CTIWheelSensorStatus_23 4;
BA_ "SPN" SG_ 2566845694 CTIWheelSensorStatus_23 521423;
BA_ "SigType" SG_ 2566845694 CTIWheelSensorStatus_22 4;
BA_ "SPN" SG_ 2566845694 CTIWheelSensorStatus_22 521422;
BA_ "SigType" SG_ 2566845694 CTIWheelSensorStatus_21 4;
BA_ "SPN" SG_ 2566845694 CTIWheelSensorStatus_21 521421;
BA_ "SigType" SG_ 2566845694 CTIWheelSensorStatus_20 4;
BA_ "SPN" SG_ 2566845694 CTIWheelSensorStatus_20 521420;
BA_ "SigType" SG_ 2566845694 CTIWheelSensorStatus_13 4;
BA_ "SPN" SG_ 2566845694 CTIWheelSensorStatus_13 521413;
BA_ "SigType" SG_ 2566845694 CTIWheelSensorStatus_12 4;
BA_ "SPN" SG_ 2566845694 CTIWheelSensorStatus_12 521412;
BA_ "SigType" SG_ 2566845694 CTIWheelSensorStatus_11 4;
BA_ "SPN" SG_ 2566845694 CTIWheelSensorStatus_11 521411;
BA_ "SigType" SG_ 2566845694 CTIWheelSensorStatus_10 4;
BA_ "SPN" SG_ 2566845694 CTIWheelSensorStatus_10 521410;
BA_ "SigType" SG_ 2566845694 CTIWheelSensorStatus_01 4;
BA_ "SPN" SG_ 2566845694 CTIWheelSensorStatus_01 521401;
BA_ "SigType" SG_ 2566845694 CTIWheelEndElectricalFault_33 4;
BA_ "SPN" SG_ 2566845694 CTIWheelEndElectricalFault_33 521233;
BA_ "SigType" SG_ 2566845694 CTIWheelEndElectricalFault_32 4;
BA_ "SPN" SG_ 2566845694 CTIWheelEndElectricalFault_32 521232;
BA_ "SigType" SG_ 2566845694 CTIWheelEndElectricalFault_31 4;
BA_ "SPN" SG_ 2566845694 CTIWheelEndElectricalFault_31 521231;
BA_ "SigType" SG_ 2566845694 CTIWheelEndElectricalFault_30 4;
BA_ "SPN" SG_ 2566845694 CTIWheelEndElectricalFault_30 521230;
BA_ "SigType" SG_ 2566845694 CTIWheelEndElectricalFault_23 4;
BA_ "SPN" SG_ 2566845694 CTIWheelEndElectricalFault_23 521223;
BA_ "SigType" SG_ 2566845694 CTIWheelEndElectricalFault_22 4;
BA_ "SPN" SG_ 2566845694 CTIWheelEndElectricalFault_22 521222;
BA_ "SigType" SG_ 2566845694 CTIWheelEndElectricalFault_21 4;
BA_ "SPN" SG_ 2566845694 CTIWheelEndElectricalFault_21 521221;
BA_ "SigType" SG_ 2566845694 CTIWheelEndElectricalFault_20 4;
BA_ "SPN" SG_ 2566845694 CTIWheelEndElectricalFault_20 521220;
BA_ "SigType" SG_ 2566845694 CTIWheelEndElectricalFault_13 4;
BA_ "SPN" SG_ 2566845694 CTIWheelEndElectricalFault_13 521213;
BA_ "SigType" SG_ 2566845694 CTIWheelEndElectricalFault_12 4;
BA_ "SPN" SG_ 2566845694 CTIWheelEndElectricalFault_12 521212;
BA_ "SigType" SG_ 2566845694 CTIWheelEndElectricalFault_11 4;
BA_ "SPN" SG_ 2566845694 CTIWheelEndElectricalFault_11 521211;
BA_ "SigType" SG_ 2566845694 CTIWheelEndElectricalFault_10 4;
BA_ "SPN" SG_ 2566845694 CTIWheelEndElectricalFault_10 521210;
BA_ "SigType" SG_ 2566845694 CTIWheelEndElectricalFault_01 4;
BA_ "SPN" SG_ 2566845694 CTIWheelEndElectricalFault_01 521201;
BA_ "SigType" SG_ 2566845694 CTITireStatus_33 4;
BA_ "SPN" SG_ 2566845694 CTITireStatus_33 521333;
BA_ "SigType" SG_ 2566845694 CTITireStatus_32 4;
BA_ "SPN" SG_ 2566845694 CTITireStatus_32 521332;
BA_ "SigType" SG_ 2566845694 CTITireStatus_31 4;
BA_ "SPN" SG_ 2566845694 CTITireStatus_31 521331;
BA_ "SigType" SG_ 2566845694 CTITireStatus_30 4;
BA_ "SPN" SG_ 2566845694 CTITireStatus_30 521330;
BA_ "SigType" SG_ 2566845694 CTITireStatus_23 4;
BA_ "SPN" SG_ 2566845694 CTITireStatus_23 521323;
BA_ "SigType" SG_ 2566845694 CTITireStatus_22 4;
BA_ "SPN" SG_ 2566845694 CTITireStatus_22 521322;
BA_ "SigType" SG_ 2566845694 CTITireStatus_21 4;
BA_ "SPN" SG_ 2566845694 CTITireStatus_21 521321;
BA_ "SigType" SG_ 2566845694 CTITireStatus_20 4;
BA_ "SPN" SG_ 2566845694 CTITireStatus_20 521320;
BA_ "SigType" SG_ 2566845694 CTITireStatus_13 4;
BA_ "SPN" SG_ 2566845694 CTITireStatus_13 521313;
BA_ "SigType" SG_ 2566845694 CTITireStatus_12 4;
BA_ "SPN" SG_ 2566845694 CTITireStatus_12 521312;
BA_ "SigType" SG_ 2566845694 CTITireStatus_11 4;
BA_ "SPN" SG_ 2566845694 CTITireStatus_11 521311;
BA_ "SigType" SG_ 2566845694 CTITireStatus_10 4;
BA_ "SPN" SG_ 2566845694 CTITireStatus_10 521310;
BA_ "SigType" SG_ 2566845694 CTITireStatus_01 4;
BA_ "SPN" SG_ 2566845694 CTITireStatus_01 521301;
BA_ "SigType" SG_ 2566845694 TireTemp_11 1;
BA_ "SPN" SG_ 2566845694 TireTemp_11 521111;
BA_ "SigType" SG_ 2566845694 TireTemp_33 1;
BA_ "SPN" SG_ 2566845694 TireTemp_33 521133;
BA_ "SigType" SG_ 2566845694 TireTemp_32 1;
BA_ "SPN" SG_ 2566845694 TireTemp_32 521132;
BA_ "SigType" SG_ 2566845694 TireTemp_31 1;
BA_ "SPN" SG_ 2566845694 TireTemp_31 521131;
BA_ "SigType" SG_ 2566845694 TireTemp_30 1;
BA_ "SPN" SG_ 2566845694 TireTemp_30 521130;
BA_ "SigType" SG_ 2566845694 TireTemp_23 1;
BA_ "SPN" SG_ 2566845694 TireTemp_23 521123;
BA_ "SigType" SG_ 2566845694 TireTemp_22 1;
BA_ "SPN" SG_ 2566845694 TireTemp_22 521122;
BA_ "SigType" SG_ 2566845694 TireTemp_21 1;
BA_ "SPN" SG_ 2566845694 TireTemp_21 521121;
BA_ "SigType" SG_ 2566845694 TireTemp_20 1;
BA_ "SPN" SG_ 2566845694 TireTemp_20 521120;
BA_ "SigType" SG_ 2566845694 TireTemp_13 1;
BA_ "SPN" SG_ 2566845694 TireTemp_13 521113;
BA_ "SigType" SG_ 2566845694 TireTemp_12 1;
BA_ "SPN" SG_ 2566845694 TireTemp_12 521112;
BA_ "SigType" SG_ 2566845694 TireTemp_10 1;
BA_ "SPN" SG_ 2566845694 TireTemp_10 521110;
BA_ "SigType" SG_ 2566845694 TireTemp_01 1;
BA_ "SPN" SG_ 2566845694 TireTemp_01 521101;
BA_ "SigType" SG_ 2566845694 TireTemp_00 1;
BA_ "SPN" SG_ 2566845694 TireTemp_00 521100;
BA_ "SPN" SG_ 2566845694 TirePressThresholdDetection_33 521633;
BA_ "SPN" SG_ 2566845694 TirePressThresholdDetection_32 521632;
BA_ "SPN" SG_ 2566845694 TirePressThresholdDetection_31 521631;
BA_ "SPN" SG_ 2566845694 TirePressThresholdDetection_30 521630;
BA_ "SPN" SG_ 2566845694 TirePressThresholdDetection_23 521623;
BA_ "SPN" SG_ 2566845694 TirePressThresholdDetection_22 521622;
BA_ "SPN" SG_ 2566845694 TirePressThresholdDetection_21 521621;
BA_ "SPN" SG_ 2566845694 TirePressThresholdDetection_20 521620;
BA_ "SPN" SG_ 2566845694 TirePressThresholdDetection_00 521600;
BA_ "SigType" SG_ 2566845694 TirePress_01 1;
BA_ "SPN" SG_ 2566845694 TirePress_01 521001;
BA_ "SigType" SG_ 2566845694 TirePress_00 1;
BA_ "SPN" SG_ 2566845694 TirePress_00 521000;
BA_ "SigType" SG_ 2566845694 CTIWheelSensorStatus_00 4;
BA_ "SPN" SG_ 2566845694 CTIWheelSensorStatus_00 521400;
BA_ "SigType" SG_ 2566845694 CTIWheelEndElectricalFault_00 4;
BA_ "SPN" SG_ 2566845694 CTIWheelEndElectricalFault_00 521200;
BA_ "SigType" SG_ 2566845694 CTITireStatus_00 4;
BA_ "SPN" SG_ 2566845694 CTITireStatus_00 521300;
BA_ "SigType" SG_ 2566845694 TireLocation 1;
BA_ "SPN" SG_ 2566845694 TireLocation 929;
BA_ "SigType" SG_ 2633939966 TripFanOnTimeDueToTheA_CSystem 1;
BA_ "SPN" SG_ 2633939966 TripFanOnTimeDueToTheA_CSystem 997;
BA_ "SigType" SG_ 2633939966 TripFanOnTimeDueToAManualSwitch 1;
BA_ "SPN" SG_ 2633939966 TripFanOnTimeDueToAManualSwitch 996;
BA_ "SigType" SG_ 2633939966 TripFanOnTimeDueToTheEngSystem 1;
BA_ "SPN" SG_ 2633939966 TripFanOnTimeDueToTheEngSystem 995;
BA_ "SigType" SG_ 2633939966 TripFanOnTime 1;
BA_ "SPN" SG_ 2633939966 TripFanOnTime 994;
BA_ "SigType" SG_ 2633939710 TripDistanceInTopGear 1;
BA_ "SPN" SG_ 2633939710 TripDistanceInTopGear 1000;
BA_ "SigType" SG_ 2633939710 TripGearDownDistance 1;
BA_ "SPN" SG_ 2633939710 TripGearDownDistance 999;
BA_ "SigType" SG_ 2633939710 TripDistanceOnVSL 1;
BA_ "SPN" SG_ 2633939710 TripDistanceOnVSL 998;
BA_ "SigType" SG_ 2564161278 AdjustLocalHourOffset 1;
BA_ "SPN" SG_ 2564161278 AdjustLocalHourOffset 1610;
BA_ "SigType" SG_ 2564161278 AdjustLocalMinuteOffset 1;
BA_ "SPN" SG_ 2564161278 AdjustLocalMinuteOffset 1609;
BA_ "SigType" SG_ 2564161278 AdjustYear 1;
BA_ "SPN" SG_ 2564161278 AdjustYear 1608;
BA_ "SigType" SG_ 2564161278 AdjustDay 1;
BA_ "SPN" SG_ 2564161278 AdjustDay 1607;
BA_ "SigType" SG_ 2564161278 AdjustMonth 1;
BA_ "SPN" SG_ 2564161278 AdjustMonth 1606;
BA_ "SigType" SG_ 2564161278 AdjustHours 1;
BA_ "SPN" SG_ 2564161278 AdjustHours 1605;
BA_ "SigType" SG_ 2564161278 AdjustMinutes 1;
BA_ "SPN" SG_ 2564161278 AdjustMinutes 1604;
BA_ "SigType" SG_ 2564161278 AdjustSeconds 1;
BA_ "SPN" SG_ 2564161278 AdjustSeconds 1603;
BA_ "SigType" SG_ 2566842110 LocalHourOffset 1;
BA_ "SPN" SG_ 2566842110 LocalHourOffset 1602;
BA_ "SigType" SG_ 2566842110 LocalMinuteOffset 1;
BA_ "SPN" SG_ 2566842110 LocalMinuteOffset 1601;
BA_ "SigType" SG_ 2566842110 Year 1;
BA_ "SPN" SG_ 2566842110 Year 964;
BA_ "SigType" SG_ 2566842110 Day 1;
BA_ "SPN" SG_ 2566842110 Day 962;
BA_ "SigType" SG_ 2566842110 Month 1;
BA_ "SPN" SG_ 2566842110 Month 963;
BA_ "SigType" SG_ 2566842110 Hours 1;
BA_ "SPN" SG_ 2566842110 Hours 961;
BA_ "SigType" SG_ 2566842110 Minutes 1;
BA_ "SPN" SG_ 2566842110 Minutes 960;
BA_ "SigType" SG_ 2566842110 Seconds 1;
BA_ "SPN" SG_ 2566842110 Seconds 959;
BA_ "SPN" SG_ 2566821630 EngDsrdTrboWastegateActuator2Pos 5373;
BA_ "SPN" SG_ 2566821630 EngTrbWstgateActuator1TempStatus 5372;
BA_ "SPN" SG_ 2566821630 EngTrbWstgtActtor1PreliminaryFMI 5371;
BA_ "SPN" SG_ 2566821630 EngDsrdTrboWastegateActuator1Pos 5370;
BA_ "SigType" SG_ 2566821630 EngTrbWstgteActuatorCtrlAirPress 1;
BA_ "SPN" SG_ 2566821630 EngTrbWstgteActuatorCtrlAirPress 1192;
BA_ "SigType" SG_ 2566821630 EngTurboWastegateActuator4Pos 1;
BA_ "SPN" SG_ 2566821630 EngTurboWastegateActuator4Pos 1191;
BA_ "SigType" SG_ 2566821630 EngTurboWastegateActuator3Pos 1;
BA_ "SPN" SG_ 2566821630 EngTurboWastegateActuator3Pos 1190;
BA_ "SigType" SG_ 2566821630 EngTurboWastegateActuator2Pos 1;
BA_ "SPN" SG_ 2566821630 EngTurboWastegateActuator2Pos 1189;
BA_ "SigType" SG_ 2566821630 EngTurboWastegateActuator1Pos 1;
BA_ "SPN" SG_ 2566821630 EngTurboWastegateActuator1Pos 1188;
BA_ "SigType" SG_ 2365484286 TachographVehicleSpeed 1;
BA_ "SPN" SG_ 2365484286 TachographVehicleSpeed 1624;
BA_ "SigType" SG_ 2365484286 TachographOutputShaftSpeed 1;
BA_ "SPN" SG_ 2365484286 TachographOutputShaftSpeed 1623;
BA_ "SigType" SG_ 2365484286 DirectionIndicator 4;
BA_ "SPN" SG_ 2365484286 DirectionIndicator 1619;
BA_ "SigType" SG_ 2365484286 TachographPerformance 5;
BA_ "SPN" SG_ 2365484286 TachographPerformance 1620;
BA_ "SigType" SG_ 2365484286 HandlingInformation 5;
BA_ "SPN" SG_ 2365484286 HandlingInformation 1621;
BA_ "SigType" SG_ 2365484286 SystemEvent 5;
BA_ "SPN" SG_ 2365484286 SystemEvent 1622;
BA_ "SigType" SG_ 2365484286 DriverCardDriver2 4;
BA_ "SPN" SG_ 2365484286 DriverCardDriver2 1616;
BA_ "SPN" SG_ 2365484286 Driver2TimeRelatedStates 1618;
BA_ "SigType" SG_ 2365484286 VehicleOverspeed 4;
BA_ "SPN" SG_ 2365484286 VehicleOverspeed 1614;
BA_ "SigType" SG_ 2365484286 DriverCardDriver1 4;
BA_ "SPN" SG_ 2365484286 DriverCardDriver1 1615;
BA_ "SPN" SG_ 2365484286 Driver1TimeRelatedStates 1617;
BA_ "SigType" SG_ 2365484286 VehicleMotion 4;
BA_ "SPN" SG_ 2365484286 VehicleMotion 1611;
BA_ "SPN" SG_ 2365484286 Driver2WorkingState 1613;
BA_ "SPN" SG_ 2365484286 Driver1WorkingState 1612;
VAL_ 2566834686 PneumaticControlLine 1 "Towing veh with pn ctrl line" 0 "Towing veh without pn ctrl line" ;
VAL_ 2566834686 ABSOffroadRequest 1 "ABS off-road switch on" 0 "ABS off-road switch off" ;
VAL_ 2566834686 TwoElCircuitsBrakeDemand 1 "Two el. circuit brake available" 0 "One el. circuit brake available" ;
VAL_ 2566834686 VehicleRetarderCtrlActive 1 "Active" 0 "Passive" ;
VAL_ 2550398718 SupplyLineBrakingRequest 1 "Supply line braking request" 0 "No supply line braking request" ;
VAL_ 2550398718 VDCActive 1 "Active" 0 "Passive, but installed" ;
VAL_ 2550398718 AutomTowedVehBreakActive 1 "Active" 0 "Passive" ;
VAL_ 2550398718 VehicleServiceBrakeActive 1 "Active" 0 "Passive" ;
VAL_ 2550398718 VehicleRetarderCtrlActive 1 "Active" 0 "Passive" ;
VAL_ 2550398718 VehicleABSActive 1 "Active" 0 "Passiv, but installed" ;
VAL_ 2566833406 SupplyLineBrakingRequest 1 "Supply line braking request" 0 "No supply line braking request" ;
VAL_ 2566833406 LoadingRampApproachAssist 1 "Assistance active" 0 "Assistance not active" ;
VAL_ 2566833406 SpringBrakeEngaged 1 "Vehicle spring brake is engaged" 0 "Vehicle spring brake is released" ;
VAL_ 2566833406 ElectrLoadPropFunc 1 "Vehicle with el. load proportion" 0 "Vehicle without el. load proport" ;
VAL_ 2566833406 SpringBrakeInstalled 1 "Vehicle with spring brakes" 0 "Vehicle without spring brakes" ;
VAL_ 2566833406 VehicleType 1 "Dolly axle" 0 "Towing or towed vehicle" ;
VAL_ 2566833406 ElecSupplyOfNonBrakingSys 1 "Supply switched on" 0 "Supply switched off" ;
VAL_ 2566833406 AmberWarningSignalReq 1 "Towed vehicle failure indicated" 0 "No towed vehicle failure indicat" ;
VAL_ 2566833406 RedWarningSignalRequest 1 "Towed vehicle failure indicated" 0 "No towed vehicle failure indicat" ;
VAL_ 2566833406 VehicleElectrSupplySuff 1 "Vehicle el. supply sufficient" 0 "Vehicle el. supply insufficient" ;
VAL_ 2566833406 AutomTowedVehBreakActive 1 "Active" 0 "Passive" ;
VAL_ 2566833406 VehicleServiceBrakeActive 1 "Active" 0 "Passive" ;
VAL_ 2566833406 VehicleRetarderCtrlActive 1 "Active" 0 "Passive" ;
VAL_ 2566833406 VehicleABSActive 1 "Active" 0 "Passiv, but installed" ;
VAL_ 2365507326 TyreWheelIdentTemp2 15 "Axle position 15" 14 "Axle position 14" 13 "Axle position 13" 12 "Axle position 12" 11 "Axle position 11" 10 "Axle position 10" 9 "Axle position 9" 8 "Axle position 8" 7 "Axle position 7" 6 "Axle position 6" 5 "Axle position 5" 4 "Axle position 4" 3 "Axle position 3" 2 "Axle position 2" 1 "Axle position 1" 0 "Axle position not identified" ;
VAL_ 2365507326 TyreWheelIdentTemp1 15 "Wheel position 15" 14 "Wheel position 14" 13 "Wheel position 13" 12 "Wheel position 12" 11 "Wheel position 11" 10 "Wheel position 10" 9 "Wheel position 9" 8 "Wheel position 8" 7 "Wheel position 7" 6 "Wheel position 6" 5 "Wheel position 5" 4 "Wheel position 4" 3 "Wheel position 3" 2 "Wheel position 2" 1 "Wheel position 1" 0 "Wheel position not identified" ;
VAL_ 2365507326 TyreWheelIdentPressure2 15 "Axle position 15" 14 "Axle position 14" 13 "Axle position 13" 12 "Axle position 12" 11 "Axle position 11" 10 "Axle position 10" 9 "Axle position 9" 8 "Axle position 8" 7 "Axle position 7" 6 "Axle position 6" 5 "Axle position 5" 4 "Axle position 4" 3 "Axle position 3" 2 "Axle position 2" 1 "Axle position 1" 0 "Axle position not identified" ;
VAL_ 2365507326 TyreWheelIdentPressure1 15 "Wheel position 15" 14 "Wheel position 14" 13 "Wheel position 13" 12 "Wheel position 12" 11 "Wheel position 11" 10 "Wheel position 10" 9 "Wheel position 9" 8 "Wheel position 8" 7 "Wheel position 7" 6 "Wheel position 6" 5 "Wheel position 5" 4 "Wheel position 4" 3 "Wheel position 3" 2 "Wheel position 2" 1 "Wheel position 1" 0 "Wheel position not identified" ;
VAL_ 2365507326 TyreWheelIdentLining2 15 "Axle position 15" 14 "Axle position 14" 13 "Axle position 13" 12 "Axle position 12" 11 "Axle position 11" 10 "Axle position 10" 9 "Axle position 9" 8 "Axle position 8" 7 "Axle position 7" 6 "Axle position 6" 5 "Axle position 5" 4 "Axle position 4" 3 "Axle position 3" 2 "Axle position 2" 1 "Axle position 1" 0 "Axle position not identified" ;
VAL_ 2365507326 TyreWheelIdentLining1 15 "Wheel position 15" 14 "Wheel position 14" 13 "Wheel position 13" 12 "Wheel position 12" 11 "Wheel position 11" 10 "Wheel position 10" 9 "Wheel position 9" 8 "Wheel position 8" 7 "Wheel position 7" 6 "Wheel position 6" 5 "Wheel position 5" 4 "Wheel position 4" 3 "Wheel position 3" 2 "Wheel position 2" 1 "Wheel position 1" 0 "Wheel position not identified" ;
VAL_ 2365507326 VehiclePneumSupplySuff 1 "Pneumatic supply sufficient" 0 "Pneumatic supply insufficient" ;
VAL_ 2365507326 BrakeTemperatureStatus 1 "Brake temperature normal" 0 "Brake temperature out of range" ;
VAL_ 2365507326 BrakeLiningSufficient 1 "Brake linings sufficient" 0 "Brake linings insufficient" ;
VAL_ 2365507326 TyrePressureSufficient 1 "Tyre pressure sufficient" 0 "Tyre pressure insufficient" ;
VAL_ 2565013246 ODDRequest 3 "Take no action" 1 "ODD on" 0 "ODD off" ;
VAL_ 2565013246 AntiTheftDeviceReq 3 "Take no action" 1 "Anti-theft device on" 0 "Anti-theft device off" ;
VAL_ 2565013246 VehicleType 1 "Dolly axle" 0 "Towing or towed vehicle" ;
VAL_ 2365480958 EngineTorqueMode 15 "Not available" 11 "Remote accelerator" 10 "Braking system" 9 "High speed governor" 8 "Torque limiting" 7 "ABS control" 6 "Transmission control" 5 "ASR control" 4 "Road speed governor" 3 "PTO governor" 2 "Cruise control" 1 "Accelerator pedal/operator selec" 0 "Low idle governor/no request (de" ;
VAL_ 2365480958 EngineRunning 1 "Engine running" 0 "Engine not running" ;
VAL_ 2365480958 EngineControlAllowed 1 "Engine control allowed" 0 "Engine control not allowed" ;
VAL_ 2566808062 ClutchIndptdPTOFeedback 1 "Engaged" 0 "Not engaged" ;
VAL_ 2566808062 AccelPedalLowIdleSwitch 1 "In low idle condition" 0 "Not in low idle condition" ;
VAL_ 2566808062 StarterActive 1 "Starter active" 0 "Starter not active" ;
VAL_ 2566808062 TorqueConvtOilTempWarning 2 "Warning" 1 "Prewarning" 0 "No warning" ;
VAL_ 2566808062 PTOControlAllowed 1 "PTO control allowed" 0 "PTO control not allowed" ;
VAL_ 2566808062 SecEngineMtdPTOFeedback 1 "Limits activated" 0 "Limits not activated" ;
VAL_ 2566808062 FirstEngineMtdPTOFeedback 1 "Limits activated" 0 "Limits not activated" ;
VAL_ 2566808062 SecClutchDptdPTOFeedback 1 "Engaged" 0 "Not engaged" ;
VAL_ 2566808062 FirstClutchDpdtPTOFeedback 1 "Engaged" 0 "Not engaged" ;
VAL_ 2566808574 FuelLevelWarning 1 "Fuel level warning on" 0 "Fuel level warning off" ;
VAL_ 2566808574 EngineOilPressureWarning 1 "Warning" 0 "No warning" ;
VAL_ 2566808574 EngineCoolantTempWarning 2 "Warning" 1 "Prewarning" 0 "No warning" ;
VAL_ 2564947710 VehicleType 1 "Dolly axle" 0 "Towing or towed vehicle" ;
VAL_ 2566834430 AntiTheftDeviceStatus 1 "Anti-theft device on" 0 "Anti-theft device off" ;
VAL_ 2566834430 ODDStatus 1 "ODD active" 0 "ODD inactive" ;
VAL_ 2566808318 SecEngineMtdPTOSwitch 1 "Switched on" 0 "Switched off" ;
VAL_ 2566808318 SecClutchDpdtPTOSwitch 1 "Switched on" 0 "Switched off" ;
VAL_ 2566808318 FirstClutchDpdtPTOSwitch 1 "Switched on" 0 "Switched off" ;
VAL_ 2566808318 OperatingPanelActive 1 "Operating panel active" 0 "Operating panel not active" ;
VAL_ 2566808318 RefusePackerStepSwitch 1 "Switched on" 0 "Switched off" ;
VAL_ 2566808318 EngineStopSwitch 1 "Switched on" 0 "Switched off" ;
VAL_ 2566808318 EngineStartSwitch 1 "Switched on" 0 "Switched off" ;
VAL_ 2566808318 StarterLockoutSwitch 1 "Switched on" 0 "Switched off" ;
VAL_ 2566808318 FirstEngineMtdPTOSwitch 1 "Switched on" 0 "Switched off" ;
VAL_ 2566808318 ClutchIndpdtPTOSwitch 1 "Switched on" 0 "Switched off" ;
VAL_ 2566808830 TrailerLeftSideMarkerLight 1 "Lamp(s) lit" 0 "Lamp(s) not lit" ;
VAL_ 2566808830 TrailerLeftReversingLight 1 "Lamp(s) lit" 0 "Lamp(s) not lit" ;
VAL_ 2566808830 TrailerLeftRearWidIndLight 1 "Lamp(s) lit" 0 "Lamp(s) not lit" ;
VAL_ 2566808830 TrailerLeftRearRegPltLight 1 "Lamp(s) lit" 0 "Lamp(s) not lit" ;
VAL_ 2566808830 TrailerLeftRearLight 1 "Lamp(s) lit" 0 "Lamp(s) not lit" ;
VAL_ 2566808830 TrailerLeftRearFogLight 1 "Lamp(s) lit" 0 "Lamp(s) not lit" ;
VAL_ 2566808830 TrailerLeftDirIndLight 1 "Lamp(s) lit" 0 "Lamp(s) not lit" ;
VAL_ 2566808830 TrailerLeftCrnMarkerLight 1 "Lamp(s) lit" 0 "Lamp(s) not lit" ;
VAL_ 2566808830 TrailerInteriorLight 1 "Lamp(s) lit" 0 "Lamp(s) not lit" ;
VAL_ 2566808830 TrailerWorkLamp 1 "Lamp(s) lit" 0 "Lamp(s) not lit" ;
VAL_ 2566808830 TrailerRotatingIdentLight 1 "Lamp(s) lit" 0 "Lamp(s) not lit" ;
VAL_ 2566808830 TrailerRightStopLight 1 "Lamp(s) lit" 0 "Lamp(s) not lit" ;
VAL_ 2566808830 TrailerRightSideMrkLight 1 "Lamp(s) lit" 0 "Lamp(s) not lit" ;
VAL_ 2566808830 TrailerRightReversingLight 1 "Lamp(s) lit" 0 "Lamp(s) not lit" ;
VAL_ 2566808830 TrailRightRearWidIndLight 1 "Lamp(s) lit" 0 "Lamp(s) not lit" ;
VAL_ 2566808830 TrailerRightRearRegPltLight 1 "Lamp(s) lit" 0 "Lamp(s) not lit" ;
VAL_ 2566808830 TrailerRightRearLight 1 "Lamp(s) lit" 0 "Lamp(s) not lit" ;
VAL_ 2566808830 TrailerRightRearFogLight 1 "Lamp(s) lit" 0 "Lamp(s) not lit" ;
VAL_ 2566808830 TrailerRightDirIndLight 1 "Lamp(s) lit" 0 "Lamp(s) not lit" ;
VAL_ 2566808830 TrailerRightCrnMarkerLight 1 "Lamp(s) lit" 0 "Lamp(s) not lit" ;
VAL_ 2566808830 TrailerRearWarningLight 1 "Lamp(s) lit" 0 "Lamp(s) not lit" ;
VAL_ 2566808830 TrailerLeftStopLight 1 "Lamp(s) lit" 0 "Lamp(s) not lit" ;
VAL_ 2564554494 FlowStatus 2 "Overflow" 1 "Wait " 0 "Continue To Send" ;
VAL_ 2564554494 ProtocolCtrlInformation 3 "Flow control " 2 "Consecutive frame" 1 "First frame" 0 "Single frame" ;
VAL_ 2564488958 FlowStatus 2 "Overflow" 1 "Wait " 0 "Continue To Send" ;
VAL_ 2564488958 ProtocolCtrlInformation 3 "Flow control " 2 "Consecutive frame" 1 "First frame" 0 "Single frame" ;
VAL_ 2565734142 ControlByte 6 "MFDB_CreateEntry" 5 "MFDB_SetMode" 4 "MFDB_Clear" 3 "MFDB_Delete" 2 "MFDB_Add" 1 "MFDB_Response" 0 "MFDB_Request" ;
VAL_ 2565734142 FilterMode 1 "PassSpecificPGNs" 0 "BlockSpecificPGNs" ;
VAL_ 2565144318 StopLevelChangeReq 3 "Take no action" 1 "Stop request" 0 "No stop request" ;
VAL_ 2565144318 RampLevelStorageReq 3 "Take no action" 1 "Store ramp level 2" 0 "Store ramp level 1" ;
VAL_ 2565144318 LevelControlReq 3 "Take no action" 1 "Enable level control" 0 "Disable level control" ;
VAL_ 2565144318 RampLevelReq 3 "Take no action" 1 "Ramp level 2" 0 "Ramp level 1" ;
VAL_ 2565144318 SteeringAxleLockingReq 3 "Take no action" 1 "Lock steering axle" 0 "Unlock steering axle" ;
VAL_ 2565144318 LiftAxle2PositionReq 3 "Take no action" 1 "Position up / tag axle unladen" 0 "Position down / tag axle laden" ;
VAL_ 2565144318 LiftAxle1PositionReq 3 "Don't care/take no action" 2 "Reserved" 1 "Position up / tag axle unladen" 0 "Position down / tag axle laden" ;
VAL_ 2565144318 TractionHelpReq 3 "Take no action" 1 "Traction help request" 0 "No traction help request" ;
VAL_ 2565144318 LevelChangeReqRearAxle 2 "Take no action" 1 "Vehicle body down (lowering)" 0 "Vehicle body up (lifting)" ;
VAL_ 2565144318 LevelChangeReqFrontAxle 2 "Take no action" 1 "Vehicle body down (lowering)" 0 "Vehicle body up (lifting)" ;
VAL_ 2565144318 RideHeightRequest 2 "Take no action" 1 "Normal level 2" 0 "Normal level 1" ;
VAL_ 2565209854 LevelControl 1 "Level control enabled" 0 "Level control disabled" ;
VAL_ 2565209854 RampLevel 1 "Body at requested ramp level" 0 "Body not at requested ramp level" ;
VAL_ 2565209854 NormalLevel 3 "Not available" 1 "Normal level 2" 0 "Normal level 1" ;
VAL_ 2565209854 StopLevelChangeAcknowledge 1 "Level change stopped" 0 "No stop request" ;
VAL_ 2565209854 LevelChangeRearAxle 1 "Body lifting/lowering active" 0 "Body lifting/lowering not active" ;
VAL_ 2565209854 LevelChangeFrontAxle 1 "Body lifting/lowering active" 0 "Body lifting/lowering not active" ;
VAL_ 2565209854 RampLevelStorage 1 "New ramp level stored" 0 "No new storage request" ;
VAL_ 2565209854 SteeringAxleLocking 1 "Steering axle locked" 0 "Steering axle unlocked" ;
VAL_ 2565209854 LiftAxle2Pos 3 "Not available" 2 "Error" 1 "Lift axle position up / tag axle unladen" 0 "Lift axle position down / tag axle laden" ;
VAL_ 2565209854 LiftAxle1Pos 3 "Not available" 2 "Error" 1 "Lift axle position up / tag axle unladen" 0 "Lift axle position down / tag axle laden" ;
VAL_ 2565209854 RampLevelPosition 3 "Not available" 1 "Ramp level 2" 0 "Ramp level 1" ;
VAL_ 2565209854 TractionHelp 1 "Traction help active" 0 "Traction help inactive" ;
VAL_ 2565209854 LevelCtrlSysRideHeightLevel 1 "Vehicle body at requested level" 0 "Vehicle body not at req. level" ;
VAL_ 2566807294 TyrePressThresholdDetect 7 "Not available" 6 "Error indicator" 5 "Not defined" 4 "Extreme under pressure" 3 "Under pressure" 2 "No warning pressure" 1 "Over pressure" 0 "Extreme over pressure" ;
VAL_ 2566807294 TyreModulePowerSupply 1 "Sufficient power supply" 0 "Insufficient power supply" ;
VAL_ 2566807294 TyreWheelIdentification2 15 "Axle position 15" 14 "Axle position 14" 13 "Axle position 13" 12 "Axle position 12" 11 "Axle position 11" 10 "Axle position 10" 9 "Axle position 9" 8 "Axle position 8" 7 "Axle position 7" 6 "Axle position 6" 5 "Axle position 5" 4 "Axle position 4" 3 "Axle position 3" 2 "Axle position 2" 1 "Axle position 1" 0 "Axle position not identified" ;
VAL_ 2566807294 TyreWheelIdentification1 15 "Wheel position 15" 14 "Wheel position 14" 13 "Wheel position 13" 12 "Wheel position 12" 11 "Wheel position 11" 10 "Wheel position 10" 9 "Wheel position 9" 8 "Wheel position 8" 7 "Wheel position 7" 6 "Wheel position 6" 5 "Wheel position 5" 4 "Wheel position 4" 3 "Wheel position 3" 2 "Wheel position 2" 1 "Wheel position 1" 0 "Wheel position not identified" ;
VAL_ 2566764798 MisfireMonitoringComplete 1 "EnabledForCycle" 0 "DisabledForRestOfCycle" ;
VAL_ 2566764798 MisfireMonitoringEnabled 1 "EnabledForCycle" 0 "DisabledForRestOfCycle" ;
VAL_ 2566764798 FuelSystemMonitoringEnabled 1 "NotCompleteCycle" 0 "CompleteCycleOrNotSupported" ;
VAL_ 2566764798 ComprehensiveComptMonComplete 1 "NotCompleteCycle" 0 "CompleteCycleOrNotSupported" ;
VAL_ 2566764798 ComprehensiveCompMonEnabled 1 "NotCompleteCycle" 0 "CompleteCycleOrNotSupported" ;
VAL_ 2566764798 SecondAirSystemMonComplete 1 "EnabledForCycle" 0 "DisabledForRestOfCycle" ;
VAL_ 2566764798 SecondAirSystemMonEnabled 1 "EnabledForCycle" 0 "DisabledForRestOfCycle" ;
VAL_ 2566764798 OxygenSensorMonComplete 1 "EnabledForCycle" 0 "DisabledForRestOfCycle" ;
VAL_ 2566764798 OxygenSensorMonEnabled 1 "NotCompleteCycle" 0 "CompleteCycleOrNotSupported" ;
VAL_ 2566764798 OxygenSensorHeaterMonComplete 1 "EnabledForCycle" 0 "DisabledForRestOfCycle" ;
VAL_ 2566764798 OxygenSensorHeaterMonEnabled 1 "NotCompleteCycle" 0 "CompleteCycleOrNotSupported" ;
VAL_ 2566764798 HeatedCatalystMonComplete 1 "EnabledForCycle" 0 "DisabledForRestOfCycle" ;
VAL_ 2566764798 HeatedCatalystMonEnabled 1 "EnabledForCycle" 0 "DisabledForRestOfCycle" ;
VAL_ 2566764798 EvaporativeSystemMonComplete 1 "NotCompleteCycle" 0 "CompleteCycleOrNotSupported" ;
VAL_ 2566764798 EvaporativeSystemMonEnabled 1 "NotCompleteCycle" 0 "CompleteCycleOrNotSupported" ;
VAL_ 2566764798 EGRSystemMonitoringComplete 1 "NotCompleteCycle" 0 "CompleteCycleOrNotSupported" ;
VAL_ 2566764798 EGRSystemMonitoringEnabled 1 "EnabledForCycle" 0 "DisabledForRestOfCycle" ;
VAL_ 2566764798 ColdStartAidSystemMonComplete 1 "EnabledForCycle" 0 "DisabledForRestOfCycle" ;
VAL_ 2566764798 ColdStartAidSystemMonEnabled 1 "EnabledForCycle" 0 "DisabledForRestOfCycle" ;
VAL_ 2566764798 CatalystMonComplete 1 "NotCompleteCycle" 0 "CompleteCycleOrNotSupported" ;
VAL_ 2566764798 CatalystMonEnabled 1 "NotCompleteCycle" 0 "CompleteCycleOrNotSupported" ;
VAL_ 2566764798 ACSystemRefrigerantMonComplete 1 "NotCompleteCycle" 0 "CompleteCycleOrNotSupported" ;
VAL_ 2566764798 ACSystemRefrigerantMonEnabled 1 "NotCompleteCycle" 0 "CompleteCycleOrNotSupported" ;
VAL_ 2566764798 FuelSystemMonitoringComplete 1 "NotCompleteCycle" 0 "CompleteCycleOrNotSupported" ;
VAL_ 2564095742 SecurityEntityType 3 "Data is Certificate" 2 "Data is Session Key" 1 "Data is Long Key" 0 "Data is Long Seed" ;
VAL_ 2349137662 XBRCtrlMode 3 "Not defined" 2 "Acceleration control with maximum mode  Execute the XBR acceleration demand if it is higher than the drivers" 1 "Acceleration control with addition mode  Add the XBR acceleration demand to the drivers acceleration demand" 0 "Override disabled  Disable any existing control commanded by the source of this command" ;
VAL_ 2349137662 XBRPriority 3 "Low priority  used in override disabled XBR Control Mode" 2 "Medium priority  used for ACCSystems This mode does not override brake protection measures of the brake" 1 "High priority  not defined" 0 "Highest priority  used for emergency situations eg for future Collision Avoidance System This mode overrides" ;
VAL_ 2349137662 XBREBIMode 3 "Not defined" 2 "Endurance Brake Integration allowed" 1 "Only Endurance Brakes allowed" 0 "No Endurance Brake Integration allowed" ;
VAL_ 2566848510 EmssnCtrlSystmOprtrIndcmntSvrity 7 "Not Available / Not Supported" 6 "Temporary Override of Inducement" 5 "Inducement Level 5  Euro VI defined Severe Inducement Active  FMI 0" 4 "Inducement Level 4  Euro VI defined Severe Inducement Enabled  FMI 16" 3 "Inducement Level 3  Euro VI defined LowLevel Inducement Active  FMI 16" 2 "Inducement Level 2  Euro VI defined LowLevel Inducement Enabled  FMI 15" 1 "Inducement Level 1 Euro VI defined Driver Warning System Active  FMI 15" 0 "Driver Warning LowLevel Inducement and Severe Inducement NonActive" ;
VAL_ 2566848510 DrvrWarningSystemIndicatorStatus 7 "not available" 6 "reserved for SAE assignment" 5 "reserved for SAE assignment" 4 "On  fast blink 1 Hz  Used for the second driver warning system detection threshold for diesel exhaust fluid level" 3 "reserved for SAE assignment" 2 "reserved for SAE assignment" 1 "On  solid  Used when driver warning system is activated for any relevant malfunction" 0 "Off  Used when driver warning system is nonactive  which by requirement means the lowlevel and severe" ;
VAL_ 2566848510 OperatorShiftPrompt 3 "dont care/take no action" 2 "downshift indicator active" 1 "upshift indicator active" 0 "indicators inactive" ;
VAL_ 2566848510 WaterInFuelIndicator 3 "Not available" 2 "Error" 1 "Yes" 0 "No" ;
VAL_ 2566843134 AxleLocation 48 "Axle3_Position0" 32 "Axle2_Position0" 16 "Axle1_Position0" 0 "Axle0_Position0" ;
VAL_ 2566809854 WinchOilPressSwitch 3 "Not Available" 2 "Error  Switch state cannot be determined" 1 "OK  Oil pressure is above minimum" 0 "NOT OK Oil pressure is too low" ;
VAL_ 2566809854 HydOilFilterRestrictionSwitch 3 "Not Available" 2 "Error" 1 "Restriction exists on oil filter" 0 "No restriction" ;
VAL_ 2565868030 SteerWheelAngleSensorType 3 "Not Available" 2 "Reserved" 1 "Absolute measuring principle" 0 "Relative measuring principle" ;
VAL_ 2566803454 TrailerVDCActive 3 "Not availble or not installed" 2 "Reserved" 1 "VDC active" 0 "VDC passive but installed" ;
VAL_ 2566803454 YCBrakeCtrlActive 3 "Dont care/Take no action" 2 "Reserved" 1 "YC brake control active" 0 "YC brake control passive but installed" ;
VAL_ 2566803454 YCEngCtrlActive 3 "Dont care/Take no action" 2 "Reserved" 1 "YC engine control active" 0 "YC engine control passive but installed" ;
VAL_ 2566803454 ROPBrakeCtrlActive 3 "Dont care/Take no action" 2 "Reserved" 1 "ROP brake control active" 0 "ROP brake control passive but installed" ;
VAL_ 2566803454 ROPEngCtrlActive 3 "Dont care/Take no action" 2 "Reserved" 1 "ROP engine control active" 0 "ROP engine control passive but installed" ;
VAL_ 2566803454 VDCBrakeLightRq 3 "Dont care/Take no action" 2 "Reserved" 1 "Turn brake light on" 0 "Turn brake light not on" ;
VAL_ 2566803454 VDCFullyOperational 3 "Dont care/Take no action" 2 "Reserved" 1 "Fully operational" 0 "Not fully operational" ;
VAL_ 2566803454 VDCInformationSignal 3 "Dont care/Take no action" 2 "Reserved" 1 "On" 0 "Off" ;
VAL_ 2348875518 EngRequestedTorqueHighResolution 7 "0875" 1 "0125" 0 "0000" 8 "1111  not available" ;
VAL_ 2348875518 TSC1CtrlPurpose 31 "P32  Temporary Power Train Control Original use of TSC1 Command" 5 "11110  P6P31  Reserved for SAE Assignment" 4 "P5  Engine Protection" 3 "P4  Road Speed Governor" 2 "P3  PTO Governor" 1 "P2  Cruise Control" 0 "P1  Accelerator Pedal/Operator Selection" ;
VAL_ 2348875518 TSC1TransRate 7 "Use standard TSC1 transmission rates of 10 ms to engine" 6 "20 ms transmission rate" 5 "50 ms transmission rate" 4 "100 ms transmission rate" 3 "250 ms transmission rate" 2 "500 ms transmission rate" 1 "750 ms transmission rate" 0 "1000 ms transmission rate" ;
VAL_ 2348875518 OverrideCtrlModePriority 3 "Low priority" 2 "Medium priority" 1 "High priority" 0 "Highest priority" ;
VAL_ 2348875518 EngRequestedSpeedCtrlConditions 2 "Stability Optimized for driveline engaged and/or in lockup condition 1 eg vehicle driveline" 3 "Stability Optimized for driveline engaged and/or in lockup condition 2 eg PTO driveline" 1 "Stability Optimized for driveline disengaged and nonlockup conditions" 0 "Transient Optimized for driveline disengaged and nonlockup conditions" ;
VAL_ 2348875518 EngOverrideCtrlMode 3 "Speed/torque limit control  Limit speed and/or torque based on the included limit values  The speed limit governor is" 2 "Torque control  Control torque to the included desired torque value" 1 "Speed control  Govern speed to the included desired speed value" 0 "Override disabled  Disable any existing control commanded by the source of this command" ;
VAL_ 2566766846 TransitRunStatus 3 "Not available" 2 "Error condition" 0 "Off" ;
VAL_ 2566766846 VehicleUseStatus 3 "Not available" 2 "Error condition" 1 "Unauthorized use" 0 "Normal use" ;
VAL_ 2566766846 SilentAlarmStatus 3 "Not available" 2 "Error condition" 1 "On" 0 "Off" ;
VAL_ 2566765310 FareboxAlarmIdentifier 25 "Maintenance access out of service" 24 "Maintenance access in service considered an alarm condition" 23 "Paper currency jam cleared" 22 "Paper currency jam" 21 "Pass/transfer jam cleared" 20 "Pass/transfer jam" 19 "Farebox reset to automatic mode" 18 "Farebox set in manual bypass" 17 "Coin dejam operated" 16 "Card/pass box full" 15 "Card/pass box less than 75 full" 14 "Card/pass box 75 full" 13 "Currency box full" 12 "Currency box less than 75 full" 11 "Currency box 75 full" 10 "Coinbox full" 9 "Coinbox 75 full" 8 "Insufficient fare accepted" 7 "Cashbox opened in service considered an alarm condition" 6 "Cashbox door timeout" 5 "Cashbox restored" 4 "Cashbox removed" 3 "Probe completed" 2 "Probe started" 1 "Voltage restored" 0 "Voltage dropout" ;
VAL_ 2566765310 FareboxEmergencyStatus 3 "Not available" 2 "Error Condition" 1 "Emergency condition" 0 "Nonemergency condition" ;
VAL_ 2566765566 TransferType 5 "Out" 4 "In" 3 "West" 2 "East" 1 "South" 0 "North" ;
VAL_ 2566765566 TypeOfService 1 "Express service" 0 "Local service" ;
VAL_ 2566765566 PaymentDetails 5 "Card" 4 "Pass" 3 "Ticket" 2 "Token" 1 "Cash" 0 "Not an upgrade" ;
VAL_ 2566765566 TypeOfFare 6 "Pass B" 5 "Pass A" 4 "Ticket B" 3 "Ticket A" 2 "Token B" 1 "Token A" 0 "Cash/No detail" ;
VAL_ 2566765566 TransactionType 7 "Free" 6 "Transfer" 5 "Permit" 4 "Card" 3 "Pass" 2 "Ticket" 1 "Token" 0 "Cash" ;
VAL_ 2566765822 FarePresets 16 "to 11111111  Reserved for assignment" 0 "to 00001111  Agency defined" ;
VAL_ 2566765822 TripDirection 5 "Out" 4 "In" 3 "West" 2 "East" 1 "South" 0 "North" ;
VAL_ 2566765822 TripStatus 4 "Undefined" 3 "Undefined" 0 "Undefined" 6 "Layover end" 5 "Layover start" 2 "Trip end" 1 "Trip start" 7 "Undefined" ;
VAL_ 2566765822 FareboxServiceStatus 3 "Not available" 2 "Error Condition" 1 "Farebox in service" 0 "Farebox out of service" ;
VAL_ 2566766078 StrobeActivationCtrlStatus 3 "Not available" 2 "Error condition" 1 "Activate strobe" 0 "Deactivate strobe" ;
VAL_ 2566766078 TransitDoorEnable 3 "Not available" 2 "Error condition" 1 "Transit door status will override strobe activation" 0 "Ignore transit door status" ;
VAL_ 2566766078 PriorityOfRespSentByEmitter 15 "Not available" 14 "Error condition" 12 "to 1101  Reserved" 11 "Priority set by hardware to high priority" 10 "Priority set by hardware to probe priority" 9 "Priority set by hardware to low priority" 4 "to 1000  Reserved" 3 "High priority" 2 "Probe priority" 1 "Low priority" 0 "Reserved" ;
VAL_ 2566766078 IntrsctnPrmptionRequest_Response 3 "Not available" 2 "Error condition" 1 "Message is a response from the emitter" 0 "Message is a request directed to the emitter" ;
VAL_ 2566766078 TransitRouteIDUsage 3 "Not available" 2 "Error condition" 1 "Transit route ID used for interleaved data if range code not enabled" 0 "Transit route ID not used for interleaved data" ;
VAL_ 2566766078 RangeCodeEnable 3 "Not available" 2 "Error condition" 1 "Range code used for interleaved data" 0 "Range code not used for interleaved data" ;
VAL_ 2561605374 TireLocation 51 "Axle3_Position3" 50 "Axle3_Position2" 49 "Axle3_Position1" 35 "Axle2_Position3" 34 "Axle2_Position2" 33 "Axle2_Position1" 19 "Axle1_Position3" 18 "Axle1_Position2" 17 "Axle1_Position1" 1 "Axle0_Position1" 48 "Axle3_Position0" 32 "Axle2_Position0" 16 "Axle1_Position0" 0 "Axle0_Position0" ;
VAL_ 2566765054 TireLocation 51 "Axle3_Position3" 50 "Axle3_Position2" 49 "Axle3_Position1" 35 "Axle2_Position3" 34 "Axle2_Position2" 33 "Axle2_Position1" 19 "Axle1_Position3" 18 "Axle1_Position2" 17 "Axle1_Position1" 1 "Axle0_Position1" 48 "Axle3_Position0" 32 "Axle2_Position0" 16 "Axle1_Position0" 0 "Axle0_Position0" ;
VAL_ 2633922814 PCUTrilerTagOrPushSolenoidStatus 3 "Not available" 2 "Error" 1 "On" 0 "Off" ;
VAL_ 2633922814 PCUSupplySolenoidStatus 3 "Not available" 2 "Error" 1 "On" 0 "Off" ;
VAL_ 2633922814 PCUCtrlSolenoidStatus 3 "Not available" 2 "Error" 1 "On" 0 "Off" ;
VAL_ 2633922814 PCUDeflateSolenoidStatus 3 "Not available" 2 "Error" 1 "On" 0 "Off" ;
VAL_ 2633922814 TirePressSupplySwitchStatus 3 "Not available" 2 "Error" 1 "On" 0 "Off" ;
VAL_ 2633922814 PCUSteerSolenoidStatus 3 "Not available" 2 "Error" 1 "On" 0 "Off" ;
VAL_ 2633922814 PCUDriveSolenoidStatus 3 "Not available" 2 "Error" 1 "On" 0 "Off" ;
VAL_ 2633922814 DriveChannelMode 15 "Not available" 14 "Error Condition" 6 "Pressure Check" 5 "Deflate Wait  System will deflate when conditions allow" 4 "Inflate Wait  System will inflate when conditions allow" 3 "Confirm" 2 "Deflate" 1 "Inflate" 0 "Maintain" ;
VAL_ 2633922814 Trailer_tagChannelMode 15 "Not available" 14 "Error Condition" 6 "Pressure Check" 5 "Deflate Wait  System will deflate when conditions allow" 4 "Inflate Wait  System will inflate when conditions allow" 3 "Confirm" 2 "Deflate" 1 "Inflate" 0 "Maintain" ;
VAL_ 2633922814 SteerChannelMode 15 "Not available" 14 "Error Condition" 6 "Pressure Check" 5 "Deflate Wait  System will deflate when conditions allow" 4 "Inflate Wait  System will inflate when conditions allow" 3 "Confirm" 2 "Deflate" 1 "Inflate" 0 "Maintain" ;
VAL_ 2566845694 TirePressThresholdDetection_13 7 "NotAvailable" 6 "ErrorIndicator" 5 "NotDefined" 4 "ExtrmUndrPrssTrPrssrIsAtALvlWhr" 3 "UndrPrssTrPrssrIsLwrThnThPrssrD" 2 "NWrnngPrssTrPrssrIsWthnThThrshl" 1 "OvrPrssTrPrssrIsHghrThnThPrssrD" 0 "ExtrmOvrPrssTrPrssrIsAtALvlWhrT" ;
VAL_ 2566845694 TirePressThresholdDetection_12 7 "NotAvailable" 6 "ErrorIndicator" 5 "NotDefined" 4 "ExtrmUndrPrssTrPrssrIsAtALvlWhr" 3 "UndrPrssTrPrssrIsLwrThnThPrssrD" 2 "NWrnngPrssTrPrssrIsWthnThThrshl" 1 "OvrPrssTrPrssrIsHghrThnThPrssrD" 0 "ExtrmOvrPrssTrPrssrIsAtALvlWhrT" ;
VAL_ 2566845694 TirePressThresholdDetection_11 7 "NotAvailable" 6 "ErrorIndicator" 5 "NotDefined" 4 "ExtrmUndrPrssTrPrssrIsAtALvlWhr" 3 "UndrPrssTrPrssrIsLwrThnThPrssrD" 2 "NWrnngPrssTrPrssrIsWthnThThrshl" 1 "OvrPrssTrPrssrIsHghrThnThPrssrD" 0 "ExtrmOvrPrssTrPrssrIsAtALvlWhrT" ;
VAL_ 2566845694 TirePressThresholdDetection_10 7 "NotAvailable" 6 "ErrorIndicator" 5 "NotDefined" 4 "ExtrmUndrPrssTrPrssrIsAtALvlWhr" 3 "UndrPrssTrPrssrIsLwrThnThPrssrD" 2 "NWrnngPrssTrPrssrIsWthnThThrshl" 1 "OvrPrssTrPrssrIsHghrThnThPrssrD" 0 "ExtrmOvrPrssTrPrssrIsAtALvlWhrT" ;
VAL_ 2566845694 TirePressThresholdDetection_01 7 "NotAvailable" 6 "ErrorIndicator" 5 "NotDefined" 4 "ExtrmUndrPrssTrPrssrIsAtALvlWhr" 3 "UndrPrssTrPrssrIsLwrThnThPrssrD" 2 "NWrnngPrssTrPrssrIsWthnThThrshl" 1 "OvrPrssTrPrssrIsHghrThnThPrssrD" 0 "ExtrmOvrPrssTrPrssrIsAtALvlWhrT" ;
VAL_ 2566845694 CTIWheelSensorStatus_33 3 "NotSupported" 2 "NotDefined" 1 "On" 0 "Off_IsolatedFromCTIPressCtrl" ;
VAL_ 2566845694 CTIWheelSensorStatus_32 3 "NotSupported" 2 "NotDefined" 1 "On" 0 "Off_IsolatedFromCTIPressCtrl" ;
VAL_ 2566845694 CTIWheelSensorStatus_31 3 "NotSupported" 2 "NotDefined" 1 "On" 0 "Off_IsolatedFromCTIPressCtrl" ;
VAL_ 2566845694 CTIWheelSensorStatus_30 3 "NotSupported" 2 "NotDefined" 1 "On" 0 "Off_IsolatedFromCTIPressCtrl" ;
VAL_ 2566845694 CTIWheelSensorStatus_23 3 "NotSupported" 2 "NotDefined" 1 "On" 0 "Off_IsolatedFromCTIPressCtrl" ;
VAL_ 2566845694 CTIWheelSensorStatus_22 3 "NotSupported" 2 "NotDefined" 1 "On" 0 "Off_IsolatedFromCTIPressCtrl" ;
VAL_ 2566845694 CTIWheelSensorStatus_21 3 "NotSupported" 2 "NotDefined" 1 "On" 0 "Off_IsolatedFromCTIPressCtrl" ;
VAL_ 2566845694 CTIWheelSensorStatus_20 3 "NotSupported" 2 "NotDefined" 1 "On" 0 "Off_IsolatedFromCTIPressCtrl" ;
VAL_ 2566845694 CTIWheelSensorStatus_13 3 "NotSupported" 2 "NotDefined" 1 "On" 0 "Off_IsolatedFromCTIPressCtrl" ;
VAL_ 2566845694 CTIWheelSensorStatus_12 3 "NotSupported" 2 "NotDefined" 1 "On" 0 "Off_IsolatedFromCTIPressCtrl" ;
VAL_ 2566845694 CTIWheelSensorStatus_11 3 "NotSupported" 2 "NotDefined" 1 "On" 0 "Off_IsolatedFromCTIPressCtrl" ;
VAL_ 2566845694 CTIWheelSensorStatus_10 3 "NotSupported" 2 "NotDefined" 1 "On" 0 "Off_IsolatedFromCTIPressCtrl" ;
VAL_ 2566845694 CTIWheelSensorStatus_01 3 "NotSupported" 2 "NotDefined" 1 "On" 0 "Off_IsolatedFromCTIPressCtrl" ;
VAL_ 2566845694 CTIWheelEndElectricalFault_33 3 "NotSupported" 2 "Error" 1 "NotDefined" 0 "Ok" ;
VAL_ 2566845694 CTIWheelEndElectricalFault_32 3 "NotSupported" 2 "Error" 1 "NotDefined" 0 "Ok" ;
VAL_ 2566845694 CTIWheelEndElectricalFault_31 3 "NotSupported" 2 "Error" 1 "NotDefined" 0 "Ok" ;
VAL_ 2566845694 CTIWheelEndElectricalFault_30 3 "NotSupported" 2 "Error" 1 "NotDefined" 0 "Ok" ;
VAL_ 2566845694 CTIWheelEndElectricalFault_23 3 "NotSupported" 2 "Error" 1 "NotDefined" 0 "Ok" ;
VAL_ 2566845694 CTIWheelEndElectricalFault_22 3 "NotSupported" 2 "Error" 1 "NotDefined" 0 "Ok" ;
VAL_ 2566845694 CTIWheelEndElectricalFault_21 3 "NotSupported" 2 "Error" 1 "NotDefined" 0 "Ok" ;
VAL_ 2566845694 CTIWheelEndElectricalFault_20 3 "NotSupported" 2 "Error" 1 "NotDefined" 0 "Ok" ;
VAL_ 2566845694 CTIWheelEndElectricalFault_13 3 "NotSupported" 2 "Error" 1 "NotDefined" 0 "Ok" ;
VAL_ 2566845694 CTIWheelEndElectricalFault_12 3 "NotSupported" 2 "Error" 1 "NotDefined" 0 "Ok" ;
VAL_ 2566845694 CTIWheelEndElectricalFault_11 3 "NotSupported" 2 "Error" 1 "NotDefined" 0 "Ok" ;
VAL_ 2566845694 CTIWheelEndElectricalFault_10 3 "NotSupported" 2 "Error" 1 "NotDefined" 0 "Ok" ;
VAL_ 2566845694 CTIWheelEndElectricalFault_01 3 "NotSupported" 2 "Error" 1 "NotDefined" 0 "Ok" ;
VAL_ 2566845694 CTITireStatus_33 3 "NotSupported" 2 "Error" 1 "TireLeakDetected" 0 "Ok" ;
VAL_ 2566845694 CTITireStatus_32 3 "NotSupported" 2 "Error" 1 "TireLeakDetected" 0 "Ok" ;
VAL_ 2566845694 CTITireStatus_31 3 "NotSupported" 2 "Error" 1 "TireLeakDetected" 0 "Ok" ;
VAL_ 2566845694 CTITireStatus_30 3 "NotSupported" 2 "Error" 1 "TireLeakDetected" 0 "Ok" ;
VAL_ 2566845694 CTITireStatus_23 3 "NotSupported" 2 "Error" 1 "TireLeakDetected" 0 "Ok" ;
VAL_ 2566845694 CTITireStatus_22 3 "NotSupported" 2 "Error" 1 "TireLeakDetected" 0 "Ok" ;
VAL_ 2566845694 CTITireStatus_21 3 "NotSupported" 2 "Error" 1 "TireLeakDetected" 0 "Ok" ;
VAL_ 2566845694 CTITireStatus_20 3 "NotSupported" 2 "Error" 1 "TireLeakDetected" 0 "Ok" ;
VAL_ 2566845694 CTITireStatus_13 3 "NotSupported" 2 "Error" 1 "TireLeakDetected" 0 "Ok" ;
VAL_ 2566845694 CTITireStatus_12 3 "NotSupported" 2 "Error" 1 "TireLeakDetected" 0 "Ok" ;
VAL_ 2566845694 CTITireStatus_11 3 "NotSupported" 2 "Error" 1 "TireLeakDetected" 0 "Ok" ;
VAL_ 2566845694 CTITireStatus_10 3 "NotSupported" 2 "Error" 1 "TireLeakDetected" 0 "Ok" ;
VAL_ 2566845694 CTITireStatus_01 3 "NotSupported" 2 "Error" 1 "TireLeakDetected" 0 "Ok" ;
VAL_ 2566845694 TirePressThresholdDetection_33 7 "NotAvailable" 6 "ErrorIndicator" 5 "NotDefined" 4 "ExtrmUndrPrssTrPrssrIsAtALvlWhr" 3 "UndrPrssTrPrssrIsLwrThnThPrssrD" 2 "NWrnngPrssTrPrssrIsWthnThThrshl" 1 "OvrPrssTrPrssrIsHghrThnThPrssrD" 0 "ExtrmOvrPrssTrPrssrIsAtALvlWhrT" ;
VAL_ 2566845694 TirePressThresholdDetection_32 7 "NotAvailable" 6 "ErrorIndicator" 5 "NotDefined" 4 "ExtrmUndrPrssTrPrssrIsAtALvlWhr" 3 "UndrPrssTrPrssrIsLwrThnThPrssrD" 2 "NWrnngPrssTrPrssrIsWthnThThrshl" 1 "OvrPrssTrPrssrIsHghrThnThPrssrD" 0 "ExtrmOvrPrssTrPrssrIsAtALvlWhrT" ;
VAL_ 2566845694 TirePressThresholdDetection_31 7 "NotAvailable" 6 "ErrorIndicator" 5 "NotDefined" 4 "ExtrmUndrPrssTrPrssrIsAtALvlWhr" 3 "UndrPrssTrPrssrIsLwrThnThPrssrD" 2 "NWrnngPrssTrPrssrIsWthnThThrshl" 1 "OvrPrssTrPrssrIsHghrThnThPrssrD" 0 "ExtrmOvrPrssTrPrssrIsAtALvlWhrT" ;
VAL_ 2566845694 TirePressThresholdDetection_30 7 "NotAvailable" 6 "ErrorIndicator" 5 "NotDefined" 4 "ExtrmUndrPrssTrPrssrIsAtALvlWhr" 3 "UndrPrssTrPrssrIsLwrThnThPrssrD" 2 "NWrnngPrssTrPrssrIsWthnThThrshl" 1 "OvrPrssTrPrssrIsHghrThnThPrssrD" 0 "ExtrmOvrPrssTrPrssrIsAtALvlWhrT" ;
VAL_ 2566845694 TirePressThresholdDetection_23 7 "NotAvailable" 6 "ErrorIndicator" 5 "NotDefined" 4 "ExtrmUndrPrssTrPrssrIsAtALvlWhr" 3 "UndrPrssTrPrssrIsLwrThnThPrssrD" 2 "NWrnngPrssTrPrssrIsWthnThThrshl" 1 "OvrPrssTrPrssrIsHghrThnThPrssrD" 0 "ExtrmOvrPrssTrPrssrIsAtALvlWhrT" ;
VAL_ 2566845694 TirePressThresholdDetection_22 7 "NotAvailable" 6 "ErrorIndicator" 5 "NotDefined" 4 "ExtrmUndrPrssTrPrssrIsAtALvlWhr" 3 "UndrPrssTrPrssrIsLwrThnThPrssrD" 2 "NWrnngPrssTrPrssrIsWthnThThrshl" 1 "OvrPrssTrPrssrIsHghrThnThPrssrD" 0 "ExtrmOvrPrssTrPrssrIsAtALvlWhrT" ;
VAL_ 2566845694 TirePressThresholdDetection_21 7 "NotAvailable" 6 "ErrorIndicator" 5 "NotDefined" 4 "ExtrmUndrPrssTrPrssrIsAtALvlWhr" 3 "UndrPrssTrPrssrIsLwrThnThPrssrD" 2 "NWrnngPrssTrPrssrIsWthnThThrshl" 1 "OvrPrssTrPrssrIsHghrThnThPrssrD" 0 "ExtrmOvrPrssTrPrssrIsAtALvlWhrT" ;
VAL_ 2566845694 TirePressThresholdDetection_20 7 "NotAvailable" 6 "ErrorIndicator" 5 "NotDefined" 4 "ExtrmUndrPrssTrPrssrIsAtALvlWhr" 3 "UndrPrssTrPrssrIsLwrThnThPrssrD" 2 "NWrnngPrssTrPrssrIsWthnThThrshl" 1 "OvrPrssTrPrssrIsHghrThnThPrssrD" 0 "ExtrmOvrPrssTrPrssrIsAtALvlWhrT" ;
VAL_ 2566845694 TirePressThresholdDetection_00 7 "NotAvailable" 6 "ErrorIndicator" 5 "NotDefined" 4 "ExtrmUndrPrssTrPrssrIsAtALvlWhr" 3 "UndrPrssTrPrssrIsLwrThnThPrssrD" 2 "NWrnngPrssTrPrssrIsWthnThThrshl" 1 "OvrPrssTrPrssrIsHghrThnThPrssrD" 0 "ExtrmOvrPrssTrPrssrIsAtALvlWhrT" ;
VAL_ 2566845694 CTIWheelSensorStatus_00 3 "NotSupported" 2 "NotDefined" 1 "On" 0 "Off_IsolatedFromCTIPressCtrl" ;
VAL_ 2566845694 CTIWheelEndElectricalFault_00 3 "NotSupported" 2 "Error" 1 "NotDefined" 0 "Ok" ;
VAL_ 2566845694 CTITireStatus_00 3 "NotSupported" 2 "Error" 1 "TireLeakDetected" 0 "Ok" ;
VAL_ 2566821630 EngTrbWstgateActuator1TempStatus 7 "Not available" 6 "Error" 5 "Not Defined" 4 "Low Most severe" 3 "Low Least severe" 2 "In Range" 1 "High Least severe" 0 "High Most severe" ;
VAL_ 2365484286 DirectionIndicator 3 "Not available" 2 "Error" 1 "Reverse" 0 "Forward" ;
VAL_ 2365484286 TachographPerformance 3 "Not available" 2 "Error" 1 "Performance analysis" 0 "Normal performance" ;
VAL_ 2365484286 HandlingInformation 3 "Not available" 2 "Error" 1 "Handling information" 0 "No handling information" ;
VAL_ 2365484286 SystemEvent 3 "Not available" 2 "Error" 1 "Tachograph event" 0 "No tachograph event" ;
VAL_ 2365484286 DriverCardDriver2 3 "Not available" 2 "Error" 1 "Driver card present" 0 "Driver card not present" ;
VAL_ 2365484286 Driver2TimeRelatedStates 15 "Not available" 14 "Error" 13 "Other" 6 "Limit 6  16 h reached" 5 "Limit 5  15 min before 16 h not having 8h rest during the last 24h" 4 "Limit 4  9 h reached" 3 "Limit 3  15 min before 9 h" 2 "Limit 2  4  h reached" 1 "Limit 1  15 min before 4  h" 0 "Normal/No limits reached" ;
VAL_ 2365484286 VehicleOverspeed 3 "Not available" 2 "Error" 1 "Overspeed" 0 "No overspeed" ;
VAL_ 2365484286 DriverCardDriver1 3 "Not available" 2 "Error" 1 "Driver card present" 0 "Driver card not present" ;
VAL_ 2365484286 Driver1TimeRelatedStates 15 "Not available" 14 "Error" 13 "Other" 6 "Limit 6  16 h reached" 5 "Limit 5  15 min before 16 h not having 8h rest during the last 24h" 4 "Limit 4  9 h reached" 3 "Limit 3  15 min before 9 h" 2 "Limit 2  4  h reached" 1 "Limit 1  15 min before 4  h" 0 "Normal/No limits reached" ;
VAL_ 2365484286 VehicleMotion 3 "Not available" 2 "Error" 1 "Vehicle motion detected" 0 "Vehicle motion not detected" ;
VAL_ 2365484286 Driver2WorkingState 7 "Not available" 6 "Error" 3 "Drive  behind wheel" 2 "Work  loading unloading working in an office" 1 "Driver available  short break" 0 "Rest  sleeping" ;
VAL_ 2365484286 Driver1WorkingState 7 "Not available" 6 "Error" 3 "Drive  behind wheel" 2 "Work  loading unloading working in an office" 1 "Driver available  short break" 0 "Rest  sleeping" ;
